VERSION "created by canmatrix"

NS_ :

BS_:

BU_: IPD

BO_ 992 CCU_PTCANFD_100ms_FrP07: 24 Vector__XXX
 SG_ ICCU_100ms_Group07_CRC : 7|8@0+ (1,0) [0|255] "null" IPD
 SG_ ICCU_100ms_Group07_RC : 11|4@0+ (1,0) [0|15] "null" IPD
 SG_ ICCUOnbdChrgrPlugOnV : 12|1@0+ (1,0) [0|1] "null" IPD
 SG_ ICCU_100ms_Group07_Reserved1 : 15|3@0+ (1,0) [0|7] "null" IPD
 SG_ IOnBdChrgrCtrlPilotPWMSts : 18|3@0+ (1,0) [0|7] "null" IPD
 SG_ IOnBdChrgrWkup : 19|1@0+ (1,0) [0|1] "null" IPD
 SG_ IOnBdChrgrSts : 23|4@0+ (1,0) [0|15] "null" IPD
 SG_ IOnbdChrgrAltrCrntInptHVCrntLmt : 31|8@0+ (0.5,0) [0|127.5] "A" IPD
 SG_ ICCU_100ms_Group07_Reserved3 : 32|1@0+ (1,0) [0|1] "null" IPD
 SG_ IOnbdChrgrOtptCrntV : 33|1@0+ (1,0) [0|1] "null" IPD
 SG_ IOnbdChrgrOpngMd : 36|3@0+ (1,0) [0|7] "null" IPD
 SG_ ICCU_100ms_Group07_Reserved2 : 39|3@0+ (1,0) [0|7] "null" IPD
 SG_ IOnBdChrgrAltrCrntInptCrnt : 47|8@0+ (0.2,0) [0|51] "A" IPD
 SG_ IOnBdChrgrAltrCrntInptVol : 55|8@0+ (2,0) [0|510] "V" IPD
 SG_ IOnbdChrgrOtptCrntVal : 63|12@0+ (0.1,-204.8) [-204.8|204.7] "A" IPD
 SG_ ICCU_100ms_Group07_Reserved4 : 66|3@0+ (1,0) [0|7] "null" IPD
 SG_ IOnBdChrgrOtptVolV : 67|1@0+ (1,0) [0|1] "null" IPD
 SG_ IOnbdChrgrOtptVolVal : 79|16@0+ (0.02,0) [0.00|1310.70] "V" IPD
 SG_ IOnBdChrgrL1AltrCrntInptCrnt : 95|8@0+ (0.2,0) [0|51] "A" IPD
 SG_ IOnBdChrgrL1AltrCrntInptVol : 103|8@0+ (2,0) [0|510] "V" IPD
 SG_ IOnBdChrgrL2AltrCrntInptCrnt : 111|8@0+ (0.2,0) [0|51] "A" IPD
 SG_ IOnBdChrgrL2AltrCrntInptVol : 119|8@0+ (2,0) [0|510] "V" IPD
 SG_ IOnBdChrgrL3AltrCrntInptCrnt : 127|8@0+ (0.2,0) [0|51] "A" IPD
 SG_ IOnBdChrgrL3AltrCrntInptVol : 135|8@0+ (2,0) [0|510] "V" IPD
 SG_ ICCUActiveWkup : 136|1@0+ (1,0) [0|1] "null" IPD
 SG_ ICCUonbdChrgrMaxChrgPwr : 143|7@0+ (0.1,0) [0|12.7] "kw" IPD
 SG_ ICCU_100ms_Group07_Reserved5 : 147|4@0+ (1,0) [0|15] "null" IPD
 SG_ ICCUOnbdChrgrPlugOn : 151|4@0+ (1,0) [0|15] "null" IPD
 SG_ ICCU_100ms_Group07_Reserved6 : 155|4@0+ (1,0) [0|15] "null" IPD
 SG_ ICCUOnbdChrgrSpRsn : 159|4@0+ (1,0) [0|15] "null" IPD
 SG_ ICCU_100ms_Group07_Reserved7 : 167|8@0+ (1,0) [0|255] "null" IPD
 SG_ ICCU_100ms_Group07_Reserved9 : 169|2@0+ (1,0) [0|3] "null" IPD
 SG_ IOnBdChrgrLastWkup : 170|1@0+ (1,0) [0|1] "null" IPD
 SG_ ICCU_100ms_Group07_Reserved8 : 175|5@0+ (1,0) [0|31] "null" IPD
 SG_ ICCU_100ms_Group07_Reserved10 : 176|1@0+ (1,0) [0|1] "null" IPD
 SG_ IOnBdChrgrCtrlPilotPWMDuty : 183|7@0+ (1,0) [0|127] "Percent" IPD
 SG_ ICCU_100ms_Group07_Reserved11 : 191|8@0+ (1,0) [0|255] "null" IPD

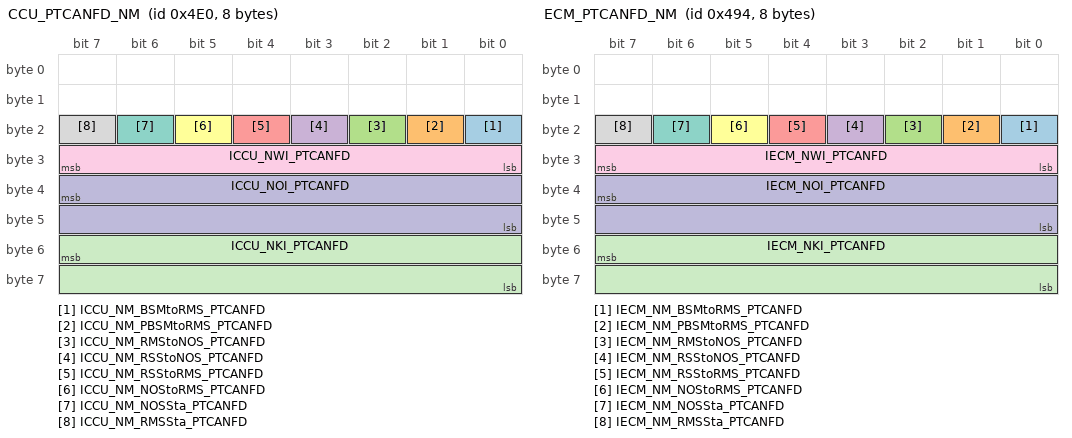
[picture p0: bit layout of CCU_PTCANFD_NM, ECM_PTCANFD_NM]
BO_ 1248 CCU_PTCANFD_NM: 8 Vector__XXX
 SG_ ICCU_NM_BSMtoRMS_PTCANFD : 16|1@0+ (1,0) [0|1] "null" Vector__XXX
 SG_ ICCU_NM_PBSMtoRMS_PTCANFD : 17|1@0+ (1,0) [0|1] "null" Vector__XXX
 SG_ ICCU_NM_RMStoNOS_PTCANFD : 18|1@0+ (1,0) [0|1] "null" Vector__XXX
 SG_ ICCU_NM_RSStoNOS_PTCANFD : 19|1@0+ (1,0) [0|1] "null" Vector__XXX
 SG_ ICCU_NM_RSStoRMS_PTCANFD : 20|1@0+ (1,0) [0|1] "null" Vector__XXX
 SG_ ICCU_NM_NOStoRMS_PTCANFD : 21|1@0+ (1,0) [0|1] "null" Vector__XXX
 SG_ ICCU_NM_NOSSta_PTCANFD : 22|1@0+ (1,0) [0|1] "null" Vector__XXX
 SG_ ICCU_NM_RMSSta_PTCANFD : 23|1@0+ (1,0) [0|1] "null" Vector__XXX
 SG_ ICCU_NWI_PTCANFD : 31|8@0+ (1,0) [0|255] "null" Vector__XXX
 SG_ ICCU_NOI_PTCANFD : 39|16@0+ (1,0) [0|65535] "null" Vector__XXX
 SG_ ICCU_NKI_PTCANFD : 55|16@0+ (1,0) [0|65535] "null" Vector__XXX

BO_ 1172 ECM_PTCANFD_NM: 8 Vector__XXX
 SG_ IECM_NM_BSMtoRMS_PTCANFD : 16|1@0+ (1,0) [0|1] "null" Vector__XXX
 SG_ IECM_NM_PBSMtoRMS_PTCANFD : 17|1@0+ (1,0) [0|1] "null" Vector__XXX
 SG_ IECM_NM_RMStoNOS_PTCANFD : 18|1@0+ (1,0) [0|1] "null" Vector__XXX
 SG_ IECM_NM_RSStoNOS_PTCANFD : 19|1@0+ (1,0) [0|1] "null" Vector__XXX
 SG_ IECM_NM_RSStoRMS_PTCANFD : 20|1@0+ (1,0) [0|1] "null" Vector__XXX
 SG_ IECM_NM_NOStoRMS_PTCANFD : 21|1@0+ (1,0) [0|1] "null" Vector__XXX
 SG_ IECM_NM_NOSSta_PTCANFD : 22|1@0+ (1,0) [0|1] "null" Vector__XXX
 SG_ IECM_NM_RMSSta_PTCANFD : 23|1@0+ (1,0) [0|1] "null" Vector__XXX
 SG_ IECM_NWI_PTCANFD : 31|8@0+ (1,0) [0|255] "null" Vector__XXX
 SG_ IECM_NOI_PTCANFD : 39|16@0+ (1,0) [0|65535] "null" Vector__XXX
 SG_ IECM_NKI_PTCANFD : 55|16@0+ (1,0) [0|65535] "null" Vector__XXX

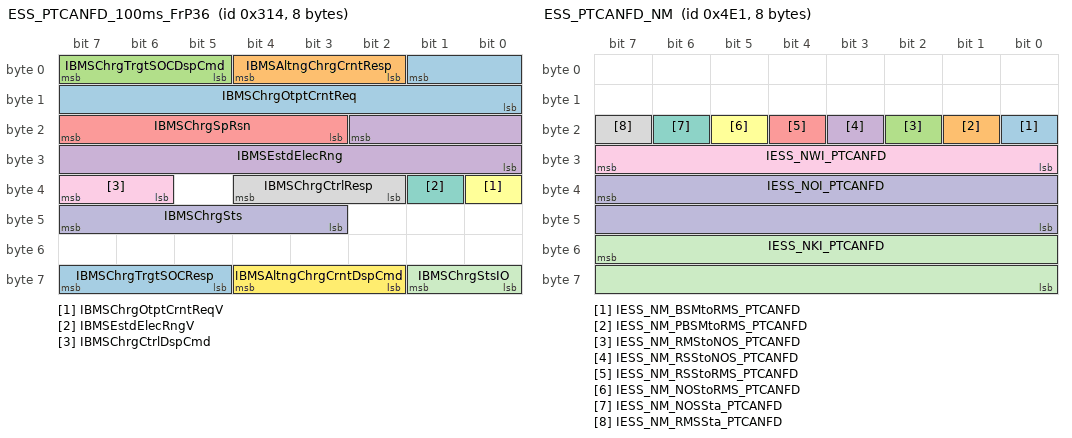
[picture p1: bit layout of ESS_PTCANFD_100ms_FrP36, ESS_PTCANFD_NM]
BO_ 788 ESS_PTCANFD_100ms_FrP36: 8 Vector__XXX
 SG_ IBMSChrgOtptCrntReq : 1|10@0+ (0.5,0) [0|511.5] "A" Vector__XXX
 SG_ IBMSAltngChrgCrntResp : 4|3@0+ (1,0) [0|7] "null" Vector__XXX
 SG_ IBMSChrgTrgtSOCDspCmd : 7|3@0+ (1,0) [0|7] "null" Vector__XXX
 SG_ IBMSEstdElecRng : 18|11@0+ (1,0) [0|2047] "km" Vector__XXX
 SG_ IBMSChrgSpRsn : 23|5@0+ (1,0) [0|31] "null" Vector__XXX
 SG_ IBMSChrgOtptCrntReqV : 32|1@0+ (1,0) [0|1] "null" Vector__XXX
 SG_ IBMSEstdElecRngV : 33|1@0+ (1,0) [0|1] "null" Vector__XXX
 SG_ IBMSChrgCtrlResp : 36|3@0+ (1,0) [0|7] "null" Vector__XXX
 SG_ IBMSChrgCtrlDspCmd : 39|2@0+ (1,0) [0|3] "null" Vector__XXX
 SG_ IBMSChrgSts : 47|5@0+ (1,0) [0|31] "null" IPD
 SG_ IBMSChrgStsIO : 57|2@0+ (1,0) [0|3] "null" Vector__XXX
 SG_ IBMSAltngChrgCrntDspCmd : 60|3@0+ (1,0) [0|7] "null" Vector__XXX
 SG_ IBMSChrgTrgtSOCResp : 63|3@0+ (1,0) [0|7] "null" Vector__XXX

BO_ 1249 ESS_PTCANFD_NM: 8 Vector__XXX
 SG_ IESS_NM_BSMtoRMS_PTCANFD : 16|1@0+ (1,0) [0|1] "null" Vector__XXX
 SG_ IESS_NM_PBSMtoRMS_PTCANFD : 17|1@0+ (1,0) [0|1] "null" Vector__XXX
 SG_ IESS_NM_RMStoNOS_PTCANFD : 18|1@0+ (1,0) [0|1] "null" Vector__XXX
 SG_ IESS_NM_RSStoNOS_PTCANFD : 19|1@0+ (1,0) [0|1] "null" Vector__XXX
 SG_ IESS_NM_RSStoRMS_PTCANFD : 20|1@0+ (1,0) [0|1] "null" Vector__XXX
 SG_ IESS_NM_NOStoRMS_PTCANFD : 21|1@0+ (1,0) [0|1] "null" Vector__XXX
 SG_ IESS_NM_NOSSta_PTCANFD : 22|1@0+ (1,0) [0|1] "null" Vector__XXX
 SG_ IESS_NM_RMSSta_PTCANFD : 23|1@0+ (1,0) [0|1] "null" Vector__XXX
 SG_ IESS_NWI_PTCANFD : 31|8@0+ (1,0) [0|255] "null" Vector__XXX
 SG_ IESS_NOI_PTCANFD : 39|16@0+ (1,0) [0|65535] "null" Vector__XXX
 SG_ IESS_NKI_PTCANFD : 55|16@0+ (1,0) [0|65535] "null" Vector__XXX

BO_ 895 ICBAD_BKPCANFD_100ms_FrP36: 16 IPD
 SG_ INarwSpcAstSwSts : 9|2@0+ (1,0) [0|3] "null" Vector__XXX
 SG_ INarwSpcAstBtnSts : 23|3@0+ (1,0) [0|7] "null" Vector__XXX
 SG_ IIPD_VehLckCtrlReq : 31|8@0+ (1,0) [0|255] "null" Vector__XXX
 SG_ IRembParkngInPrmt : 40|1@0+ (1,0) [0|1] "null" Vector__XXX
 SG_ IRembParkngInMapngResp : 41|1@0+ (1,0) [0|1] "null" Vector__XXX
 SG_ IRembParkngInPrmtSwSts : 49|2@0+ (1,0) [0|3] "null" Vector__XXX
 SG_ IRembParkngInMapngIndcr : 60|3@0+ (1,0) [0|7] "null" Vector__XXX
 SG_ IRembParkngInMapRutSeln : 63|3@0+ (1,0) [0|7] "null" Vector__XXX
 SG_ IIPDMCUTemp : 71|8@0+ (1,-40) [-40|215] "℃" Vector__XXX
 SG_ IIPDWtrClntInltReqFlg : 79|1@0+ (1,0) [0|1] "null" Vector__XXX
 SG_ ITrfGreenLghtActn : 103|1@0+ (1,0) [0|1] "null" Vector__XXX
 SG_ IRembParkngInMapngRutID : 108|5@0+ (1,0) [0|31] "null" Vector__XXX
 SG_ IRembParkngInMapngDistToEnd : 119|9@0+ (0.5,0) [0|255.5] "null" Vector__XXX
 SG_ IRembParkngInMapRutDltSeln : 126|4@0+ (1,0) [0|15] "null" Vector__XXX

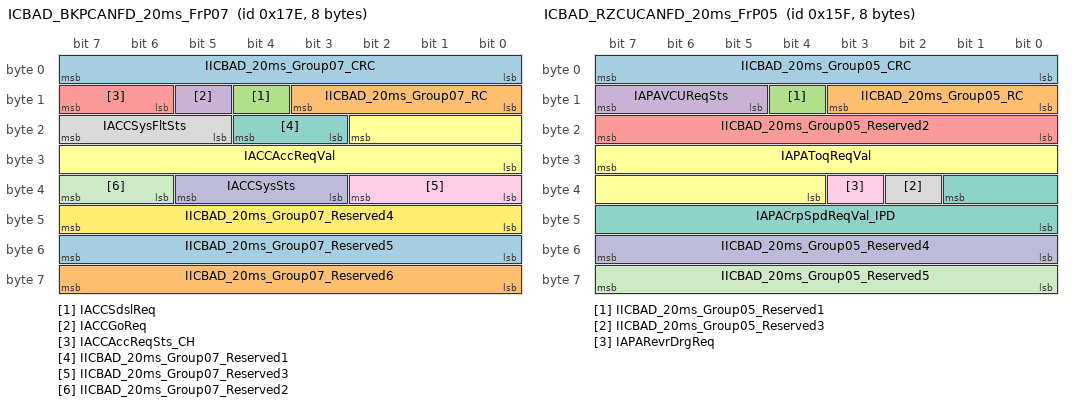
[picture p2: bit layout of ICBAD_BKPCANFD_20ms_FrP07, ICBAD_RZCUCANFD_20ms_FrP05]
BO_ 382 ICBAD_BKPCANFD_20ms_FrP07: 8 IPD
 SG_ IICBAD_20ms_Group07_CRC : 7|8@0+ (1,0) [0|255] "null" Vector__XXX
 SG_ IICBAD_20ms_Group07_RC : 11|4@0+ (1,0) [0|15] "null" Vector__XXX
 SG_ IACCSdslReq : 12|1@0+ (1,0) [0|1] "null" Vector__XXX
 SG_ IACCGoReq : 13|1@0+ (1,0) [0|1] "null" Vector__XXX
 SG_ IACCAccReqSts_CH : 15|2@0+ (1,0) [0|3] "null" Vector__XXX
 SG_ IACCAccReqVal : 18|11@0+ (0.006,-10.278) [-10.278|2.004] "null" Vector__XXX
 SG_ IICBAD_20ms_Group07_Reserved1 : 20|2@0+ (1,0) [0|3] "null" Vector__XXX
 SG_ IACCSysFltSts : 23|3@0+ (1,0) [0|7] "null" Vector__XXX
 SG_ IICBAD_20ms_Group07_Reserved3 : 34|3@0+ (1,0) [0|7] "null" Vector__XXX
 SG_ IACCSysSts : 37|3@0+ (1,0) [0|7] "null" Vector__XXX
 SG_ IICBAD_20ms_Group07_Reserved2 : 39|2@0+ (1,0) [0|3] "null" Vector__XXX
 SG_ IICBAD_20ms_Group07_Reserved4 : 47|8@0+ (1,0) [0|255] "null" Vector__XXX
 SG_ IICBAD_20ms_Group07_Reserved5 : 55|8@0+ (1,0) [0|255] "null" Vector__XXX
 SG_ IICBAD_20ms_Group07_Reserved6 : 63|8@0+ (1,0) [0|255] "null" Vector__XXX

BO_ 736 ICBAD_BKPCANFD_50ms_FrP17: 20 IPD
 SG_ IFrtObsDist : 7|8@0+ (1,0) [0|255] "cm" Vector__XXX
 SG_ IFrtMidRObsRng : 11|4@0+ (1,0) [0|15] "null" Vector__XXX
 SG_ IFrtPDCAudWrnng : 15|4@0+ (1,0) [0|15] "null" Vector__XXX
 SG_ IRrMidLObsRng : 19|4@0+ (1,0) [0|15] "null" Vector__XXX
 SG_ IRLObsRng : 23|4@0+ (1,0) [0|15] "null" Vector__XXX
 SG_ IRrMidRObsRng : 31|4@0+ (1,0) [0|15] "null" Vector__XXX
 SG_ IPDCSysSts : 39|4@0+ (1,0) [0|15] "null" Vector__XXX
 SG_ IRrObsDist : 63|8@0+ (1,0) [0|255] "cm" Vector__XXX
 SG_ IFLSideObsRng : 67|4@0+ (1,0) [0|15] "null" Vector__XXX
 SG_ IRrPDCAudWrnng : 71|4@0+ (1,0) [0|15] "null" Vector__XXX
 SG_ IRLSideObsRng : 75|4@0+ (1,0) [0|15] "null" Vector__XXX
 SG_ IFRSideObsRng : 79|4@0+ (1,0) [0|15] "null" Vector__XXX
 SG_ IUndergndParkngGrgSts : 83|2@0+ (1,0) [0|3] "null" Vector__XXX
 SG_ IRRSideObsRng : 87|4@0+ (1,0) [0|15] "null" Vector__XXX
 SG_ IFLObsRng : 123|4@0+ (1,0) [0|15] "null" Vector__XXX
 SG_ IRRObsRng : 131|4@0+ (1,0) [0|15] "null" Vector__XXX
 SG_ IFRObsRng : 135|4@0+ (1,0) [0|15] "null" Vector__XXX
 SG_ ILADSAFnInd : 139|4@0+ (1,0) [0|15] "null" Vector__XXX
 SG_ IFrtMidLObsRng : 143|4@0+ (1,0) [0|15] "null" Vector__XXX
 SG_ IFRSObsRng : 147|4@0+ (1,0) [0|15] "null" Vector__XXX
 SG_ IFLSObsRng : 151|4@0+ (1,0) [0|15] "null" Vector__XXX
 SG_ IRRSObsRng : 155|4@0+ (1,0) [0|15] "null" Vector__XXX
 SG_ IRLSObsRng : 159|4@0+ (1,0) [0|15] "null" Vector__XXX

BO_ 351 ICBAD_RZCUCANFD_20ms_FrP05: 8 IPD
 SG_ IICBAD_20ms_Group05_CRC : 7|8@0+ (1,0) [0|255] "null" Vector__XXX
 SG_ IICBAD_20ms_Group05_RC : 11|4@0+ (1,0) [0|15] "null" Vector__XXX
 SG_ IICBAD_20ms_Group05_Reserved1 : 12|1@0+ (1,0) [0|1] "null" Vector__XXX
 SG_ IAPAVCUReqSts : 15|3@0+ (1,0) [0|7] "null" Vector__XXX
 SG_ IICBAD_20ms_Group05_Reserved2 : 23|8@0+ (1,0) [0|255] "null" Vector__XXX
 SG_ IAPAToqReqVal : 31|12@0+ (0.5,-848) [-848|1199.5] "Nm" Vector__XXX
 SG_ IAPACrpSpdReqVal_IPD : 33|10@0+ (0.1,0) [0|102.3] "km/h" Vector__XXX
 SG_ IICBAD_20ms_Group05_Reserved3 : 34|1@0+ (1,0) [0|1] "null" Vector__XXX
 SG_ IAPARevrDrgReq : 35|1@0+ (1,0) [0|1] "null" Vector__XXX
 SG_ IICBAD_20ms_Group05_Reserved4 : 55|8@0+ (1,0) [0|255] "null" Vector__XXX
 SG_ IICBAD_20ms_Group05_Reserved5 : 63|8@0+ (1,0) [0|255] "null" Vector__XXX

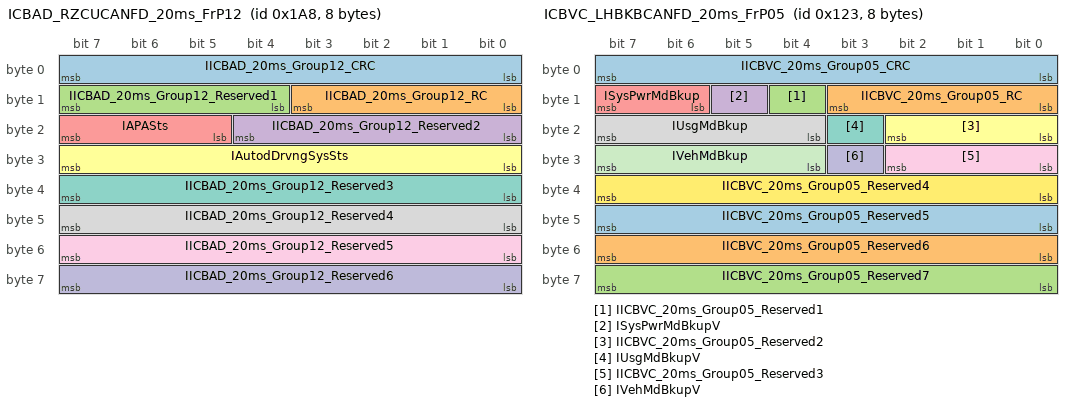
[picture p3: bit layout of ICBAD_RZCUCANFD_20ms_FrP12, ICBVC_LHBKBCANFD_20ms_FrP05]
BO_ 424 ICBAD_RZCUCANFD_20ms_FrP12: 8 IPD
 SG_ IICBAD_20ms_Group12_CRC : 7|8@0+ (1,0) [0|255] "null" Vector__XXX
 SG_ IICBAD_20ms_Group12_RC : 11|4@0+ (1,0) [0|15] "null" Vector__XXX
 SG_ IICBAD_20ms_Group12_Reserved1 : 15|4@0+ (1,0) [0|15] "null" Vector__XXX
 SG_ IICBAD_20ms_Group12_Reserved2 : 20|5@0+ (1,0) [0|31] "null" Vector__XXX
 SG_ IAPASts : 23|3@0+ (1,0) [0|7] "null" Vector__XXX
 SG_ IAutodDrvngSysSts : 31|8@0+ (1,0) [0|255] "null" Vector__XXX
 SG_ IICBAD_20ms_Group12_Reserved3 : 39|8@0+ (1,0) [0|255] "null" Vector__XXX
 SG_ IICBAD_20ms_Group12_Reserved4 : 47|8@0+ (1,0) [0|255] "null" Vector__XXX
 SG_ IICBAD_20ms_Group12_Reserved5 : 55|8@0+ (1,0) [0|255] "null" Vector__XXX
 SG_ IICBAD_20ms_Group12_Reserved6 : 63|8@0+ (1,0) [0|255] "null" Vector__XXX

BO_ 431 ICBAD_RZCUCANFD_20ms_FrP15: 16 IPD
 SG_ IICBAD_20ms_Group15_CRC : 7|8@0+ (1,0) [0|255] "null" Vector__XXX
 SG_ IICBAD_20ms_Group15_RC : 11|4@0+ (1,0) [0|15] "null" Vector__XXX
 SG_ IACCDclReqSts : 13|2@0+ (1,0) [0|3] "null" Vector__XXX
 SG_ IICBAD_20ms_Group15_Reserved1 : 15|2@0+ (1,0) [0|3] "null" Vector__XXX
 SG_ IICBAD_20ms_Group15_Reserved2 : 23|8@0+ (1,0) [0|255] "null" Vector__XXX
 SG_ IACCOtptShaftTotToqReqVal : 31|12@0+ (2,-3392) [-3392|4798] "Nm" Vector__XXX
 SG_ IICBAD_20ms_Group15_Reserved3 : 33|2@0+ (1,0) [0|3] "null" Vector__XXX
 SG_ IACCOtptShaftTotToqReqSts : 35|2@0+ (1,0) [0|3] "null" Vector__XXX
 SG_ IICBAD_20ms_Group15_Reserved4 : 47|8@0+ (1,0) [0|255] "null" Vector__XXX
 SG_ IICBAD_20ms_Group15_Reserved5 : 55|8@0+ (1,0) [0|255] "null" Vector__XXX
 SG_ IICBAD_20ms_Group15_Reserved6 : 63|8@0+ (1,0) [0|255] "null" Vector__XXX
 SG_ IICBAD_20ms_Group15_Reserved7 : 71|8@0+ (1,0) [0|255] "null" Vector__XXX
 SG_ IICBAD_20ms_Group15_Reserved8 : 79|8@0+ (1,0) [0|255] "null" Vector__XXX
 SG_ IICBAD_20ms_Group15_Reserved9 : 87|8@0+ (1,0) [0|255] "null" Vector__XXX
 SG_ IICBAD_20ms_Group15_Reserved10 : 95|8@0+ (1,0) [0|255] "null" Vector__XXX

BO_ 291 ICBVC_LHBKBCANFD_20ms_FrP05: 8 Vector__XXX
 SG_ IICBVC_20ms_Group05_CRC : 7|8@0+ (1,0) [0|255] "null" IPD
 SG_ IICBVC_20ms_Group05_RC : 11|4@0+ (1,0) [0|15] "null" IPD
 SG_ IICBVC_20ms_Group05_Reserved1 : 12|1@0+ (1,0) [0|1] "null" IPD
 SG_ ISysPwrMdBkupV : 13|1@0+ (1,0) [0|1] "null" IPD
 SG_ ISysPwrMdBkup : 15|2@0+ (1,0) [0|3] "null" IPD
 SG_ IICBVC_20ms_Group05_Reserved2 : 18|3@0+ (1,0) [0|7] "null" IPD
 SG_ IUsgMdBkupV : 19|1@0+ (1,0) [0|1] "null" IPD
 SG_ IUsgMdBkup : 23|4@0+ (1,0) [0|15] "null" IPD
 SG_ IICBVC_20ms_Group05_Reserved3 : 26|3@0+ (1,0) [0|7] "null" IPD
 SG_ IVehMdBkupV : 27|1@0+ (1,0) [0|1] "null" IPD
 SG_ IVehMdBkup : 31|4@0+ (1,0) [0|15] "null" IPD
 SG_ IICBVC_20ms_Group05_Reserved4 : 39|8@0+ (1,0) [0|255] "null" IPD
 SG_ IICBVC_20ms_Group05_Reserved5 : 47|8@0+ (1,0) [0|255] "null" IPD
 SG_ IICBVC_20ms_Group05_Reserved6 : 55|8@0+ (1,0) [0|255] "null" IPD
 SG_ IICBVC_20ms_Group05_Reserved7 : 63|8@0+ (1,0) [0|255] "null" IPD

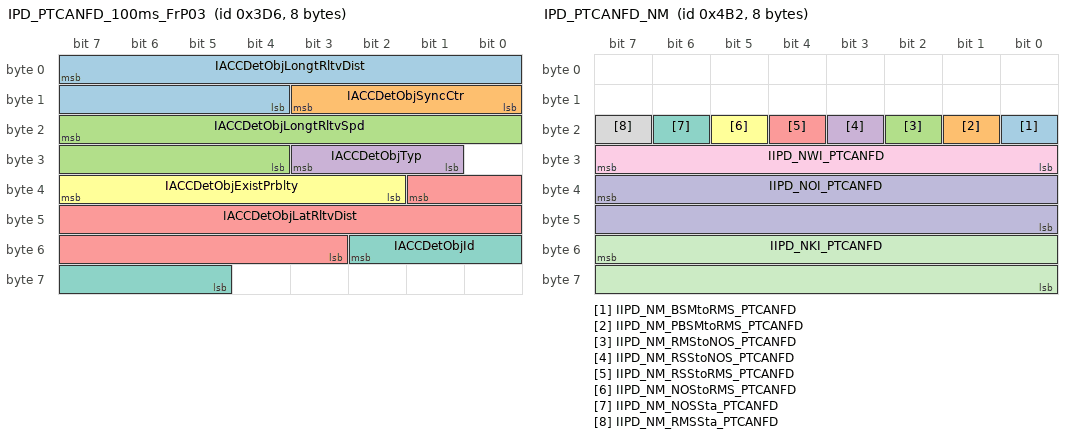
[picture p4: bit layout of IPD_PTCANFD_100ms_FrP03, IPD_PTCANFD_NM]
BO_ 982 IPD_PTCANFD_100ms_FrP03: 8 IPD
 SG_ IACCDetObjLongtRltvDist : 7|12@0+ (0.0625,0) [0.0000|255.9375] "null" Vector__XXX
 SG_ IACCDetObjSyncCtr : 11|4@0+ (1,0) [0|15] "null" Vector__XXX
 SG_ IACCDetObjLongtRltvSpd : 23|12@0+ (0.0625,-128) [-128.0000|127.9375] "null" Vector__XXX
 SG_ IACCDetObjTyp : 27|3@0+ (1,0) [0|7] "null" Vector__XXX
 SG_ IACCDetObjLatRltvDist : 33|15@0+ (0.0078,-128) [-128.0000|127.5826] "null" Vector__XXX
 SG_ IACCDetObjExistPrblty : 39|6@0+ (0.015625,0) [0.000000|0.984375] "null" Vector__XXX
 SG_ IACCDetObjId : 50|6@0+ (1,0) [0|63] "null" Vector__XXX

BO_ 1202 IPD_PTCANFD_NM: 8 IPD
 SG_ IIPD_NM_BSMtoRMS_PTCANFD : 16|1@0+ (1,0) [0|1] "null" Vector__XXX
 SG_ IIPD_NM_PBSMtoRMS_PTCANFD : 17|1@0+ (1,0) [0|1] "null" Vector__XXX
 SG_ IIPD_NM_RMStoNOS_PTCANFD : 18|1@0+ (1,0) [0|1] "null" Vector__XXX
 SG_ IIPD_NM_RSStoNOS_PTCANFD : 19|1@0+ (1,0) [0|1] "null" Vector__XXX
 SG_ IIPD_NM_RSStoRMS_PTCANFD : 20|1@0+ (1,0) [0|1] "null" Vector__XXX
 SG_ IIPD_NM_NOStoRMS_PTCANFD : 21|1@0+ (1,0) [0|1] "null" Vector__XXX
 SG_ IIPD_NM_NOSSta_PTCANFD : 22|1@0+ (1,0) [0|1] "null" Vector__XXX
 SG_ IIPD_NM_RMSSta_PTCANFD : 23|1@0+ (1,0) [0|1] "null" Vector__XXX
 SG_ IIPD_NWI_PTCANFD : 31|8@0+ (1,0) [0|255] "null" Vector__XXX
 SG_ IIPD_NOI_PTCANFD : 39|16@0+ (1,0) [0|65535] "null" Vector__XXX
 SG_ IIPD_NKI_PTCANFD : 55|16@0+ (1,0) [0|65535] "null" Vector__XXX

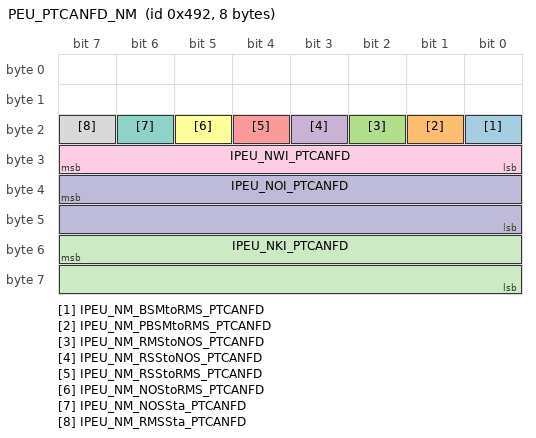
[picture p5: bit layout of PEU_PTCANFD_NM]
BO_ 1170 PEU_PTCANFD_NM: 8 Vector__XXX
 SG_ IPEU_NM_BSMtoRMS_PTCANFD : 16|1@0+ (1,0) [0|1] "null" Vector__XXX
 SG_ IPEU_NM_PBSMtoRMS_PTCANFD : 17|1@0+ (1,0) [0|1] "null" Vector__XXX
 SG_ IPEU_NM_RMStoNOS_PTCANFD : 18|1@0+ (1,0) [0|1] "null" Vector__XXX
 SG_ IPEU_NM_RSStoNOS_PTCANFD : 19|1@0+ (1,0) [0|1] "null" Vector__XXX
 SG_ IPEU_NM_RSStoRMS_PTCANFD : 20|1@0+ (1,0) [0|1] "null" Vector__XXX
 SG_ IPEU_NM_NOStoRMS_PTCANFD : 21|1@0+ (1,0) [0|1] "null" Vector__XXX
 SG_ IPEU_NM_NOSSta_PTCANFD : 22|1@0+ (1,0) [0|1] "null" Vector__XXX
 SG_ IPEU_NM_RMSSta_PTCANFD : 23|1@0+ (1,0) [0|1] "null" Vector__XXX
 SG_ IPEU_NWI_PTCANFD : 31|8@0+ (1,0) [0|255] "null" Vector__XXX
 SG_ IPEU_NOI_PTCANFD : 39|16@0+ (1,0) [0|65535] "null" Vector__XXX
 SG_ IPEU_NKI_PTCANFD : 55|16@0+ (1,0) [0|65535] "null" Vector__XXX

BO_ 983 RZCU_LHBKBCANFD_100ms_FrP38: 20 Vector__XXX
 SG_ ITCSOpngMdVMC : 18|3@0+ (1,0) [0|7] "null" Vector__XXX
 SG_ IPwrLftgtCtrlSrc : 22|4@0+ (1,0) [0|15] "null" Vector__XXX
 SG_ IACMdMotFaltSts_Rr : 27|4@0+ (1,0) [0|15] "null" Vector__XXX
 SG_ IVSEMdVMC : 30|3@0+ (1,0) [0|7] "null" Vector__XXX
 SG_ IACMdMotActPcnt_Rr : 39|8@0+ (1,0) [0|255] "Percent" Vector__XXX
 SG_ IOnBdChrgrSktNgtvSnsrTemV : 42|1@0+ (1,0) [0|1] "null" IPD
 SG_ IOfbdChrgrPstvSktTemV : 47|1@0+ (1,0) [0|1] "null" IPD
 SG_ IPwrLftgtCtrl : 51|4@0+ (1,0) [0|15] "null" Vector__XXX
 SG_ IPwrLftgtThrmlSts : 52|1@0+ (1,0) [0|1] "null" Vector__XXX
 SG_ IPwrLftgtCinchLtchCtrl : 59|1@0+ (1,0) [0|1] "null" Vector__XXX
 SG_ IPwrLftgtCinchLtchSts : 61|2@0+ (1,0) [0|3] "null" Vector__XXX
 SG_ IPwrLftgtCinchLtchThrmlSts : 62|1@0+ (1,0) [0|1] "null" Vector__XXX
 SG_ IPwrLftgtPnchSts : 63|1@0+ (1,0) [0|1] "null" Vector__XXX
 SG_ IOfbdChrgrPstvSktTem : 71|8@0+ (1,-40) [-40|215] "degreeCelsius" IPD
 SG_ IOnBdChrgrSktNgtvSnsrTem : 79|8@0+ (1,-40) [-40|215] "degreeCelsius" IPD
 SG_ IPLGStpReason : 84|3@0+ (1,0) [0|7] "null" Vector__XXX
 SG_ IPwrLftgtFailRmndr : 87|3@0+ (1,0) [0|7] "null" Vector__XXX

CM_ BU_ IPD "Tbox->IBox->iCD->IAM(20200706)
DRE ->20200915->20201126
-";

BA_DEF_ BO_ "FrameTriggeringName" STRING;
BA_DEF_ BO_ "GenMsgCycleTime" INT 0 65535;
BA_DEF_ BO_ "GenMsgSendType" ENUM  "cyclicX","spontanX","cyclicIfActiveX","spontanWithDelay","cyclicAndSpontanX","cyclicAndSpontanWithDelay","spontanWithRepitition","cyclicIfActiveAndSpontanWD","cyclicIfActiveFast","cyclicWithRepeatOnDemand","none";
BA_DEF_ BO_ "GenMsgStartValue" STRING;
BA_DEF_ BO_ "PduName" STRING;
BA_DEF_ BO_ "SystemMessageLongSymbol" STRING;
BA_DEF_ BO_ "VFrameFormat" ENUM  "StandardCAN","ExtendedCAN","reserved","reserved","reserved","reserved","reserved","reserved","reserved","reserved","reserved","reserved","reserved","reserved","StandardCAN_FD","ExtendedCAN_FD";
BA_DEF_ SG_ "CompuMethodName" STRING;
BA_DEF_ SG_ "GenSigStartValue" FLOAT 0 100000000000;
BA_DEF_ SG_ "ISignalName" STRING;
BA_DEF_ SG_ "LongName" STRING;
BA_DEF_ SG_ "SysSignalName" STRING;
BA_DEF_ BU_ "NWM-Knoten" ENUM  "nein","ja";
BA_DEF_ BU_ "NWM-Stationsadresse" HEX 0 63;
BA_DEF_  "BusType" STRING;
BA_ "NWM-Knoten" BU_ IPD 0;
BA_ "NWM-Stationsadresse" BU_ IPD 0;

BA_ "BusType"   "CAN FD";

BA_ "FrameTriggeringName" BO_ 992 "CCU_PTCANFD_100ms_FrP07";
BA_ "GenMsgCycleTime" BO_ 992 100;
BA_ "GenMsgSendType" BO_ 992 0;
BA_ "GenMsgStartValue" BO_ 992 "00e00000e30000000f0000000000000000000f0ffffb01ff";
BA_ "PduName" BO_ 992 "CCU_100ms_PDU07";
BA_ "VFrameFormat" BO_ 992 14;
BA_ "FrameTriggeringName" BO_ 1248 "CCU_PTCANFD_NM";
BA_ "GenMsgSendType" BO_ 1248 1;
BA_ "GenMsgStartValue" BO_ 1248 "0000000000000000";
BA_ "PduName" BO_ 1248 "NmPDU_PTCANFD_CCU";
BA_ "VFrameFormat" BO_ 1248 14;
BA_ "FrameTriggeringName" BO_ 1172 "ECM_PTCANFD_NM";
BA_ "GenMsgSendType" BO_ 1172 1;
BA_ "GenMsgStartValue" BO_ 1172 "0000000000000000";
BA_ "PduName" BO_ 1172 "NmPDU_PTCANFD_ECM";
BA_ "VFrameFormat" BO_ 1172 14;
BA_ "FrameTriggeringName" BO_ 788 "ESS_PTCANFD_100ms_FrP36";
BA_ "GenMsgCycleTime" BO_ 788 100;
BA_ "GenMsgSendType" BO_ 788 0;
BA_ "GenMsgStartValue" BO_ 788 "01ff07fe03000000";
BA_ "PduName" BO_ 788 "ESS_100ms_PDU36";
BA_ "VFrameFormat" BO_ 788 14;
BA_ "FrameTriggeringName" BO_ 1249 "ESS_PTCANFD_NM";
BA_ "GenMsgSendType" BO_ 1249 1;
BA_ "GenMsgStartValue" BO_ 1249 "0000000000000000";
BA_ "PduName" BO_ 1249 "NmPDU_PTCANFD_ESS";
BA_ "VFrameFormat" BO_ 1249 14;
BA_ "FrameTriggeringName" BO_ 895 "ICBAD_BKPCANFD_100ms_FrP36";
BA_ "GenMsgCycleTime" BO_ 895 100;
BA_ "GenMsgSendType" BO_ 895 0;
BA_ "GenMsgStartValue" BO_ 895 "0002000000000100ff00000000000000";
BA_ "PduName" BO_ 895 "ICBAD_100ms_PDU36";
BA_ "VFrameFormat" BO_ 895 14;
BA_ "FrameTriggeringName" BO_ 382 "ICBAD_BKPCANFD_20ms_FrP07";
BA_ "GenMsgCycleTime" BO_ 382 20;
BA_ "GenMsgSendType" BO_ 382 0;
BA_ "GenMsgStartValue" BO_ 382 "00001eb1c7ffffff";
BA_ "PduName" BO_ 382 "ICBAD_20ms_PDU07";
BA_ "VFrameFormat" BO_ 382 14;
BA_ "FrameTriggeringName" BO_ 736 "ICBAD_BKPCANFD_50ms_FrP17";
BA_ "GenMsgCycleTime" BO_ 736 50;
BA_ "GenMsgSendType" BO_ 736 0;
BA_ "GenMsgStartValue" BO_ 736 "0000000000000000000000000000000000000000";
BA_ "PduName" BO_ 736 "ICBAD_50ms_PDU17";
BA_ "VFrameFormat" BO_ 736 14;
BA_ "FrameTriggeringName" BO_ 351 "ICBAD_RZCUCANFD_20ms_FrP05";
BA_ "GenMsgCycleTime" BO_ 351 20;
BA_ "GenMsgSendType" BO_ 351 0;
BA_ "GenMsgStartValue" BO_ 351 "0010ff000400ffff";
BA_ "PduName" BO_ 351 "ICBAD_20ms_PDU05";
BA_ "VFrameFormat" BO_ 351 14;
BA_ "FrameTriggeringName" BO_ 424 "ICBAD_RZCUCANFD_20ms_FrP12";
BA_ "GenMsgCycleTime" BO_ 424 20;
BA_ "GenMsgSendType" BO_ 424 0;
BA_ "GenMsgStartValue" BO_ 424 "00f01f00ffffffff";
BA_ "PduName" BO_ 424 "ICBAD_20ms_PDU12";
BA_ "VFrameFormat" BO_ 424 14;
BA_ "FrameTriggeringName" BO_ 431 "ICBAD_RZCUCANFD_20ms_FrP15";
BA_ "GenMsgCycleTime" BO_ 431 20;
BA_ "GenMsgSendType" BO_ 431 0;
BA_ "GenMsgStartValue" BO_ 431 "00c0ff6a03ffffffffffffff00000000";
BA_ "PduName" BO_ 431 "ICBAD_20ms_PDU15";
BA_ "VFrameFormat" BO_ 431 14;
BA_ "FrameTriggeringName" BO_ 291 "ICBVC_LHBKBCANFD_20ms_FrP05";
BA_ "GenMsgCycleTime" BO_ 291 20;
BA_ "GenMsgSendType" BO_ 291 0;
BA_ "GenMsgStartValue" BO_ 291 "00301707ffffffff";
BA_ "PduName" BO_ 291 "ICBVC_20ms_PDU05";
BA_ "VFrameFormat" BO_ 291 14;
BA_ "FrameTriggeringName" BO_ 982 "IPD_PTCANFD_100ms_FrP03";
BA_ "GenMsgCycleTime" BO_ 982 100;
BA_ "GenMsgSendType" BO_ 982 0;
BA_ "GenMsgStartValue" BO_ 982 "0000000000000000";
BA_ "PduName" BO_ 982 "IPD_100ms_PDU03";
BA_ "VFrameFormat" BO_ 982 14;
BA_ "FrameTriggeringName" BO_ 1202 "IPD_PTCANFD_NM";
BA_ "GenMsgSendType" BO_ 1202 1;
BA_ "GenMsgStartValue" BO_ 1202 "0000000000000000";
BA_ "PduName" BO_ 1202 "NmPDU_PTCANFD_IPD";
BA_ "VFrameFormat" BO_ 1202 14;
BA_ "FrameTriggeringName" BO_ 1170 "PEU_PTCANFD_NM";
BA_ "GenMsgSendType" BO_ 1170 1;
BA_ "GenMsgStartValue" BO_ 1170 "0000000000000000";
BA_ "PduName" BO_ 1170 "NmPDU_PTCANFD_PEU";
BA_ "VFrameFormat" BO_ 1170 14;
BA_ "FrameTriggeringName" BO_ 983 "RZCU_LHBKBCANFD_100ms_FrP38";
BA_ "GenMsgCycleTime" BO_ 983 100;
BA_ "GenMsgSendType" BO_ 983 0;
BA_ "GenMsgStartValue" BO_ 983 "0000000000840000fe0000000000000000000000";
BA_ "PduName" BO_ 983 "RZCU_100ms_PDU38";
BA_ "VFrameFormat" BO_ 983 14;

BA_ "CompuMethodName" SG_ 992 ICCU_100ms_Group07_CRC "CCU_100ms_Group07_CRC";
BA_ "ISignalName" SG_ 992 ICCU_100ms_Group07_CRC "ICCU_100ms_Group07_CRC";
BA_ "SysSignalName" SG_ 992 ICCU_100ms_Group07_CRC "CCU_100ms_Group07_CRC";
BA_ "CompuMethodName" SG_ 992 ICCU_100ms_Group07_RC "CCU_100ms_Group07_RC";
BA_ "ISignalName" SG_ 992 ICCU_100ms_Group07_RC "ICCU_100ms_Group07_RC";
BA_ "SysSignalName" SG_ 992 ICCU_100ms_Group07_RC "CCU_100ms_Group07_RC";
BA_ "CompuMethodName" SG_ 992 ICCUOnbdChrgrPlugOnV "CCUOnbdChrgrPlugOnV";
BA_ "ISignalName" SG_ 992 ICCUOnbdChrgrPlugOnV "ICCUOnbdChrgrPlugOnV";
BA_ "LongName" SG_ 992 ICCUOnbdChrgrPlugOnV "Combined Charging Unit Onboard Charger Plug On Validity";
BA_ "SysSignalName" SG_ 992 ICCUOnbdChrgrPlugOnV "CCUOnbdChrgrPlugOnV";
BA_ "CompuMethodName" SG_ 992 ICCU_100ms_Group07_Reserved1 "CCU_100ms_Group07_Reserved1";
BA_ "GenSigStartValue" SG_ 992 ICCU_100ms_Group07_Reserved1 7;
BA_ "ISignalName" SG_ 992 ICCU_100ms_Group07_Reserved1 "ICCU_100ms_Group07_Reserved1";
BA_ "SysSignalName" SG_ 992 ICCU_100ms_Group07_Reserved1 "CCU_100ms_Group07_Reserved1";
BA_ "CompuMethodName" SG_ 992 IOnBdChrgrCtrlPilotPWMSts "OnBdChrgrCtrlPilotPWMSts";
BA_ "ISignalName" SG_ 992 IOnBdChrgrCtrlPilotPWMSts "IOnBdChrgrCtrlPilotPWMSts";
BA_ "LongName" SG_ 992 IOnBdChrgrCtrlPilotPWMSts "On Board Charger Control Pilot Pulse Width Modulation Status";
BA_ "SysSignalName" SG_ 992 IOnBdChrgrCtrlPilotPWMSts "OnBdChrgrCtrlPilotPWMSts";
BA_ "CompuMethodName" SG_ 992 IOnBdChrgrWkup "OnBdChrgrWkup";
BA_ "ISignalName" SG_ 992 IOnBdChrgrWkup "IOnBdChrgrWkup";
BA_ "LongName" SG_ 992 IOnBdChrgrWkup "On Board Charger Wakeup";
BA_ "SysSignalName" SG_ 992 IOnBdChrgrWkup "OnBdChrgrWkup";
BA_ "CompuMethodName" SG_ 992 IOnBdChrgrSts "OnBdChrgrSts";
BA_ "ISignalName" SG_ 992 IOnBdChrgrSts "IOnBdChrgrSts";
BA_ "LongName" SG_ 992 IOnBdChrgrSts "On Board Charger Status";
BA_ "SysSignalName" SG_ 992 IOnBdChrgrSts "OnBdChrgrSts";
BA_ "CompuMethodName" SG_ 992 IOnbdChrgrAltrCrntInptHVCrntLmt "OnbdChrgrAltrCrntInptHVCrntLmt";
BA_ "ISignalName" SG_ 992 IOnbdChrgrAltrCrntInptHVCrntLmt "IOnbdChrgrAltrCrntInptHVCrntLmt";
BA_ "LongName" SG_ 992 IOnbdChrgrAltrCrntInptHVCrntLmt "Onboard Charger Alternator Current Input High Voltage Current Limit";
BA_ "SysSignalName" SG_ 992 IOnbdChrgrAltrCrntInptHVCrntLmt "OnbdChrgrAltrCrntInptHVCrntLmt";
BA_ "CompuMethodName" SG_ 992 ICCU_100ms_Group07_Reserved3 "CCU_100ms_Group07_Reserved3";
BA_ "GenSigStartValue" SG_ 992 ICCU_100ms_Group07_Reserved3 1;
BA_ "ISignalName" SG_ 992 ICCU_100ms_Group07_Reserved3 "ICCU_100ms_Group07_Reserved3";
BA_ "SysSignalName" SG_ 992 ICCU_100ms_Group07_Reserved3 "CCU_100ms_Group07_Reserved3";
BA_ "CompuMethodName" SG_ 992 IOnbdChrgrOtptCrntV "OnbdChrgrOtptCrntV";
BA_ "GenSigStartValue" SG_ 992 IOnbdChrgrOtptCrntV 1;
BA_ "ISignalName" SG_ 992 IOnbdChrgrOtptCrntV "IOnbdChrgrOtptCrntV";
BA_ "LongName" SG_ 992 IOnbdChrgrOtptCrntV "On Board Charger Output Current Validity";
BA_ "SysSignalName" SG_ 992 IOnbdChrgrOtptCrntV "OnbdChrgrOtptCrntV";
BA_ "CompuMethodName" SG_ 992 IOnbdChrgrOpngMd "OnbdChrgrOpngMd";
BA_ "ISignalName" SG_ 992 IOnbdChrgrOpngMd "IOnbdChrgrOpngMd";
BA_ "LongName" SG_ 992 IOnbdChrgrOpngMd "On Board Charger Operating Mode";
BA_ "SysSignalName" SG_ 992 IOnbdChrgrOpngMd "OnbdChrgrOpngMd";
BA_ "CompuMethodName" SG_ 992 ICCU_100ms_Group07_Reserved2 "CCU_100ms_Group07_Reserved2";
BA_ "GenSigStartValue" SG_ 992 ICCU_100ms_Group07_Reserved2 7;
BA_ "ISignalName" SG_ 992 ICCU_100ms_Group07_Reserved2 "ICCU_100ms_Group07_Reserved2";
BA_ "SysSignalName" SG_ 992 ICCU_100ms_Group07_Reserved2 "CCU_100ms_Group07_Reserved2";
BA_ "CompuMethodName" SG_ 992 IOnBdChrgrAltrCrntInptCrnt "OnBdChrgrAltrCrntInptCrnt";
BA_ "ISignalName" SG_ 992 IOnBdChrgrAltrCrntInptCrnt "IOnBdChrgrAltrCrntInptCrnt";
BA_ "LongName" SG_ 992 IOnBdChrgrAltrCrntInptCrnt "On Board Charger Alternator Current Input Current";
BA_ "SysSignalName" SG_ 992 IOnBdChrgrAltrCrntInptCrnt "OnBdChrgrAltrCrntInptCrnt";
BA_ "CompuMethodName" SG_ 992 IOnBdChrgrAltrCrntInptVol "OnBdChrgrAltrCrntInptVol";
BA_ "ISignalName" SG_ 992 IOnBdChrgrAltrCrntInptVol "IOnBdChrgrAltrCrntInptVol";
BA_ "LongName" SG_ 992 IOnBdChrgrAltrCrntInptVol "On Board Charger Alternator Current Input Voltage";
BA_ "SysSignalName" SG_ 992 IOnBdChrgrAltrCrntInptVol "OnBdChrgrAltrCrntInptVol";
BA_ "CompuMethodName" SG_ 992 IOnbdChrgrOtptCrntVal "OnbdChrgrOtptCrntVal";
BA_ "ISignalName" SG_ 992 IOnbdChrgrOtptCrntVal "IOnbdChrgrOtptCrntVal";
BA_ "LongName" SG_ 992 IOnbdChrgrOtptCrntVal "On Board Charger Output Current Value";
BA_ "SysSignalName" SG_ 992 IOnbdChrgrOtptCrntVal "OnbdChrgrOtptCrntVal";
BA_ "CompuMethodName" SG_ 992 ICCU_100ms_Group07_Reserved4 "CCU_100ms_Group07_Reserved4";
BA_ "GenSigStartValue" SG_ 992 ICCU_100ms_Group07_Reserved4 7;
BA_ "ISignalName" SG_ 992 ICCU_100ms_Group07_Reserved4 "ICCU_100ms_Group07_Reserved4";
BA_ "SysSignalName" SG_ 992 ICCU_100ms_Group07_Reserved4 "CCU_100ms_Group07_Reserved4";
BA_ "CompuMethodName" SG_ 992 IOnBdChrgrOtptVolV "OnBdChrgrOtptVolV";
BA_ "GenSigStartValue" SG_ 992 IOnBdChrgrOtptVolV 1;
BA_ "ISignalName" SG_ 992 IOnBdChrgrOtptVolV "IOnBdChrgrOtptVolV";
BA_ "LongName" SG_ 992 IOnBdChrgrOtptVolV "Onboard Charger Output Voltage Validity";
BA_ "SysSignalName" SG_ 992 IOnBdChrgrOtptVolV "OnBdChrgrOtptVolV";
BA_ "CompuMethodName" SG_ 992 IOnbdChrgrOtptVolVal "OnbdChrgrOtptVolVal";
BA_ "ISignalName" SG_ 992 IOnbdChrgrOtptVolVal "IOnbdChrgrOtptVolVal";
BA_ "LongName" SG_ 992 IOnbdChrgrOtptVolVal "On Board Charger Output Voltage Value";
BA_ "SysSignalName" SG_ 992 IOnbdChrgrOtptVolVal "OnbdChrgrOtptVolVal";
BA_ "CompuMethodName" SG_ 992 IOnBdChrgrL1AltrCrntInptCrnt "OnBdChrgrL1AltrCrntInptCrnt";
BA_ "ISignalName" SG_ 992 IOnBdChrgrL1AltrCrntInptCrnt "IOnBdChrgrL1AltrCrntInptCrnt";
BA_ "LongName" SG_ 992 IOnBdChrgrL1AltrCrntInptCrnt "On Board Charger Live Wire_1 Alternator Current Input Current";
BA_ "SysSignalName" SG_ 992 IOnBdChrgrL1AltrCrntInptCrnt "OnBdChrgrL1AltrCrntInptCrnt";
BA_ "CompuMethodName" SG_ 992 IOnBdChrgrL1AltrCrntInptVol "OnBdChrgrL1AltrCrntInptVol";
BA_ "ISignalName" SG_ 992 IOnBdChrgrL1AltrCrntInptVol "IOnBdChrgrL1AltrCrntInptVol";
BA_ "LongName" SG_ 992 IOnBdChrgrL1AltrCrntInptVol "On Board Charger Live Wire_1 Alternator Current Input Voltage";
BA_ "SysSignalName" SG_ 992 IOnBdChrgrL1AltrCrntInptVol "OnBdChrgrL1AltrCrntInptVol";
BA_ "CompuMethodName" SG_ 992 IOnBdChrgrL2AltrCrntInptCrnt "OnBdChrgrL2AltrCrntInptCrnt";
BA_ "ISignalName" SG_ 992 IOnBdChrgrL2AltrCrntInptCrnt "IOnBdChrgrL2AltrCrntInptCrnt";
BA_ "LongName" SG_ 992 IOnBdChrgrL2AltrCrntInptCrnt "On Board Charger Live Wire_2 Alternator Current Input Current";
BA_ "SysSignalName" SG_ 992 IOnBdChrgrL2AltrCrntInptCrnt "OnBdChrgrL2AltrCrntInptCrnt";
BA_ "CompuMethodName" SG_ 992 IOnBdChrgrL2AltrCrntInptVol "OnBdChrgrL2AltrCrntInptVol";
BA_ "ISignalName" SG_ 992 IOnBdChrgrL2AltrCrntInptVol "IOnBdChrgrL2AltrCrntInptVol";
BA_ "LongName" SG_ 992 IOnBdChrgrL2AltrCrntInptVol "On Board Charger Live Wire_2 Alternator Current Input Voltage";
BA_ "SysSignalName" SG_ 992 IOnBdChrgrL2AltrCrntInptVol "OnBdChrgrL2AltrCrntInptVol";
BA_ "CompuMethodName" SG_ 992 IOnBdChrgrL3AltrCrntInptCrnt "OnBdChrgrL3AltrCrntInptCrnt";
BA_ "ISignalName" SG_ 992 IOnBdChrgrL3AltrCrntInptCrnt "IOnBdChrgrL3AltrCrntInptCrnt";
BA_ "LongName" SG_ 992 IOnBdChrgrL3AltrCrntInptCrnt "On Board Charger Live Wire_3 Alternator Current Input Current";
BA_ "SysSignalName" SG_ 992 IOnBdChrgrL3AltrCrntInptCrnt "OnBdChrgrL3AltrCrntInptCrnt";
BA_ "CompuMethodName" SG_ 992 IOnBdChrgrL3AltrCrntInptVol "OnBdChrgrL3AltrCrntInptVol";
BA_ "ISignalName" SG_ 992 IOnBdChrgrL3AltrCrntInptVol "IOnBdChrgrL3AltrCrntInptVol";
BA_ "LongName" SG_ 992 IOnBdChrgrL3AltrCrntInptVol "On Board Charger Live Wire_3 Alternator Current Input Voltage";
BA_ "SysSignalName" SG_ 992 IOnBdChrgrL3AltrCrntInptVol "OnBdChrgrL3AltrCrntInptVol";
BA_ "CompuMethodName" SG_ 992 ICCUActiveWkup "CCUActiveWkup";
BA_ "ISignalName" SG_ 992 ICCUActiveWkup "ICCUActiveWkup";
BA_ "LongName" SG_ 992 ICCUActiveWkup "CCU Active Wakeup";
BA_ "SysSignalName" SG_ 992 ICCUActiveWkup "CCUActiveWkup";
BA_ "CompuMethodName" SG_ 992 ICCUonbdChrgrMaxChrgPwr "CCUonbdChrgrMaxChrgPwr";
BA_ "ISignalName" SG_ 992 ICCUonbdChrgrMaxChrgPwr "ICCUonbdChrgrMaxChrgPwr";
BA_ "LongName" SG_ 992 ICCUonbdChrgrMaxChrgPwr "Combined Charging Unit Onboard Charger Max Charge Power";
BA_ "SysSignalName" SG_ 992 ICCUonbdChrgrMaxChrgPwr "CCUonbdChrgrMaxChrgPwr";
BA_ "CompuMethodName" SG_ 992 ICCU_100ms_Group07_Reserved5 "CCU_100ms_Group07_Reserved5";
BA_ "GenSigStartValue" SG_ 992 ICCU_100ms_Group07_Reserved5 15;
BA_ "ISignalName" SG_ 992 ICCU_100ms_Group07_Reserved5 "ICCU_100ms_Group07_Reserved5";
BA_ "SysSignalName" SG_ 992 ICCU_100ms_Group07_Reserved5 "CCU_100ms_Group07_Reserved5";
BA_ "CompuMethodName" SG_ 992 ICCUOnbdChrgrPlugOn "CCUOnbdChrgrPlugOn";
BA_ "ISignalName" SG_ 992 ICCUOnbdChrgrPlugOn "ICCUOnbdChrgrPlugOn";
BA_ "LongName" SG_ 992 ICCUOnbdChrgrPlugOn "Ccu On Board Charger Plug On";
BA_ "SysSignalName" SG_ 992 ICCUOnbdChrgrPlugOn "CCUOnbdChrgrPlugOn";
BA_ "CompuMethodName" SG_ 992 ICCU_100ms_Group07_Reserved6 "CCU_100ms_Group07_Reserved6";
BA_ "GenSigStartValue" SG_ 992 ICCU_100ms_Group07_Reserved6 15;
BA_ "ISignalName" SG_ 992 ICCU_100ms_Group07_Reserved6 "ICCU_100ms_Group07_Reserved6";
BA_ "SysSignalName" SG_ 992 ICCU_100ms_Group07_Reserved6 "CCU_100ms_Group07_Reserved6";
BA_ "CompuMethodName" SG_ 992 ICCUOnbdChrgrSpRsn "CCUOnbdChrgrSpRsn";
BA_ "ISignalName" SG_ 992 ICCUOnbdChrgrSpRsn "ICCUOnbdChrgrSpRsn";
BA_ "LongName" SG_ 992 ICCUOnbdChrgrSpRsn "Ccu On Board Charger Stop Reason";
BA_ "SysSignalName" SG_ 992 ICCUOnbdChrgrSpRsn "CCUOnbdChrgrSpRsn";
BA_ "CompuMethodName" SG_ 992 ICCU_100ms_Group07_Reserved7 "CCU_100ms_Group07_Reserved7";
BA_ "GenSigStartValue" SG_ 992 ICCU_100ms_Group07_Reserved7 255;
BA_ "ISignalName" SG_ 992 ICCU_100ms_Group07_Reserved7 "ICCU_100ms_Group07_Reserved7";
BA_ "SysSignalName" SG_ 992 ICCU_100ms_Group07_Reserved7 "CCU_100ms_Group07_Reserved7";
BA_ "CompuMethodName" SG_ 992 ICCU_100ms_Group07_Reserved9 "CCU_100ms_Group07_Reserved9";
BA_ "GenSigStartValue" SG_ 992 ICCU_100ms_Group07_Reserved9 3;
BA_ "ISignalName" SG_ 992 ICCU_100ms_Group07_Reserved9 "ICCU_100ms_Group07_Reserved9";
BA_ "SysSignalName" SG_ 992 ICCU_100ms_Group07_Reserved9 "CCU_100ms_Group07_Reserved9";
BA_ "CompuMethodName" SG_ 992 IOnBdChrgrLastWkup "OnBdChrgrLastWkup";
BA_ "ISignalName" SG_ 992 IOnBdChrgrLastWkup "IOnBdChrgrLastWkup";
BA_ "LongName" SG_ 992 IOnBdChrgrLastWkup "On Board Charger Last Wakeup";
BA_ "SysSignalName" SG_ 992 IOnBdChrgrLastWkup "OnBdChrgrLastWkup";
BA_ "CompuMethodName" SG_ 992 ICCU_100ms_Group07_Reserved8 "CCU_100ms_Group07_Reserved8";
BA_ "GenSigStartValue" SG_ 992 ICCU_100ms_Group07_Reserved8 31;
BA_ "ISignalName" SG_ 992 ICCU_100ms_Group07_Reserved8 "ICCU_100ms_Group07_Reserved8";
BA_ "SysSignalName" SG_ 992 ICCU_100ms_Group07_Reserved8 "CCU_100ms_Group07_Reserved8";
BA_ "CompuMethodName" SG_ 992 ICCU_100ms_Group07_Reserved10 "CCU_100ms_Group07_Reserved10";
BA_ "GenSigStartValue" SG_ 992 ICCU_100ms_Group07_Reserved10 1;
BA_ "ISignalName" SG_ 992 ICCU_100ms_Group07_Reserved10 "ICCU_100ms_Group07_Reserved10";
BA_ "SysSignalName" SG_ 992 ICCU_100ms_Group07_Reserved10 "CCU_100ms_Group07_Reserved10";
BA_ "CompuMethodName" SG_ 992 IOnBdChrgrCtrlPilotPWMDuty "OnBdChrgrCtrlPilotPWMDuty";
BA_ "ISignalName" SG_ 992 IOnBdChrgrCtrlPilotPWMDuty "IOnBdChrgrCtrlPilotPWMDuty";
BA_ "LongName" SG_ 992 IOnBdChrgrCtrlPilotPWMDuty "On Board Charger Control Pilot Pulse Width Modulation Duty";
BA_ "SysSignalName" SG_ 992 IOnBdChrgrCtrlPilotPWMDuty "OnBdChrgrCtrlPilotPWMDuty";
BA_ "CompuMethodName" SG_ 992 ICCU_100ms_Group07_Reserved11 "CCU_100ms_Group07_Reserved11";
BA_ "GenSigStartValue" SG_ 992 ICCU_100ms_Group07_Reserved11 255;
BA_ "ISignalName" SG_ 992 ICCU_100ms_Group07_Reserved11 "ICCU_100ms_Group07_Reserved11";
BA_ "SysSignalName" SG_ 992 ICCU_100ms_Group07_Reserved11 "CCU_100ms_Group07_Reserved11";
BA_ "CompuMethodName" SG_ 1248 ICCU_NM_BSMtoRMS_PTCANFD "CCU_NM_BSMtoRMS_PTCANFD";
BA_ "ISignalName" SG_ 1248 ICCU_NM_BSMtoRMS_PTCANFD "ICCU_NM_BSMtoRMS_PTCANFD";
BA_ "LongName" SG_ 1248 ICCU_NM_BSMtoRMS_PTCANFD "CCU NM BSMtoRMS PTCANFD";
BA_ "SysSignalName" SG_ 1248 ICCU_NM_BSMtoRMS_PTCANFD "CCU_NM_BSMtoRMS_PTCANFD";
BA_ "CompuMethodName" SG_ 1248 ICCU_NM_PBSMtoRMS_PTCANFD "CCU_NM_PBSMtoRMS_PTCANFD";
BA_ "ISignalName" SG_ 1248 ICCU_NM_PBSMtoRMS_PTCANFD "ICCU_NM_PBSMtoRMS_PTCANFD";
BA_ "LongName" SG_ 1248 ICCU_NM_PBSMtoRMS_PTCANFD "CCU NM PBSMtoRMS PTCANFD";
BA_ "SysSignalName" SG_ 1248 ICCU_NM_PBSMtoRMS_PTCANFD "CCU_NM_PBSMtoRMS_PTCANFD";
BA_ "CompuMethodName" SG_ 1248 ICCU_NM_RMStoNOS_PTCANFD "CCU_NM_RMStoNOS_PTCANFD";
BA_ "ISignalName" SG_ 1248 ICCU_NM_RMStoNOS_PTCANFD "ICCU_NM_RMStoNOS_PTCANFD";
BA_ "LongName" SG_ 1248 ICCU_NM_RMStoNOS_PTCANFD "CCU NM RMStoNOS PTCANFD";
BA_ "SysSignalName" SG_ 1248 ICCU_NM_RMStoNOS_PTCANFD "CCU_NM_RMStoNOS_PTCANFD";
BA_ "CompuMethodName" SG_ 1248 ICCU_NM_RSStoNOS_PTCANFD "CCU_NM_RSStoNOS_PTCANFD";
BA_ "ISignalName" SG_ 1248 ICCU_NM_RSStoNOS_PTCANFD "ICCU_NM_RSStoNOS_PTCANFD";
BA_ "LongName" SG_ 1248 ICCU_NM_RSStoNOS_PTCANFD "CCU NM RSStoNOS PTCANFD";
BA_ "SysSignalName" SG_ 1248 ICCU_NM_RSStoNOS_PTCANFD "CCU_NM_RSStoNOS_PTCANFD";
BA_ "CompuMethodName" SG_ 1248 ICCU_NM_RSStoRMS_PTCANFD "CCU_NM_RSStoRMS_PTCANFD";
BA_ "ISignalName" SG_ 1248 ICCU_NM_RSStoRMS_PTCANFD "ICCU_NM_RSStoRMS_PTCANFD";
BA_ "LongName" SG_ 1248 ICCU_NM_RSStoRMS_PTCANFD "CCU NM RSStoRMS PTCANFD";
BA_ "SysSignalName" SG_ 1248 ICCU_NM_RSStoRMS_PTCANFD "CCU_NM_RSStoRMS_PTCANFD";
BA_ "CompuMethodName" SG_ 1248 ICCU_NM_NOStoRMS_PTCANFD "CCU_NM_NOStoRMS_PTCANFD";
BA_ "ISignalName" SG_ 1248 ICCU_NM_NOStoRMS_PTCANFD "ICCU_NM_NOStoRMS_PTCANFD";
BA_ "LongName" SG_ 1248 ICCU_NM_NOStoRMS_PTCANFD "CCU NM NOStoRMS PTCANFD";
BA_ "SysSignalName" SG_ 1248 ICCU_NM_NOStoRMS_PTCANFD "CCU_NM_NOStoRMS_PTCANFD";
BA_ "CompuMethodName" SG_ 1248 ICCU_NM_NOSSta_PTCANFD "CCU_NM_NOSSta_PTCANFD";
BA_ "ISignalName" SG_ 1248 ICCU_NM_NOSSta_PTCANFD "ICCU_NM_NOSSta_PTCANFD";
BA_ "LongName" SG_ 1248 ICCU_NM_NOSSta_PTCANFD "CCU NM NOSSta PTCANFD";
BA_ "SysSignalName" SG_ 1248 ICCU_NM_NOSSta_PTCANFD "CCU_NM_NOSSta_PTCANFD";
BA_ "CompuMethodName" SG_ 1248 ICCU_NM_RMSSta_PTCANFD "CCU_NM_RMSSta_PTCANFD";
BA_ "ISignalName" SG_ 1248 ICCU_NM_RMSSta_PTCANFD "ICCU_NM_RMSSta_PTCANFD";
BA_ "LongName" SG_ 1248 ICCU_NM_RMSSta_PTCANFD "CCU NM RMSSta PTCANFD";
BA_ "SysSignalName" SG_ 1248 ICCU_NM_RMSSta_PTCANFD "CCU_NM_RMSSta_PTCANFD";
BA_ "CompuMethodName" SG_ 1248 ICCU_NWI_PTCANFD "CCU_NWI_PTCANFD";
BA_ "ISignalName" SG_ 1248 ICCU_NWI_PTCANFD "ICCU_NWI_PTCANFD";
BA_ "LongName" SG_ 1248 ICCU_NWI_PTCANFD "CCU PTCANFD Network Wakeup Indication";
BA_ "SysSignalName" SG_ 1248 ICCU_NWI_PTCANFD "CCU_NWI_PTCANFD";
BA_ "CompuMethodName" SG_ 1248 ICCU_NOI_PTCANFD "CCU_NOI_PTCANFD";
BA_ "ISignalName" SG_ 1248 ICCU_NOI_PTCANFD "ICCU_NOI_PTCANFD";
BA_ "LongName" SG_ 1248 ICCU_NOI_PTCANFD "CCU PTCANFD Network Operation Indication";
BA_ "SysSignalName" SG_ 1248 ICCU_NOI_PTCANFD "CCU_NOI_PTCANFD";
BA_ "CompuMethodName" SG_ 1248 ICCU_NKI_PTCANFD "CCU_NKI_PTCANFD";
BA_ "ISignalName" SG_ 1248 ICCU_NKI_PTCANFD "ICCU_NKI_PTCANFD";
BA_ "LongName" SG_ 1248 ICCU_NKI_PTCANFD "CCU PTCANFD Network Keep Indication";
BA_ "SysSignalName" SG_ 1248 ICCU_NKI_PTCANFD "CCU_NKI_PTCANFD";
BA_ "CompuMethodName" SG_ 1172 IECM_NM_BSMtoRMS_PTCANFD "ECM_NM_BSMtoRMS_PTCANFD";
BA_ "ISignalName" SG_ 1172 IECM_NM_BSMtoRMS_PTCANFD "IECM_NM_BSMtoRMS_PTCANFD";
BA_ "LongName" SG_ 1172 IECM_NM_BSMtoRMS_PTCANFD "ECM_NM_BSMtoRMS_PTCANFD";
BA_ "SysSignalName" SG_ 1172 IECM_NM_BSMtoRMS_PTCANFD "ECM_NM_BSMtoRMS_PTCANFD";
BA_ "CompuMethodName" SG_ 1172 IECM_NM_PBSMtoRMS_PTCANFD "ECM_NM_PBSMtoRMS_PTCANFD";
BA_ "ISignalName" SG_ 1172 IECM_NM_PBSMtoRMS_PTCANFD "IECM_NM_PBSMtoRMS_PTCANFD";
BA_ "LongName" SG_ 1172 IECM_NM_PBSMtoRMS_PTCANFD "ECM_NM_PBSMtoRMS_PTCANFD";
BA_ "SysSignalName" SG_ 1172 IECM_NM_PBSMtoRMS_PTCANFD "ECM_NM_PBSMtoRMS_PTCANFD";
BA_ "CompuMethodName" SG_ 1172 IECM_NM_RMStoNOS_PTCANFD "ECM_NM_RMStoNOS_PTCANFD";
BA_ "ISignalName" SG_ 1172 IECM_NM_RMStoNOS_PTCANFD "IECM_NM_RMStoNOS_PTCANFD";
BA_ "LongName" SG_ 1172 IECM_NM_RMStoNOS_PTCANFD "ECM_NM_RMStoNOS_PTCANFD";
BA_ "SysSignalName" SG_ 1172 IECM_NM_RMStoNOS_PTCANFD "ECM_NM_RMStoNOS_PTCANFD";
BA_ "CompuMethodName" SG_ 1172 IECM_NM_RSStoNOS_PTCANFD "ECM_NM_RSStoNOS_PTCANFD";
BA_ "ISignalName" SG_ 1172 IECM_NM_RSStoNOS_PTCANFD "IECM_NM_RSStoNOS_PTCANFD";
BA_ "LongName" SG_ 1172 IECM_NM_RSStoNOS_PTCANFD "ECM_NM_RSStoNOS_PTCANFD";
BA_ "SysSignalName" SG_ 1172 IECM_NM_RSStoNOS_PTCANFD "ECM_NM_RSStoNOS_PTCANFD";
BA_ "CompuMethodName" SG_ 1172 IECM_NM_RSStoRMS_PTCANFD "ECM_NM_RSStoRMS_PTCANFD";
BA_ "ISignalName" SG_ 1172 IECM_NM_RSStoRMS_PTCANFD "IECM_NM_RSStoRMS_PTCANFD";
BA_ "LongName" SG_ 1172 IECM_NM_RSStoRMS_PTCANFD "ECM_NM_RSStoRMS_PTCANFD";
BA_ "SysSignalName" SG_ 1172 IECM_NM_RSStoRMS_PTCANFD "ECM_NM_RSStoRMS_PTCANFD";
BA_ "CompuMethodName" SG_ 1172 IECM_NM_NOStoRMS_PTCANFD "ECM_NM_NOStoRMS_PTCANFD";
BA_ "ISignalName" SG_ 1172 IECM_NM_NOStoRMS_PTCANFD "IECM_NM_NOStoRMS_PTCANFD";
BA_ "LongName" SG_ 1172 IECM_NM_NOStoRMS_PTCANFD "ECM_NM_NOStoRMS_PTCANFD";
BA_ "SysSignalName" SG_ 1172 IECM_NM_NOStoRMS_PTCANFD "ECM_NM_NOStoRMS_PTCANFD";
BA_ "CompuMethodName" SG_ 1172 IECM_NM_NOSSta_PTCANFD "ECM_NM_NOSSta_PTCANFD";
BA_ "ISignalName" SG_ 1172 IECM_NM_NOSSta_PTCANFD "IECM_NM_NOSSta_PTCANFD";
BA_ "LongName" SG_ 1172 IECM_NM_NOSSta_PTCANFD "ECM_NM_NOSSta_PTCANFD";
BA_ "SysSignalName" SG_ 1172 IECM_NM_NOSSta_PTCANFD "ECM_NM_NOSSta_PTCANFD";
BA_ "CompuMethodName" SG_ 1172 IECM_NM_RMSSta_PTCANFD "ECM_NM_RMSSta_PTCANFD";
BA_ "ISignalName" SG_ 1172 IECM_NM_RMSSta_PTCANFD "IECM_NM_RMSSta_PTCANFD";
BA_ "LongName" SG_ 1172 IECM_NM_RMSSta_PTCANFD "ECM_NM_RMSSta_PTCANFD";
BA_ "SysSignalName" SG_ 1172 IECM_NM_RMSSta_PTCANFD "ECM_NM_RMSSta_PTCANFD";
BA_ "CompuMethodName" SG_ 1172 IECM_NWI_PTCANFD "ECM_NWI_PTCANFD";
BA_ "ISignalName" SG_ 1172 IECM_NWI_PTCANFD "IECM_NWI_PTCANFD";
BA_ "LongName" SG_ 1172 IECM_NWI_PTCANFD "ECM PTCANFD Network_Wakeup_Indication";
BA_ "SysSignalName" SG_ 1172 IECM_NWI_PTCANFD "ECM_NWI_PTCANFD";
BA_ "CompuMethodName" SG_ 1172 IECM_NOI_PTCANFD "ECM_NOI_PTCANFD";
BA_ "ISignalName" SG_ 1172 IECM_NOI_PTCANFD "IECM_NOI_PTCANFD";
BA_ "LongName" SG_ 1172 IECM_NOI_PTCANFD "ECM PTCANFD Network Operation Indication";
BA_ "SysSignalName" SG_ 1172 IECM_NOI_PTCANFD "ECM_NOI_PTCANFD";
BA_ "CompuMethodName" SG_ 1172 IECM_NKI_PTCANFD "ECM_NKI_PTCANFD";
BA_ "ISignalName" SG_ 1172 IECM_NKI_PTCANFD "IECM_NKI_PTCANFD";
BA_ "LongName" SG_ 1172 IECM_NKI_PTCANFD "ECM PTCANFD Network Keep Indication";
BA_ "SysSignalName" SG_ 1172 IECM_NKI_PTCANFD "ECM_NKI_PTCANFD";
BA_ "CompuMethodName" SG_ 788 IBMSChrgOtptCrntReq "BMSChrgOtptCrntReq";
BA_ "GenSigStartValue" SG_ 788 IBMSChrgOtptCrntReq 511;
BA_ "ISignalName" SG_ 788 IBMSChrgOtptCrntReq "IBMSChrgOtptCrntReq";
BA_ "LongName" SG_ 788 IBMSChrgOtptCrntReq "Battery Management System Charge Output Current Request";
BA_ "SysSignalName" SG_ 788 IBMSChrgOtptCrntReq "BMSChrgOtptCrntReq";
BA_ "CompuMethodName" SG_ 788 IBMSAltngChrgCrntResp "BMSAltngChrgCrntResp";
BA_ "ISignalName" SG_ 788 IBMSAltngChrgCrntResp "IBMSAltngChrgCrntResp";
BA_ "LongName" SG_ 788 IBMSAltngChrgCrntResp "Battery Management System Alternating Charge Current Response";
BA_ "SysSignalName" SG_ 788 IBMSAltngChrgCrntResp "BMSAltngChrgCrntResp";
BA_ "CompuMethodName" SG_ 788 IBMSChrgTrgtSOCDspCmd "BMSChrgTrgtSOCDspCmd";
BA_ "ISignalName" SG_ 788 IBMSChrgTrgtSOCDspCmd "IBMSChrgTrgtSOCDspCmd";
BA_ "LongName" SG_ 788 IBMSChrgTrgtSOCDspCmd "Battery Management System Onboard Charge Target State Of Charge Display Command";
BA_ "SysSignalName" SG_ 788 IBMSChrgTrgtSOCDspCmd "BMSChrgTrgtSOCDspCmd";
BA_ "CompuMethodName" SG_ 788 IBMSEstdElecRng "BMSEstdElecRng";
BA_ "GenSigStartValue" SG_ 788 IBMSEstdElecRng 2046;
BA_ "ISignalName" SG_ 788 IBMSEstdElecRng "IBMSEstdElecRng";
BA_ "LongName" SG_ 788 IBMSEstdElecRng "Battery Management System Estimated Electric Range";
BA_ "SysSignalName" SG_ 788 IBMSEstdElecRng "BMSEstdElecRng";
BA_ "CompuMethodName" SG_ 788 IBMSChrgSpRsn "BMSChrgSpRsn";
BA_ "ISignalName" SG_ 788 IBMSChrgSpRsn "IBMSChrgSpRsn";
BA_ "LongName" SG_ 788 IBMSChrgSpRsn "Battery Management System Charge Stop Reason";
BA_ "SysSignalName" SG_ 788 IBMSChrgSpRsn "BMSChrgSpRsn";
BA_ "CompuMethodName" SG_ 788 IBMSChrgOtptCrntReqV "BMSChrgOtptCrntReqV";
BA_ "GenSigStartValue" SG_ 788 IBMSChrgOtptCrntReqV 1;
BA_ "ISignalName" SG_ 788 IBMSChrgOtptCrntReqV "IBMSChrgOtptCrntReqV";
BA_ "LongName" SG_ 788 IBMSChrgOtptCrntReqV "Battery Management System Charge Output Current Request Validity";
BA_ "SysSignalName" SG_ 788 IBMSChrgOtptCrntReqV "BMSChrgOtptCrntReqV";
BA_ "CompuMethodName" SG_ 788 IBMSEstdElecRngV "BMSEstdElecRngV";
BA_ "GenSigStartValue" SG_ 788 IBMSEstdElecRngV 1;
BA_ "ISignalName" SG_ 788 IBMSEstdElecRngV "IBMSEstdElecRngV";
BA_ "LongName" SG_ 788 IBMSEstdElecRngV "Battery Management System Estimated Electric Range Validity";
BA_ "SysSignalName" SG_ 788 IBMSEstdElecRngV "BMSEstdElecRngV";
BA_ "CompuMethodName" SG_ 788 IBMSChrgCtrlResp "BMSChrgCtrlResp";
BA_ "ISignalName" SG_ 788 IBMSChrgCtrlResp "IBMSChrgCtrlResp";
BA_ "LongName" SG_ 788 IBMSChrgCtrlResp "Battery Management System Charge Control Response";
BA_ "SysSignalName" SG_ 788 IBMSChrgCtrlResp "BMSChrgCtrlResp";
BA_ "CompuMethodName" SG_ 788 IBMSChrgCtrlDspCmd "BMSChrgCtrlDspCmd";
BA_ "ISignalName" SG_ 788 IBMSChrgCtrlDspCmd "IBMSChrgCtrlDspCmd";
BA_ "LongName" SG_ 788 IBMSChrgCtrlDspCmd "Battery Management System Charge Control Display Command";
BA_ "SysSignalName" SG_ 788 IBMSChrgCtrlDspCmd "BMSChrgCtrlDspCmd";
BA_ "CompuMethodName" SG_ 788 IBMSChrgSts "BMSChrgSts";
BA_ "ISignalName" SG_ 788 IBMSChrgSts "IBMSChrgSts";
BA_ "LongName" SG_ 788 IBMSChrgSts "Battery Management System Charge Status";
BA_ "SysSignalName" SG_ 788 IBMSChrgSts "BMSChrgSts";
BA_ "CompuMethodName" SG_ 788 IBMSChrgStsIO "BMSChrgStsIO";
BA_ "ISignalName" SG_ 788 IBMSChrgStsIO "IBMSChrgStsIO";
BA_ "LongName" SG_ 788 IBMSChrgStsIO "Battery Management System Charge Status Indication On";
BA_ "SysSignalName" SG_ 788 IBMSChrgStsIO "BMSChrgStsIO";
BA_ "CompuMethodName" SG_ 788 IBMSAltngChrgCrntDspCmd "BMSAltngChrgCrntDspCmd";
BA_ "ISignalName" SG_ 788 IBMSAltngChrgCrntDspCmd "IBMSAltngChrgCrntDspCmd";
BA_ "LongName" SG_ 788 IBMSAltngChrgCrntDspCmd "Battery Management System Alternating Charge Current Display Command";
BA_ "SysSignalName" SG_ 788 IBMSAltngChrgCrntDspCmd "BMSAltngChrgCrntDspCmd";
BA_ "CompuMethodName" SG_ 788 IBMSChrgTrgtSOCResp "BMSChrgTrgtSOCResp";
BA_ "ISignalName" SG_ 788 IBMSChrgTrgtSOCResp "IBMSChrgTrgtSOCResp";
BA_ "LongName" SG_ 788 IBMSChrgTrgtSOCResp "Battery Management System Charge Target Soc Response";
BA_ "SysSignalName" SG_ 788 IBMSChrgTrgtSOCResp "BMSChrgTrgtSOCResp";
BA_ "CompuMethodName" SG_ 1249 IESS_NM_BSMtoRMS_PTCANFD "ESS_NM_BSMtoRMS_PTCANFD";
BA_ "ISignalName" SG_ 1249 IESS_NM_BSMtoRMS_PTCANFD "IESS_NM_BSMtoRMS_PTCANFD";
BA_ "LongName" SG_ 1249 IESS_NM_BSMtoRMS_PTCANFD "ESS NM BSMtoRMS PTCANFD";
BA_ "SysSignalName" SG_ 1249 IESS_NM_BSMtoRMS_PTCANFD "ESS_NM_BSMtoRMS_PTCANFD";
BA_ "CompuMethodName" SG_ 1249 IESS_NM_PBSMtoRMS_PTCANFD "ESS_NM_PBSMtoRMS_PTCANFD";
BA_ "ISignalName" SG_ 1249 IESS_NM_PBSMtoRMS_PTCANFD "IESS_NM_PBSMtoRMS_PTCANFD";
BA_ "LongName" SG_ 1249 IESS_NM_PBSMtoRMS_PTCANFD "ESS NM PBSMtoRMS PTCANFD";
BA_ "SysSignalName" SG_ 1249 IESS_NM_PBSMtoRMS_PTCANFD "ESS_NM_PBSMtoRMS_PTCANFD";
BA_ "CompuMethodName" SG_ 1249 IESS_NM_RMStoNOS_PTCANFD "ESS_NM_RMStoNOS_PTCANFD";
BA_ "ISignalName" SG_ 1249 IESS_NM_RMStoNOS_PTCANFD "IESS_NM_RMStoNOS_PTCANFD";
BA_ "LongName" SG_ 1249 IESS_NM_RMStoNOS_PTCANFD "ESS NM RMStoNOS PTCANFD";
BA_ "SysSignalName" SG_ 1249 IESS_NM_RMStoNOS_PTCANFD "ESS_NM_RMStoNOS_PTCANFD";
BA_ "CompuMethodName" SG_ 1249 IESS_NM_RSStoNOS_PTCANFD "ESS_NM_RSStoNOS_PTCANFD";
BA_ "ISignalName" SG_ 1249 IESS_NM_RSStoNOS_PTCANFD "IESS_NM_RSStoNOS_PTCANFD";
BA_ "LongName" SG_ 1249 IESS_NM_RSStoNOS_PTCANFD "ESS NM RSStoNOS PTCANFD";
BA_ "SysSignalName" SG_ 1249 IESS_NM_RSStoNOS_PTCANFD "ESS_NM_RSStoNOS_PTCANFD";
BA_ "CompuMethodName" SG_ 1249 IESS_NM_RSStoRMS_PTCANFD "ESS_NM_RSStoRMS_PTCANFD";
BA_ "ISignalName" SG_ 1249 IESS_NM_RSStoRMS_PTCANFD "IESS_NM_RSStoRMS_PTCANFD";
BA_ "LongName" SG_ 1249 IESS_NM_RSStoRMS_PTCANFD "ESS NM RSStoRMS PTCANFD";
BA_ "SysSignalName" SG_ 1249 IESS_NM_RSStoRMS_PTCANFD "ESS_NM_RSStoRMS_PTCANFD";
BA_ "CompuMethodName" SG_ 1249 IESS_NM_NOStoRMS_PTCANFD "ESS_NM_NOStoRMS_PTCANFD";
BA_ "ISignalName" SG_ 1249 IESS_NM_NOStoRMS_PTCANFD "IESS_NM_NOStoRMS_PTCANFD";
BA_ "LongName" SG_ 1249 IESS_NM_NOStoRMS_PTCANFD "ESS NM NOStoRMS PTCANFD";
BA_ "SysSignalName" SG_ 1249 IESS_NM_NOStoRMS_PTCANFD "ESS_NM_NOStoRMS_PTCANFD";
BA_ "CompuMethodName" SG_ 1249 IESS_NM_NOSSta_PTCANFD "ESS_NM_NOSSta_PTCANFD";
BA_ "ISignalName" SG_ 1249 IESS_NM_NOSSta_PTCANFD "IESS_NM_NOSSta_PTCANFD";
BA_ "LongName" SG_ 1249 IESS_NM_NOSSta_PTCANFD "ESS NM NOSSta PTCANFD";
BA_ "SysSignalName" SG_ 1249 IESS_NM_NOSSta_PTCANFD "ESS_NM_NOSSta_PTCANFD";
BA_ "CompuMethodName" SG_ 1249 IESS_NM_RMSSta_PTCANFD "ESS_NM_RMSSta_PTCANFD";
BA_ "ISignalName" SG_ 1249 IESS_NM_RMSSta_PTCANFD "IESS_NM_RMSSta_PTCANFD";
BA_ "LongName" SG_ 1249 IESS_NM_RMSSta_PTCANFD "ESS NM RMSSta PTCANFD";
BA_ "SysSignalName" SG_ 1249 IESS_NM_RMSSta_PTCANFD "ESS_NM_RMSSta_PTCANFD";
BA_ "CompuMethodName" SG_ 1249 IESS_NWI_PTCANFD "ESS_NWI_PTCANFD";
BA_ "ISignalName" SG_ 1249 IESS_NWI_PTCANFD "IESS_NWI_PTCANFD";
BA_ "LongName" SG_ 1249 IESS_NWI_PTCANFD "ESS PTCANFD Network Wakeup Indication";
BA_ "SysSignalName" SG_ 1249 IESS_NWI_PTCANFD "ESS_NWI_PTCANFD";
BA_ "CompuMethodName" SG_ 1249 IESS_NOI_PTCANFD "ESS_NOI_PTCANFD";
BA_ "ISignalName" SG_ 1249 IESS_NOI_PTCANFD "IESS_NOI_PTCANFD";
BA_ "LongName" SG_ 1249 IESS_NOI_PTCANFD "ESS PTCANFD Network Operation Indication";
BA_ "SysSignalName" SG_ 1249 IESS_NOI_PTCANFD "ESS_NOI_PTCANFD";
BA_ "CompuMethodName" SG_ 1249 IESS_NKI_PTCANFD "ESS_NKI_PTCANFD";
BA_ "ISignalName" SG_ 1249 IESS_NKI_PTCANFD "IESS_NKI_PTCANFD";
BA_ "LongName" SG_ 1249 IESS_NKI_PTCANFD "ESS PTCANFD Network Keep Indication";
BA_ "SysSignalName" SG_ 1249 IESS_NKI_PTCANFD "ESS_NKI_PTCANFD";
BA_ "CompuMethodName" SG_ 895 INarwSpcAstSwSts "NarwSpcAstSwSts";
BA_ "GenSigStartValue" SG_ 895 INarwSpcAstSwSts 2;
BA_ "ISignalName" SG_ 895 INarwSpcAstSwSts "INarwSpcAstSwSts";
BA_ "LongName" SG_ 895 INarwSpcAstSwSts "Narrow Space Assist Switch Status";
BA_ "SysSignalName" SG_ 895 INarwSpcAstSwSts "NarwSpcAstSwSts";
BA_ "CompuMethodName" SG_ 895 INarwSpcAstBtnSts "NarwSpcAstBtnSts";
BA_ "ISignalName" SG_ 895 INarwSpcAstBtnSts "INarwSpcAstBtnSts";
BA_ "LongName" SG_ 895 INarwSpcAstBtnSts "Narrow Space Assist Button Status";
BA_ "SysSignalName" SG_ 895 INarwSpcAstBtnSts "NarwSpcAstBtnSts";
BA_ "CompuMethodName" SG_ 895 IIPD_VehLckCtrlReq "IPD_VehLckCtrlReq";
BA_ "ISignalName" SG_ 895 IIPD_VehLckCtrlReq "IIPD_VehLckCtrlReq";
BA_ "LongName" SG_ 895 IIPD_VehLckCtrlReq "Vehicle lock request";
BA_ "SysSignalName" SG_ 895 IIPD_VehLckCtrlReq "IPD_VehLckCtrlReq";
BA_ "CompuMethodName" SG_ 895 IRembParkngInPrmt "RembParkngInPrmt";
BA_ "ISignalName" SG_ 895 IRembParkngInPrmt "IRembParkngInPrmt";
BA_ "LongName" SG_ 895 IRembParkngInPrmt "Remember Parking In Prompt";
BA_ "SysSignalName" SG_ 895 IRembParkngInPrmt "RembParkngInPrmt";
BA_ "CompuMethodName" SG_ 895 IRembParkngInMapngResp "RembParkngInMapngResp";
BA_ "ISignalName" SG_ 895 IRembParkngInMapngResp "IRembParkngInMapngResp";
BA_ "LongName" SG_ 895 IRembParkngInMapngResp "Remember Parking In Mapping Response";
BA_ "SysSignalName" SG_ 895 IRembParkngInMapngResp "RembParkngInMapngResp";
BA_ "CompuMethodName" SG_ 895 IRembParkngInPrmtSwSts "RembParkngInPrmtSwSts";
BA_ "GenSigStartValue" SG_ 895 IRembParkngInPrmtSwSts 1;
BA_ "ISignalName" SG_ 895 IRembParkngInPrmtSwSts "IRembParkngInPrmtSwSts";
BA_ "LongName" SG_ 895 IRembParkngInPrmtSwSts "Remember Parking In Prompt Switch Status";
BA_ "SysSignalName" SG_ 895 IRembParkngInPrmtSwSts "RembParkngInPrmtSwSts";
BA_ "CompuMethodName" SG_ 895 IRembParkngInMapngIndcr "RembParkngInMapngIndcr";
BA_ "ISignalName" SG_ 895 IRembParkngInMapngIndcr "IRembParkngInMapngIndcr";
BA_ "LongName" SG_ 895 IRembParkngInMapngIndcr "Remember Parking In Mapping Indicator";
BA_ "SysSignalName" SG_ 895 IRembParkngInMapngIndcr "RembParkngInMapngIndcr";
BA_ "CompuMethodName" SG_ 895 IRembParkngInMapRutSeln "RembParkngInMapRutSeln";
BA_ "ISignalName" SG_ 895 IRembParkngInMapRutSeln "IRembParkngInMapRutSeln";
BA_ "LongName" SG_ 895 IRembParkngInMapRutSeln "Remember Parking In Map Route Selection";
BA_ "SysSignalName" SG_ 895 IRembParkngInMapRutSeln "RembParkngInMapRutSeln";
BA_ "CompuMethodName" SG_ 895 IIPDMCUTemp "IPDMCUTemp";
BA_ "GenSigStartValue" SG_ 895 IIPDMCUTemp 255;
BA_ "ISignalName" SG_ 895 IIPDMCUTemp "IIPDMCUTemp";
BA_ "LongName" SG_ 895 IIPDMCUTemp "IPD MCU Temperature";
BA_ "SysSignalName" SG_ 895 IIPDMCUTemp "IPDMCUTemp";
BA_ "CompuMethodName" SG_ 895 IIPDWtrClntInltReqFlg "IPDWtrClntInltReqFlg";
BA_ "ISignalName" SG_ 895 IIPDWtrClntInltReqFlg "IIPDWtrClntInltReqFlg";
BA_ "LongName" SG_ 895 IIPDWtrClntInltReqFlg "IPD_water_coolant_inlet_request_flag";
BA_ "SysSignalName" SG_ 895 IIPDWtrClntInltReqFlg "IPDWtrClntInltReqFlg";
BA_ "CompuMethodName" SG_ 895 ITrfGreenLghtActn "TrfGreenLghtActn";
BA_ "ISignalName" SG_ 895 ITrfGreenLghtActn "ITrfGreenLghtActn";
BA_ "LongName" SG_ 895 ITrfGreenLghtActn "Traffic Green Light Attention";
BA_ "SysSignalName" SG_ 895 ITrfGreenLghtActn "TrfGreenLghtActn";
BA_ "CompuMethodName" SG_ 895 IRembParkngInMapngRutID "RembParkngInMapngRutID";
BA_ "ISignalName" SG_ 895 IRembParkngInMapngRutID "IRembParkngInMapngRutID";
BA_ "LongName" SG_ 895 IRembParkngInMapngRutID "Remember Parking In Maping Route Id";
BA_ "SysSignalName" SG_ 895 IRembParkngInMapngRutID "RembParkngInMapngRutID";
BA_ "CompuMethodName" SG_ 895 IRembParkngInMapngDistToEnd "RembParkngInMapngDistToEnd";
BA_ "ISignalName" SG_ 895 IRembParkngInMapngDistToEnd "IRembParkngInMapngDistToEnd";
BA_ "LongName" SG_ 895 IRembParkngInMapngDistToEnd "Remember Parking In Mapping Distance To End";
BA_ "SysSignalName" SG_ 895 IRembParkngInMapngDistToEnd "RembParkngInMapngDistToEnd";
BA_ "CompuMethodName" SG_ 895 IRembParkngInMapRutDltSeln "RembParkngInMapRutDltSeln";
BA_ "ISignalName" SG_ 895 IRembParkngInMapRutDltSeln "IRembParkngInMapRutDltSeln";
BA_ "LongName" SG_ 895 IRembParkngInMapRutDltSeln "Remember Parking In Map Route Delete Selectio";
BA_ "SysSignalName" SG_ 895 IRembParkngInMapRutDltSeln "RembParkngInMapRutDltSeln";
BA_ "CompuMethodName" SG_ 382 IICBAD_20ms_Group07_CRC "ICBAD_20ms_Group07_CRC";
BA_ "ISignalName" SG_ 382 IICBAD_20ms_Group07_CRC "IICBAD_20ms_Group07_CRC";
BA_ "SysSignalName" SG_ 382 IICBAD_20ms_Group07_CRC "ICBAD_20ms_Group07_CRC";
BA_ "CompuMethodName" SG_ 382 IICBAD_20ms_Group07_RC "ICBAD_20ms_Group07_RC";
BA_ "ISignalName" SG_ 382 IICBAD_20ms_Group07_RC "IICBAD_20ms_Group07_RC";
BA_ "SysSignalName" SG_ 382 IICBAD_20ms_Group07_RC "ICBAD_20ms_Group07_RC";
BA_ "CompuMethodName" SG_ 382 IACCSdslReq "ACCSdslReq";
BA_ "ISignalName" SG_ 382 IACCSdslReq "IACCSdslReq";
BA_ "LongName" SG_ 382 IACCSdslReq "Adaptive Cruise Control Standstill Request";
BA_ "SysSignalName" SG_ 382 IACCSdslReq "ACCSdslReq";
BA_ "CompuMethodName" SG_ 382 IACCGoReq "ACCGoReq";
BA_ "ISignalName" SG_ 382 IACCGoReq "IACCGoReq";
BA_ "LongName" SG_ 382 IACCGoReq "Adaptive Cruise Control Go Request";
BA_ "SysSignalName" SG_ 382 IACCGoReq "ACCGoReq";
BA_ "CompuMethodName" SG_ 382 IACCAccReqSts_CH "ACCAccReqSts_CH";
BA_ "ISignalName" SG_ 382 IACCAccReqSts_CH "IACCAccReqSts_CH";
BA_ "LongName" SG_ 382 IACCAccReqSts_CH "Adaptive Cruise Control Acceleration Request Status";
BA_ "SysSignalName" SG_ 382 IACCAccReqSts_CH "ACCAccReqSts_CH";
BA_ "CompuMethodName" SG_ 382 IACCAccReqVal "ACCAccReqVal";
BA_ "GenSigStartValue" SG_ 382 IACCAccReqVal 1713;
BA_ "ISignalName" SG_ 382 IACCAccReqVal "IACCAccReqVal";
BA_ "LongName" SG_ 382 IACCAccReqVal "Adaptive Cruise Control Acceleration Request Value";
BA_ "SysSignalName" SG_ 382 IACCAccReqVal "ACCAccReqVal";
BA_ "CompuMethodName" SG_ 382 IICBAD_20ms_Group07_Reserved1 "ICBAD_20ms_Group07_Reserved1";
BA_ "GenSigStartValue" SG_ 382 IICBAD_20ms_Group07_Reserved1 3;
BA_ "ISignalName" SG_ 382 IICBAD_20ms_Group07_Reserved1 "IICBAD_20ms_Group07_Reserved1";
BA_ "SysSignalName" SG_ 382 IICBAD_20ms_Group07_Reserved1 "ICBAD_20ms_Group07_Reserved1";
BA_ "CompuMethodName" SG_ 382 IACCSysFltSts "ACCSysFltSts";
BA_ "ISignalName" SG_ 382 IACCSysFltSts "IACCSysFltSts";
BA_ "LongName" SG_ 382 IACCSysFltSts "Adaptive Cruise Control System Fault Status";
BA_ "SysSignalName" SG_ 382 IACCSysFltSts "ACCSysFltSts";
BA_ "CompuMethodName" SG_ 382 IICBAD_20ms_Group07_Reserved3 "ICBAD_20ms_Group07_Reserved3";
BA_ "GenSigStartValue" SG_ 382 IICBAD_20ms_Group07_Reserved3 7;
BA_ "ISignalName" SG_ 382 IICBAD_20ms_Group07_Reserved3 "IICBAD_20ms_Group07_Reserved3";
BA_ "SysSignalName" SG_ 382 IICBAD_20ms_Group07_Reserved3 "ICBAD_20ms_Group07_Reserved3";
BA_ "CompuMethodName" SG_ 382 IACCSysSts "ACCSysSts";
BA_ "ISignalName" SG_ 382 IACCSysSts "IACCSysSts";
BA_ "LongName" SG_ 382 IACCSysSts "Adaptive Cruise Control System Status";
BA_ "SysSignalName" SG_ 382 IACCSysSts "ACCSysSts";
BA_ "CompuMethodName" SG_ 382 IICBAD_20ms_Group07_Reserved2 "ICBAD_20ms_Group07_Reserved2";
BA_ "GenSigStartValue" SG_ 382 IICBAD_20ms_Group07_Reserved2 3;
BA_ "ISignalName" SG_ 382 IICBAD_20ms_Group07_Reserved2 "IICBAD_20ms_Group07_Reserved2";
BA_ "SysSignalName" SG_ 382 IICBAD_20ms_Group07_Reserved2 "ICBAD_20ms_Group07_Reserved2";
BA_ "CompuMethodName" SG_ 382 IICBAD_20ms_Group07_Reserved4 "ICBAD_20ms_Group07_Reserved4";
BA_ "GenSigStartValue" SG_ 382 IICBAD_20ms_Group07_Reserved4 255;
BA_ "ISignalName" SG_ 382 IICBAD_20ms_Group07_Reserved4 "IICBAD_20ms_Group07_Reserved4";
BA_ "SysSignalName" SG_ 382 IICBAD_20ms_Group07_Reserved4 "ICBAD_20ms_Group07_Reserved4";
BA_ "CompuMethodName" SG_ 382 IICBAD_20ms_Group07_Reserved5 "ICBAD_20ms_Group07_Reserved5";
BA_ "GenSigStartValue" SG_ 382 IICBAD_20ms_Group07_Reserved5 255;
BA_ "ISignalName" SG_ 382 IICBAD_20ms_Group07_Reserved5 "IICBAD_20ms_Group07_Reserved5";
BA_ "SysSignalName" SG_ 382 IICBAD_20ms_Group07_Reserved5 "ICBAD_20ms_Group07_Reserved5";
BA_ "CompuMethodName" SG_ 382 IICBAD_20ms_Group07_Reserved6 "ICBAD_20ms_Group07_Reserved6";
BA_ "GenSigStartValue" SG_ 382 IICBAD_20ms_Group07_Reserved6 255;
BA_ "ISignalName" SG_ 382 IICBAD_20ms_Group07_Reserved6 "IICBAD_20ms_Group07_Reserved6";
BA_ "SysSignalName" SG_ 382 IICBAD_20ms_Group07_Reserved6 "ICBAD_20ms_Group07_Reserved6";
BA_ "CompuMethodName" SG_ 736 IFrtObsDist "FrtObsDist";
BA_ "ISignalName" SG_ 736 IFrtObsDist "IFrtObsDist";
BA_ "LongName" SG_ 736 IFrtObsDist "Front Obstacle Distance";
BA_ "SysSignalName" SG_ 736 IFrtObsDist "FrtObsDist";
BA_ "CompuMethodName" SG_ 736 IFrtMidRObsRng "FrtMidRObsRng";
BA_ "ISignalName" SG_ 736 IFrtMidRObsRng "IFrtMidRObsRng";
BA_ "LongName" SG_ 736 IFrtMidRObsRng "Front Middle Right Obstacle Range";
BA_ "SysSignalName" SG_ 736 IFrtMidRObsRng "FrtMidRObsRng";
BA_ "CompuMethodName" SG_ 736 IFrtPDCAudWrnng "FrtPDCAudWrnng";
BA_ "ISignalName" SG_ 736 IFrtPDCAudWrnng "IFrtPDCAudWrnng";
BA_ "LongName" SG_ 736 IFrtPDCAudWrnng "Front Park Distance Control Audible Warning";
BA_ "SysSignalName" SG_ 736 IFrtPDCAudWrnng "FrtPDCAudWrnng";
BA_ "CompuMethodName" SG_ 736 IRrMidLObsRng "RrMidLObsRng";
BA_ "ISignalName" SG_ 736 IRrMidLObsRng "IRrMidLObsRng";
BA_ "LongName" SG_ 736 IRrMidLObsRng "Rear Middle Left Obstacle Range";
BA_ "SysSignalName" SG_ 736 IRrMidLObsRng "RrMidLObsRng";
BA_ "CompuMethodName" SG_ 736 IRLObsRng "RLObsRng";
BA_ "ISignalName" SG_ 736 IRLObsRng "IRLObsRng";
BA_ "LongName" SG_ 736 IRLObsRng "Rear Left Obstacle Range";
BA_ "SysSignalName" SG_ 736 IRLObsRng "RLObsRng";
BA_ "CompuMethodName" SG_ 736 IRrMidRObsRng "RrMidRObsRng";
BA_ "ISignalName" SG_ 736 IRrMidRObsRng "IRrMidRObsRng";
BA_ "LongName" SG_ 736 IRrMidRObsRng "Rear Middle Right Obstacle Range";
BA_ "SysSignalName" SG_ 736 IRrMidRObsRng "RrMidRObsRng";
BA_ "CompuMethodName" SG_ 736 IPDCSysSts "PDCSysSts";
BA_ "ISignalName" SG_ 736 IPDCSysSts "IPDCSysSts";
BA_ "LongName" SG_ 736 IPDCSysSts "Park Distance Control System Status";
BA_ "SysSignalName" SG_ 736 IPDCSysSts "PDCSysSts";
BA_ "CompuMethodName" SG_ 736 IRrObsDist "RrObsDist";
BA_ "ISignalName" SG_ 736 IRrObsDist "IRrObsDist";
BA_ "LongName" SG_ 736 IRrObsDist "Rear Obstacle Distance";
BA_ "SysSignalName" SG_ 736 IRrObsDist "RrObsDist";
BA_ "CompuMethodName" SG_ 736 IFLSideObsRng "FLSideObsRng";
BA_ "ISignalName" SG_ 736 IFLSideObsRng "IFLSideObsRng";
BA_ "LongName" SG_ 736 IFLSideObsRng "Front Left Side Obstacle Range";
BA_ "SysSignalName" SG_ 736 IFLSideObsRng "FLSideObsRng";
BA_ "CompuMethodName" SG_ 736 IRrPDCAudWrnng "RrPDCAudWrnng";
BA_ "ISignalName" SG_ 736 IRrPDCAudWrnng "IRrPDCAudWrnng";
BA_ "LongName" SG_ 736 IRrPDCAudWrnng "Rear Park Distance Control Audible Warning";
BA_ "SysSignalName" SG_ 736 IRrPDCAudWrnng "RrPDCAudWrnng";
BA_ "CompuMethodName" SG_ 736 IRLSideObsRng "RLSideObsRng";
BA_ "ISignalName" SG_ 736 IRLSideObsRng "IRLSideObsRng";
BA_ "LongName" SG_ 736 IRLSideObsRng "Rear Left Side Obstacle Range";
BA_ "SysSignalName" SG_ 736 IRLSideObsRng "RLSideObsRng";
BA_ "CompuMethodName" SG_ 736 IFRSideObsRng "FRSideObsRng";
BA_ "ISignalName" SG_ 736 IFRSideObsRng "IFRSideObsRng";
BA_ "LongName" SG_ 736 IFRSideObsRng "Front Right Side Obstacle Range";
BA_ "SysSignalName" SG_ 736 IFRSideObsRng "FRSideObsRng";
BA_ "CompuMethodName" SG_ 736 IUndergndParkngGrgSts "UndergndParkngGrgSts";
BA_ "ISignalName" SG_ 736 IUndergndParkngGrgSts "IUndergndParkngGrgSts";
BA_ "LongName" SG_ 736 IUndergndParkngGrgSts "Underground Parking Garage Status";
BA_ "SysSignalName" SG_ 736 IUndergndParkngGrgSts "UndergndParkngGrgSts";
BA_ "CompuMethodName" SG_ 736 IRRSideObsRng "RRSideObsRng";
BA_ "ISignalName" SG_ 736 IRRSideObsRng "IRRSideObsRng";
BA_ "LongName" SG_ 736 IRRSideObsRng "Rear Right Side Obstacle Range";
BA_ "SysSignalName" SG_ 736 IRRSideObsRng "RRSideObsRng";
BA_ "CompuMethodName" SG_ 736 IFLObsRng "FLObsRng";
BA_ "ISignalName" SG_ 736 IFLObsRng "IFLObsRng";
BA_ "LongName" SG_ 736 IFLObsRng "Front Left Obstacle Range";
BA_ "SysSignalName" SG_ 736 IFLObsRng "FLObsRng";
BA_ "CompuMethodName" SG_ 736 IRRObsRng "RRObsRng";
BA_ "ISignalName" SG_ 736 IRRObsRng "IRRObsRng";
BA_ "LongName" SG_ 736 IRRObsRng "Rear Right Obstacle Range";
BA_ "SysSignalName" SG_ 736 IRRObsRng "RRObsRng";
BA_ "CompuMethodName" SG_ 736 IFRObsRng "FRObsRng";
BA_ "ISignalName" SG_ 736 IFRObsRng "IFRObsRng";
BA_ "LongName" SG_ 736 IFRObsRng "Front Right Obstacle Range";
BA_ "SysSignalName" SG_ 736 IFRObsRng "FRObsRng";
BA_ "CompuMethodName" SG_ 736 ILADSAFnInd "LADSAFnInd";
BA_ "ISignalName" SG_ 736 ILADSAFnInd "ILADSAFnInd";
BA_ "LongName" SG_ 736 ILADSAFnInd "Advanced Park Assist Active Function Indication";
BA_ "SysSignalName" SG_ 736 ILADSAFnInd "LADSAFnInd";
BA_ "CompuMethodName" SG_ 736 IFrtMidLObsRng "FrtMidLObsRng";
BA_ "ISignalName" SG_ 736 IFrtMidLObsRng "IFrtMidLObsRng";
BA_ "LongName" SG_ 736 IFrtMidLObsRng "Front Middle Left Obstacle Range";
BA_ "SysSignalName" SG_ 736 IFrtMidLObsRng "FrtMidLObsRng";
BA_ "CompuMethodName" SG_ 736 IFRSObsRng "FRSObsRng";
BA_ "ISignalName" SG_ 736 IFRSObsRng "IFRSObsRng";
BA_ "LongName" SG_ 736 IFRSObsRng "Front Right Side Obstacle Range";
BA_ "SysSignalName" SG_ 736 IFRSObsRng "FRSObsRng";
BA_ "CompuMethodName" SG_ 736 IFLSObsRng "FLSObsRng";
BA_ "ISignalName" SG_ 736 IFLSObsRng "IFLSObsRng";
BA_ "LongName" SG_ 736 IFLSObsRng "Front Left Side Obstacle Range";
BA_ "SysSignalName" SG_ 736 IFLSObsRng "FLSObsRng";
BA_ "CompuMethodName" SG_ 736 IRRSObsRng "RRSObsRng";
BA_ "ISignalName" SG_ 736 IRRSObsRng "IRRSObsRng";
BA_ "LongName" SG_ 736 IRRSObsRng "Rear Right Side Obstacle Range";
BA_ "SysSignalName" SG_ 736 IRRSObsRng "RRSObsRng";
BA_ "CompuMethodName" SG_ 736 IRLSObsRng "RLSObsRng";
BA_ "ISignalName" SG_ 736 IRLSObsRng "IRLSObsRng";
BA_ "LongName" SG_ 736 IRLSObsRng "Rear Left Side Obstacle Range";
BA_ "SysSignalName" SG_ 736 IRLSObsRng "RLSObsRng";
BA_ "CompuMethodName" SG_ 351 IICBAD_20ms_Group05_CRC "ICBAD_20ms_Group05_CRC";
BA_ "ISignalName" SG_ 351 IICBAD_20ms_Group05_CRC "IICBAD_20ms_Group05_CRC";
BA_ "SysSignalName" SG_ 351 IICBAD_20ms_Group05_CRC "ICBAD_20ms_Group05_CRC";
BA_ "CompuMethodName" SG_ 351 IICBAD_20ms_Group05_RC "ICBAD_20ms_Group05_RC";
BA_ "ISignalName" SG_ 351 IICBAD_20ms_Group05_RC "IICBAD_20ms_Group05_RC";
BA_ "SysSignalName" SG_ 351 IICBAD_20ms_Group05_RC "ICBAD_20ms_Group05_RC";
BA_ "CompuMethodName" SG_ 351 IICBAD_20ms_Group05_Reserved1 "ICBAD_20ms_Group05_Reserved1";
BA_ "GenSigStartValue" SG_ 351 IICBAD_20ms_Group05_Reserved1 1;
BA_ "ISignalName" SG_ 351 IICBAD_20ms_Group05_Reserved1 "IICBAD_20ms_Group05_Reserved1";
BA_ "SysSignalName" SG_ 351 IICBAD_20ms_Group05_Reserved1 "ICBAD_20ms_Group05_Reserved1";
BA_ "CompuMethodName" SG_ 351 IAPAVCUReqSts "APAVCUReqSts";
BA_ "ISignalName" SG_ 351 IAPAVCUReqSts "IAPAVCUReqSts";
BA_ "LongName" SG_ 351 IAPAVCUReqSts "Apa Vcu Request Status";
BA_ "SysSignalName" SG_ 351 IAPAVCUReqSts "APAVCUReqSts";
BA_ "CompuMethodName" SG_ 351 IICBAD_20ms_Group05_Reserved2 "ICBAD_20ms_Group05_Reserved2";
BA_ "GenSigStartValue" SG_ 351 IICBAD_20ms_Group05_Reserved2 255;
BA_ "ISignalName" SG_ 351 IICBAD_20ms_Group05_Reserved2 "IICBAD_20ms_Group05_Reserved2";
BA_ "SysSignalName" SG_ 351 IICBAD_20ms_Group05_Reserved2 "ICBAD_20ms_Group05_Reserved2";
BA_ "CompuMethodName" SG_ 351 IAPAToqReqVal "APAToqReqVal";
BA_ "ISignalName" SG_ 351 IAPAToqReqVal "IAPAToqReqVal";
BA_ "LongName" SG_ 351 IAPAToqReqVal "Advanced Park Assist Torque Request Value";
BA_ "SysSignalName" SG_ 351 IAPAToqReqVal "APAToqReqVal";
BA_ "CompuMethodName" SG_ 351 IAPACrpSpdReqVal_IPD "APACrpSpdReqVal_IPD";
BA_ "ISignalName" SG_ 351 IAPACrpSpdReqVal_IPD "IAPACrpSpdReqVal_IPD";
BA_ "LongName" SG_ 351 IAPACrpSpdReqVal_IPD "Advanced Park Assist Creep Speed Request Value";
BA_ "SysSignalName" SG_ 351 IAPACrpSpdReqVal_IPD "APACrpSpdReqVal_IPD";
BA_ "CompuMethodName" SG_ 351 IICBAD_20ms_Group05_Reserved3 "ICBAD_20ms_Group05_Reserved3";
BA_ "GenSigStartValue" SG_ 351 IICBAD_20ms_Group05_Reserved3 1;
BA_ "ISignalName" SG_ 351 IICBAD_20ms_Group05_Reserved3 "IICBAD_20ms_Group05_Reserved3";
BA_ "SysSignalName" SG_ 351 IICBAD_20ms_Group05_Reserved3 "ICBAD_20ms_Group05_Reserved3";
BA_ "CompuMethodName" SG_ 351 IAPARevrDrgReq "APARevrDrgReq";
BA_ "ISignalName" SG_ 351 IAPARevrDrgReq "IAPARevrDrgReq";
BA_ "LongName" SG_ 351 IAPARevrDrgReq "Advanced Park Assist Reverse Drag Request";
BA_ "SysSignalName" SG_ 351 IAPARevrDrgReq "APARevrDrgReq";
BA_ "CompuMethodName" SG_ 351 IICBAD_20ms_Group05_Reserved4 "ICBAD_20ms_Group05_Reserved4";
BA_ "GenSigStartValue" SG_ 351 IICBAD_20ms_Group05_Reserved4 255;
BA_ "ISignalName" SG_ 351 IICBAD_20ms_Group05_Reserved4 "IICBAD_20ms_Group05_Reserved4";
BA_ "SysSignalName" SG_ 351 IICBAD_20ms_Group05_Reserved4 "ICBAD_20ms_Group05_Reserved4";
BA_ "CompuMethodName" SG_ 351 IICBAD_20ms_Group05_Reserved5 "ICBAD_20ms_Group05_Reserved5";
BA_ "GenSigStartValue" SG_ 351 IICBAD_20ms_Group05_Reserved5 255;
BA_ "ISignalName" SG_ 351 IICBAD_20ms_Group05_Reserved5 "IICBAD_20ms_Group05_Reserved5";
BA_ "SysSignalName" SG_ 351 IICBAD_20ms_Group05_Reserved5 "ICBAD_20ms_Group05_Reserved5";
BA_ "CompuMethodName" SG_ 424 IICBAD_20ms_Group12_CRC "ICBAD_20ms_Group12_CRC";
BA_ "ISignalName" SG_ 424 IICBAD_20ms_Group12_CRC "IICBAD_20ms_Group12_CRC";
BA_ "SysSignalName" SG_ 424 IICBAD_20ms_Group12_CRC "ICBAD_20ms_Group12_CRC";
BA_ "CompuMethodName" SG_ 424 IICBAD_20ms_Group12_RC "ICBAD_20ms_Group12_RC";
BA_ "ISignalName" SG_ 424 IICBAD_20ms_Group12_RC "IICBAD_20ms_Group12_RC";
BA_ "SysSignalName" SG_ 424 IICBAD_20ms_Group12_RC "ICBAD_20ms_Group12_RC";
BA_ "CompuMethodName" SG_ 424 IICBAD_20ms_Group12_Reserved1 "ICBAD_20ms_Group12_Reserved1";
BA_ "GenSigStartValue" SG_ 424 IICBAD_20ms_Group12_Reserved1 15;
BA_ "ISignalName" SG_ 424 IICBAD_20ms_Group12_Reserved1 "IICBAD_20ms_Group12_Reserved1";
BA_ "SysSignalName" SG_ 424 IICBAD_20ms_Group12_Reserved1 "ICBAD_20ms_Group12_Reserved1";
BA_ "CompuMethodName" SG_ 424 IICBAD_20ms_Group12_Reserved2 "ICBAD_20ms_Group12_Reserved2";
BA_ "GenSigStartValue" SG_ 424 IICBAD_20ms_Group12_Reserved2 31;
BA_ "ISignalName" SG_ 424 IICBAD_20ms_Group12_Reserved2 "IICBAD_20ms_Group12_Reserved2";
BA_ "SysSignalName" SG_ 424 IICBAD_20ms_Group12_Reserved2 "ICBAD_20ms_Group12_Reserved2";
BA_ "CompuMethodName" SG_ 424 IAPASts "APASts";
BA_ "ISignalName" SG_ 424 IAPASts "IAPASts";
BA_ "LongName" SG_ 424 IAPASts "Advanced Park Assist Status";
BA_ "SysSignalName" SG_ 424 IAPASts "APASts";
BA_ "CompuMethodName" SG_ 424 IAutodDrvngSysSts "AutodDrvngSysSts";
BA_ "ISignalName" SG_ 424 IAutodDrvngSysSts "IAutodDrvngSysSts";
BA_ "LongName" SG_ 424 IAutodDrvngSysSts "Automated Driving System Status";
BA_ "SysSignalName" SG_ 424 IAutodDrvngSysSts "AutodDrvngSysSts";
BA_ "CompuMethodName" SG_ 424 IICBAD_20ms_Group12_Reserved3 "ICBAD_20ms_Group12_Reserved3";
BA_ "GenSigStartValue" SG_ 424 IICBAD_20ms_Group12_Reserved3 255;
BA_ "ISignalName" SG_ 424 IICBAD_20ms_Group12_Reserved3 "IICBAD_20ms_Group12_Reserved3";
BA_ "SysSignalName" SG_ 424 IICBAD_20ms_Group12_Reserved3 "ICBAD_20ms_Group12_Reserved3";
BA_ "CompuMethodName" SG_ 424 IICBAD_20ms_Group12_Reserved4 "ICBAD_20ms_Group12_Reserved4";
BA_ "GenSigStartValue" SG_ 424 IICBAD_20ms_Group12_Reserved4 255;
BA_ "ISignalName" SG_ 424 IICBAD_20ms_Group12_Reserved4 "IICBAD_20ms_Group12_Reserved4";
BA_ "SysSignalName" SG_ 424 IICBAD_20ms_Group12_Reserved4 "ICBAD_20ms_Group12_Reserved4";
BA_ "CompuMethodName" SG_ 424 IICBAD_20ms_Group12_Reserved5 "ICBAD_20ms_Group12_Reserved5";
BA_ "GenSigStartValue" SG_ 424 IICBAD_20ms_Group12_Reserved5 255;
BA_ "ISignalName" SG_ 424 IICBAD_20ms_Group12_Reserved5 "IICBAD_20ms_Group12_Reserved5";
BA_ "SysSignalName" SG_ 424 IICBAD_20ms_Group12_Reserved5 "ICBAD_20ms_Group12_Reserved5";
BA_ "CompuMethodName" SG_ 424 IICBAD_20ms_Group12_Reserved6 "ICBAD_20ms_Group12_Reserved6";
BA_ "GenSigStartValue" SG_ 424 IICBAD_20ms_Group12_Reserved6 255;
BA_ "ISignalName" SG_ 424 IICBAD_20ms_Group12_Reserved6 "IICBAD_20ms_Group12_Reserved6";
BA_ "SysSignalName" SG_ 424 IICBAD_20ms_Group12_Reserved6 "ICBAD_20ms_Group12_Reserved6";
BA_ "CompuMethodName" SG_ 431 IICBAD_20ms_Group15_CRC "ICBAD_20ms_Group15_CRC";
BA_ "ISignalName" SG_ 431 IICBAD_20ms_Group15_CRC "IICBAD_20ms_Group15_CRC";
BA_ "SysSignalName" SG_ 431 IICBAD_20ms_Group15_CRC "ICBAD_20ms_Group15_CRC";
BA_ "CompuMethodName" SG_ 431 IICBAD_20ms_Group15_RC "ICBAD_20ms_Group15_RC";
BA_ "ISignalName" SG_ 431 IICBAD_20ms_Group15_RC "IICBAD_20ms_Group15_RC";
BA_ "SysSignalName" SG_ 431 IICBAD_20ms_Group15_RC "ICBAD_20ms_Group15_RC";
BA_ "CompuMethodName" SG_ 431 IACCDclReqSts "ACCDclReqSts";
BA_ "ISignalName" SG_ 431 IACCDclReqSts "IACCDclReqSts";
BA_ "LongName" SG_ 431 IACCDclReqSts "Adaptive Cruise Control Deceleration Request Status";
BA_ "SysSignalName" SG_ 431 IACCDclReqSts "ACCDclReqSts";
BA_ "CompuMethodName" SG_ 431 IICBAD_20ms_Group15_Reserved1 "ICBAD_20ms_Group15_Reserved1";
BA_ "GenSigStartValue" SG_ 431 IICBAD_20ms_Group15_Reserved1 3;
BA_ "ISignalName" SG_ 431 IICBAD_20ms_Group15_Reserved1 "IICBAD_20ms_Group15_Reserved1";
BA_ "SysSignalName" SG_ 431 IICBAD_20ms_Group15_Reserved1 "ICBAD_20ms_Group15_Reserved1";
BA_ "CompuMethodName" SG_ 431 IICBAD_20ms_Group15_Reserved2 "ICBAD_20ms_Group15_Reserved2";
BA_ "GenSigStartValue" SG_ 431 IICBAD_20ms_Group15_Reserved2 255;
BA_ "ISignalName" SG_ 431 IICBAD_20ms_Group15_Reserved2 "IICBAD_20ms_Group15_Reserved2";
BA_ "SysSignalName" SG_ 431 IICBAD_20ms_Group15_Reserved2 "ICBAD_20ms_Group15_Reserved2";
BA_ "CompuMethodName" SG_ 431 IACCOtptShaftTotToqReqVal "ACCOtptShaftTotToqReqVal";
BA_ "GenSigStartValue" SG_ 431 IACCOtptShaftTotToqReqVal 1696;
BA_ "ISignalName" SG_ 431 IACCOtptShaftTotToqReqVal "IACCOtptShaftTotToqReqVal";
BA_ "LongName" SG_ 431 IACCOtptShaftTotToqReqVal "Adaptive Cruise Control Output Shaft Total Torque Request Value";
BA_ "SysSignalName" SG_ 431 IACCOtptShaftTotToqReqVal "ACCOtptShaftTotToqReqVal";
BA_ "CompuMethodName" SG_ 431 IICBAD_20ms_Group15_Reserved3 "ICBAD_20ms_Group15_Reserved3";
BA_ "GenSigStartValue" SG_ 431 IICBAD_20ms_Group15_Reserved3 3;
BA_ "ISignalName" SG_ 431 IICBAD_20ms_Group15_Reserved3 "IICBAD_20ms_Group15_Reserved3";
BA_ "SysSignalName" SG_ 431 IICBAD_20ms_Group15_Reserved3 "ICBAD_20ms_Group15_Reserved3";
BA_ "CompuMethodName" SG_ 431 IACCOtptShaftTotToqReqSts "ACCOtptShaftTotToqReqSts";
BA_ "ISignalName" SG_ 431 IACCOtptShaftTotToqReqSts "IACCOtptShaftTotToqReqSts";
BA_ "LongName" SG_ 431 IACCOtptShaftTotToqReqSts "Adaptive Cruise Control Output Shaft Total Torque Request Status";
BA_ "SysSignalName" SG_ 431 IACCOtptShaftTotToqReqSts "ACCOtptShaftTotToqReqSts";
BA_ "CompuMethodName" SG_ 431 IICBAD_20ms_Group15_Reserved4 "ICBAD_20ms_Group15_Reserved4";
BA_ "GenSigStartValue" SG_ 431 IICBAD_20ms_Group15_Reserved4 255;
BA_ "ISignalName" SG_ 431 IICBAD_20ms_Group15_Reserved4 "IICBAD_20ms_Group15_Reserved4";
BA_ "SysSignalName" SG_ 431 IICBAD_20ms_Group15_Reserved4 "ICBAD_20ms_Group15_Reserved4";
BA_ "CompuMethodName" SG_ 431 IICBAD_20ms_Group15_Reserved5 "ICBAD_20ms_Group15_Reserved5";
BA_ "GenSigStartValue" SG_ 431 IICBAD_20ms_Group15_Reserved5 255;
BA_ "ISignalName" SG_ 431 IICBAD_20ms_Group15_Reserved5 "IICBAD_20ms_Group15_Reserved5";
BA_ "SysSignalName" SG_ 431 IICBAD_20ms_Group15_Reserved5 "ICBAD_20ms_Group15_Reserved5";
BA_ "CompuMethodName" SG_ 431 IICBAD_20ms_Group15_Reserved6 "ICBAD_20ms_Group15_Reserved6";
BA_ "GenSigStartValue" SG_ 431 IICBAD_20ms_Group15_Reserved6 255;
BA_ "ISignalName" SG_ 431 IICBAD_20ms_Group15_Reserved6 "IICBAD_20ms_Group15_Reserved6";
BA_ "SysSignalName" SG_ 431 IICBAD_20ms_Group15_Reserved6 "ICBAD_20ms_Group15_Reserved6";
BA_ "CompuMethodName" SG_ 431 IICBAD_20ms_Group15_Reserved7 "ICBAD_20ms_Group15_Reserved7";
BA_ "GenSigStartValue" SG_ 431 IICBAD_20ms_Group15_Reserved7 255;
BA_ "ISignalName" SG_ 431 IICBAD_20ms_Group15_Reserved7 "IICBAD_20ms_Group15_Reserved7";
BA_ "SysSignalName" SG_ 431 IICBAD_20ms_Group15_Reserved7 "ICBAD_20ms_Group15_Reserved7";
BA_ "CompuMethodName" SG_ 431 IICBAD_20ms_Group15_Reserved8 "ICBAD_20ms_Group15_Reserved8";
BA_ "GenSigStartValue" SG_ 431 IICBAD_20ms_Group15_Reserved8 255;
BA_ "ISignalName" SG_ 431 IICBAD_20ms_Group15_Reserved8 "IICBAD_20ms_Group15_Reserved8";
BA_ "SysSignalName" SG_ 431 IICBAD_20ms_Group15_Reserved8 "ICBAD_20ms_Group15_Reserved8";
BA_ "CompuMethodName" SG_ 431 IICBAD_20ms_Group15_Reserved9 "ICBAD_20ms_Group15_Reserved9";
BA_ "GenSigStartValue" SG_ 431 IICBAD_20ms_Group15_Reserved9 255;
BA_ "ISignalName" SG_ 431 IICBAD_20ms_Group15_Reserved9 "IICBAD_20ms_Group15_Reserved9";
BA_ "SysSignalName" SG_ 431 IICBAD_20ms_Group15_Reserved9 "ICBAD_20ms_Group15_Reserved9";
BA_ "CompuMethodName" SG_ 431 IICBAD_20ms_Group15_Reserved10 "ICBAD_20ms_Group15_Reserved10";
BA_ "GenSigStartValue" SG_ 431 IICBAD_20ms_Group15_Reserved10 255;
BA_ "ISignalName" SG_ 431 IICBAD_20ms_Group15_Reserved10 "IICBAD_20ms_Group15_Reserved10";
BA_ "SysSignalName" SG_ 431 IICBAD_20ms_Group15_Reserved10 "ICBAD_20ms_Group15_Reserved10";
BA_ "CompuMethodName" SG_ 291 IICBVC_20ms_Group05_CRC "ICBVC_20ms_Group05_CRC";
BA_ "ISignalName" SG_ 291 IICBVC_20ms_Group05_CRC "IICBVC_20ms_Group05_CRC";
BA_ "LongName" SG_ 291 IICBVC_20ms_Group05_CRC "CRC";
BA_ "SysSignalName" SG_ 291 IICBVC_20ms_Group05_CRC "ICBVC_20ms_Group05_CRC";
BA_ "CompuMethodName" SG_ 291 IICBVC_20ms_Group05_RC "ICBVC_20ms_Group05_RC";
BA_ "ISignalName" SG_ 291 IICBVC_20ms_Group05_RC "IICBVC_20ms_Group05_RC";
BA_ "LongName" SG_ 291 IICBVC_20ms_Group05_RC "RC";
BA_ "SysSignalName" SG_ 291 IICBVC_20ms_Group05_RC "ICBVC_20ms_Group05_RC";
BA_ "CompuMethodName" SG_ 291 IICBVC_20ms_Group05_Reserved1 "ICBVC_20ms_Group05_Reserved1";
BA_ "GenSigStartValue" SG_ 291 IICBVC_20ms_Group05_Reserved1 1;
BA_ "ISignalName" SG_ 291 IICBVC_20ms_Group05_Reserved1 "IICBVC_20ms_Group05_Reserved1";
BA_ "SysSignalName" SG_ 291 IICBVC_20ms_Group05_Reserved1 "ICBVC_20ms_Group05_Reserved1";
BA_ "CompuMethodName" SG_ 291 ISysPwrMdBkupV "SysPwrMdBkupV";
BA_ "GenSigStartValue" SG_ 291 ISysPwrMdBkupV 1;
BA_ "ISignalName" SG_ 291 ISysPwrMdBkupV "ISysPwrMdBkupV";
BA_ "LongName" SG_ 291 ISysPwrMdBkupV "System Power Mode Left Backup Validity";
BA_ "SysSignalName" SG_ 291 ISysPwrMdBkupV "SysPwrMdBkupV";
BA_ "CompuMethodName" SG_ 291 ISysPwrMdBkup "SysPwrMdBkup";
BA_ "ISignalName" SG_ 291 ISysPwrMdBkup "ISysPwrMdBkup";
BA_ "LongName" SG_ 291 ISysPwrMdBkup "System Power Mode Left Backup";
BA_ "SysSignalName" SG_ 291 ISysPwrMdBkup "SysPwrMdBkup";
BA_ "CompuMethodName" SG_ 291 IICBVC_20ms_Group05_Reserved2 "ICBVC_20ms_Group05_Reserved2";
BA_ "GenSigStartValue" SG_ 291 IICBVC_20ms_Group05_Reserved2 7;
BA_ "ISignalName" SG_ 291 IICBVC_20ms_Group05_Reserved2 "IICBVC_20ms_Group05_Reserved2";
BA_ "SysSignalName" SG_ 291 IICBVC_20ms_Group05_Reserved2 "ICBVC_20ms_Group05_Reserved2";
BA_ "CompuMethodName" SG_ 291 IUsgMdBkupV "UsgMdBkupV";
BA_ "ISignalName" SG_ 291 IUsgMdBkupV "IUsgMdBkupV";
BA_ "LongName" SG_ 291 IUsgMdBkupV "Usage Mode Left Backup Validity";
BA_ "SysSignalName" SG_ 291 IUsgMdBkupV "UsgMdBkupV";
BA_ "CompuMethodName" SG_ 291 IUsgMdBkup "UsgMdBkup";
BA_ "GenSigStartValue" SG_ 291 IUsgMdBkup 1;
BA_ "ISignalName" SG_ 291 IUsgMdBkup "IUsgMdBkup";
BA_ "LongName" SG_ 291 IUsgMdBkup "Usage Mode Left Backup";
BA_ "SysSignalName" SG_ 291 IUsgMdBkup "UsgMdBkup";
BA_ "CompuMethodName" SG_ 291 IICBVC_20ms_Group05_Reserved3 "ICBVC_20ms_Group05_Reserved3";
BA_ "GenSigStartValue" SG_ 291 IICBVC_20ms_Group05_Reserved3 7;
BA_ "ISignalName" SG_ 291 IICBVC_20ms_Group05_Reserved3 "IICBVC_20ms_Group05_Reserved3";
BA_ "SysSignalName" SG_ 291 IICBVC_20ms_Group05_Reserved3 "ICBVC_20ms_Group05_Reserved3";
BA_ "CompuMethodName" SG_ 291 IVehMdBkupV "VehMdBkupV";
BA_ "ISignalName" SG_ 291 IVehMdBkupV "IVehMdBkupV";
BA_ "LongName" SG_ 291 IVehMdBkupV "Vehicle Mode Left Backup Validity";
BA_ "SysSignalName" SG_ 291 IVehMdBkupV "VehMdBkupV";
BA_ "CompuMethodName" SG_ 291 IVehMdBkup "VehMdBkup";
BA_ "ISignalName" SG_ 291 IVehMdBkup "IVehMdBkup";
BA_ "LongName" SG_ 291 IVehMdBkup "Vehicle Mode Left Backup";
BA_ "SysSignalName" SG_ 291 IVehMdBkup "VehMdBkup";
BA_ "CompuMethodName" SG_ 291 IICBVC_20ms_Group05_Reserved4 "ICBVC_20ms_Group05_Reserved4";
BA_ "GenSigStartValue" SG_ 291 IICBVC_20ms_Group05_Reserved4 255;
BA_ "ISignalName" SG_ 291 IICBVC_20ms_Group05_Reserved4 "IICBVC_20ms_Group05_Reserved4";
BA_ "SysSignalName" SG_ 291 IICBVC_20ms_Group05_Reserved4 "ICBVC_20ms_Group05_Reserved4";
BA_ "CompuMethodName" SG_ 291 IICBVC_20ms_Group05_Reserved5 "ICBVC_20ms_Group05_Reserved5";
BA_ "GenSigStartValue" SG_ 291 IICBVC_20ms_Group05_Reserved5 255;
BA_ "ISignalName" SG_ 291 IICBVC_20ms_Group05_Reserved5 "IICBVC_20ms_Group05_Reserved5";
BA_ "SysSignalName" SG_ 291 IICBVC_20ms_Group05_Reserved5 "ICBVC_20ms_Group05_Reserved5";
BA_ "CompuMethodName" SG_ 291 IICBVC_20ms_Group05_Reserved6 "ICBVC_20ms_Group05_Reserved6";
BA_ "GenSigStartValue" SG_ 291 IICBVC_20ms_Group05_Reserved6 255;
BA_ "ISignalName" SG_ 291 IICBVC_20ms_Group05_Reserved6 "IICBVC_20ms_Group05_Reserved6";
BA_ "SysSignalName" SG_ 291 IICBVC_20ms_Group05_Reserved6 "ICBVC_20ms_Group05_Reserved6";
BA_ "CompuMethodName" SG_ 291 IICBVC_20ms_Group05_Reserved7 "ICBVC_20ms_Group05_Reserved7";
BA_ "GenSigStartValue" SG_ 291 IICBVC_20ms_Group05_Reserved7 255;
BA_ "ISignalName" SG_ 291 IICBVC_20ms_Group05_Reserved7 "IICBVC_20ms_Group05_Reserved7";
BA_ "SysSignalName" SG_ 291 IICBVC_20ms_Group05_Reserved7 "ICBVC_20ms_Group05_Reserved7";
BA_ "CompuMethodName" SG_ 982 IACCDetObjLongtRltvDist "ACCDetObjLongtRltvDist";
BA_ "ISignalName" SG_ 982 IACCDetObjLongtRltvDist "IACCDetObjLongtRltvDist";
BA_ "LongName" SG_ 982 IACCDetObjLongtRltvDist "Adaptive_Cruise_Control_Detected_Object_Longitudinal_Relative_Distance";
BA_ "SysSignalName" SG_ 982 IACCDetObjLongtRltvDist "ACCDetObjLongtRltvDist";
BA_ "CompuMethodName" SG_ 982 IACCDetObjSyncCtr "ACCDetObjSyncCtr";
BA_ "ISignalName" SG_ 982 IACCDetObjSyncCtr "IACCDetObjSyncCtr";
BA_ "LongName" SG_ 982 IACCDetObjSyncCtr "Adaptive_Cruise_Control_Detected_Object_Synchronize_Counter";
BA_ "SysSignalName" SG_ 982 IACCDetObjSyncCtr "ACCDetObjSyncCtr";
BA_ "CompuMethodName" SG_ 982 IACCDetObjLongtRltvSpd "ACCDetObjLongtRltvSpd";
BA_ "ISignalName" SG_ 982 IACCDetObjLongtRltvSpd "IACCDetObjLongtRltvSpd";
BA_ "LongName" SG_ 982 IACCDetObjLongtRltvSpd "Adaptive_Cruise_Control_Detected_Object_Longitudinal_Relative_Speed";
BA_ "SysSignalName" SG_ 982 IACCDetObjLongtRltvSpd "ACCDetObjLongtRltvSpd";
BA_ "CompuMethodName" SG_ 982 IACCDetObjTyp "ACCDetObjTyp";
BA_ "ISignalName" SG_ 982 IACCDetObjTyp "IACCDetObjTyp";
BA_ "LongName" SG_ 982 IACCDetObjTyp "Adaptive_Cruise_Control_Detected_Object_0_Type";
BA_ "SysSignalName" SG_ 982 IACCDetObjTyp "ACCDetObjTyp";
BA_ "CompuMethodName" SG_ 982 IACCDetObjLatRltvDist "ACCDetObjLatRltvDist";
BA_ "ISignalName" SG_ 982 IACCDetObjLatRltvDist "IACCDetObjLatRltvDist";
BA_ "LongName" SG_ 982 IACCDetObjLatRltvDist "Adaptive_Cruise_Control_Detected_Object_Lateral_Relative_Distance";
BA_ "SysSignalName" SG_ 982 IACCDetObjLatRltvDist "ACCDetObjLatRltvDist";
BA_ "CompuMethodName" SG_ 982 IACCDetObjExistPrblty "ACCDetObjExistPrblty";
BA_ "ISignalName" SG_ 982 IACCDetObjExistPrblty "IACCDetObjExistPrblty";
BA_ "LongName" SG_ 982 IACCDetObjExistPrblty "Adaptive_Cruise_Control_Detected_Object_Exist_Probability";
BA_ "SysSignalName" SG_ 982 IACCDetObjExistPrblty "ACCDetObjExistPrblty";
BA_ "CompuMethodName" SG_ 982 IACCDetObjId "ACCDetObjId";
BA_ "ISignalName" SG_ 982 IACCDetObjId "IACCDetObjId";
BA_ "LongName" SG_ 982 IACCDetObjId "Adaptive_Cruise_Control_Detected_Object_Identifier";
BA_ "SysSignalName" SG_ 982 IACCDetObjId "ACCDetObjId";
BA_ "CompuMethodName" SG_ 1202 IIPD_NM_BSMtoRMS_PTCANFD "IPD_NM_BSMtoRMS_PTCANFD";
BA_ "ISignalName" SG_ 1202 IIPD_NM_BSMtoRMS_PTCANFD "IIPD_NM_BSMtoRMS_PTCANFD";
BA_ "LongName" SG_ 1202 IIPD_NM_BSMtoRMS_PTCANFD "IPD_NM_BSMtoRMS_PTCANFD";
BA_ "SysSignalName" SG_ 1202 IIPD_NM_BSMtoRMS_PTCANFD "IPD_NM_BSMtoRMS_PTCANFD";
BA_ "CompuMethodName" SG_ 1202 IIPD_NM_PBSMtoRMS_PTCANFD "IPD_NM_PBSMtoRMS_PTCANFD";
BA_ "ISignalName" SG_ 1202 IIPD_NM_PBSMtoRMS_PTCANFD "IIPD_NM_PBSMtoRMS_PTCANFD";
BA_ "LongName" SG_ 1202 IIPD_NM_PBSMtoRMS_PTCANFD "IPD_NM_PBSMtoRMS_PTCANFD";
BA_ "SysSignalName" SG_ 1202 IIPD_NM_PBSMtoRMS_PTCANFD "IPD_NM_PBSMtoRMS_PTCANFD";
BA_ "CompuMethodName" SG_ 1202 IIPD_NM_RMStoNOS_PTCANFD "IPD_NM_RMStoNOS_PTCANFD";
BA_ "ISignalName" SG_ 1202 IIPD_NM_RMStoNOS_PTCANFD "IIPD_NM_RMStoNOS_PTCANFD";
BA_ "LongName" SG_ 1202 IIPD_NM_RMStoNOS_PTCANFD "IPD_NM_RMStoNOS_PTCANFD";
BA_ "SysSignalName" SG_ 1202 IIPD_NM_RMStoNOS_PTCANFD "IPD_NM_RMStoNOS_PTCANFD";
BA_ "CompuMethodName" SG_ 1202 IIPD_NM_RSStoNOS_PTCANFD "IPD_NM_RSStoNOS_PTCANFD";
BA_ "ISignalName" SG_ 1202 IIPD_NM_RSStoNOS_PTCANFD "IIPD_NM_RSStoNOS_PTCANFD";
BA_ "LongName" SG_ 1202 IIPD_NM_RSStoNOS_PTCANFD "IPD_NM_RSStoNOS_PTCANFD";
BA_ "SysSignalName" SG_ 1202 IIPD_NM_RSStoNOS_PTCANFD "IPD_NM_RSStoNOS_PTCANFD";
BA_ "CompuMethodName" SG_ 1202 IIPD_NM_RSStoRMS_PTCANFD "IPD_NM_RSStoRMS_PTCANFD";
BA_ "ISignalName" SG_ 1202 IIPD_NM_RSStoRMS_PTCANFD "IIPD_NM_RSStoRMS_PTCANFD";
BA_ "LongName" SG_ 1202 IIPD_NM_RSStoRMS_PTCANFD "IPD_NM_RSStoRMS_PTCANFD";
BA_ "SysSignalName" SG_ 1202 IIPD_NM_RSStoRMS_PTCANFD "IPD_NM_RSStoRMS_PTCANFD";
BA_ "CompuMethodName" SG_ 1202 IIPD_NM_NOStoRMS_PTCANFD "IPD_NM_NOStoRMS_PTCANFD";
BA_ "ISignalName" SG_ 1202 IIPD_NM_NOStoRMS_PTCANFD "IIPD_NM_NOStoRMS_PTCANFD";
BA_ "LongName" SG_ 1202 IIPD_NM_NOStoRMS_PTCANFD "IPD_NM_NOStoRMS_PTCANFD";
BA_ "SysSignalName" SG_ 1202 IIPD_NM_NOStoRMS_PTCANFD "IPD_NM_NOStoRMS_PTCANFD";
BA_ "CompuMethodName" SG_ 1202 IIPD_NM_NOSSta_PTCANFD "IPD_NM_NOSSta_PTCANFD";
BA_ "ISignalName" SG_ 1202 IIPD_NM_NOSSta_PTCANFD "IIPD_NM_NOSSta_PTCANFD";
BA_ "LongName" SG_ 1202 IIPD_NM_NOSSta_PTCANFD "IPD_NM_NOSSta_PTCANFD";
BA_ "SysSignalName" SG_ 1202 IIPD_NM_NOSSta_PTCANFD "IPD_NM_NOSSta_PTCANFD";
BA_ "CompuMethodName" SG_ 1202 IIPD_NM_RMSSta_PTCANFD "IPD_NM_RMSSta_PTCANFD";
BA_ "ISignalName" SG_ 1202 IIPD_NM_RMSSta_PTCANFD "IIPD_NM_RMSSta_PTCANFD";
BA_ "LongName" SG_ 1202 IIPD_NM_RMSSta_PTCANFD "IPD_NM_RMSSta_PTCANFD";
BA_ "SysSignalName" SG_ 1202 IIPD_NM_RMSSta_PTCANFD "IPD_NM_RMSSta_PTCANFD";
BA_ "CompuMethodName" SG_ 1202 IIPD_NWI_PTCANFD "IPD_NWI_PTCANFD";
BA_ "ISignalName" SG_ 1202 IIPD_NWI_PTCANFD "IIPD_NWI_PTCANFD";
BA_ "LongName" SG_ 1202 IIPD_NWI_PTCANFD "IPD_PTCANFD Network Wakeup Indication";
BA_ "SysSignalName" SG_ 1202 IIPD_NWI_PTCANFD "IPD_NWI_PTCANFD";
BA_ "CompuMethodName" SG_ 1202 IIPD_NOI_PTCANFD "IPD_NOI_PTCANFD";
BA_ "ISignalName" SG_ 1202 IIPD_NOI_PTCANFD "IIPD_NOI_PTCANFD";
BA_ "LongName" SG_ 1202 IIPD_NOI_PTCANFD "IPD PTCANFD Network Operation Indication";
BA_ "SysSignalName" SG_ 1202 IIPD_NOI_PTCANFD "IPD_NOI_PTCANFD";
BA_ "CompuMethodName" SG_ 1202 IIPD_NKI_PTCANFD "IPD_NKI_PTCANFD";
BA_ "ISignalName" SG_ 1202 IIPD_NKI_PTCANFD "IIPD_NKI_PTCANFD";
BA_ "LongName" SG_ 1202 IIPD_NKI_PTCANFD "IPD PTCANFD Network Keep Indication";
BA_ "SysSignalName" SG_ 1202 IIPD_NKI_PTCANFD "IPD_NKI_PTCANFD";
BA_ "CompuMethodName" SG_ 1170 IPEU_NM_BSMtoRMS_PTCANFD "PEU_NM_BSMtoRMS_PTCANFD";
BA_ "ISignalName" SG_ 1170 IPEU_NM_BSMtoRMS_PTCANFD "IPEU_NM_BSMtoRMS_PTCANFD";
BA_ "LongName" SG_ 1170 IPEU_NM_BSMtoRMS_PTCANFD "PEU_NM_BSMtoRMS_PTCANFD";
BA_ "SysSignalName" SG_ 1170 IPEU_NM_BSMtoRMS_PTCANFD "PEU_NM_BSMtoRMS_PTCANFD";
BA_ "CompuMethodName" SG_ 1170 IPEU_NM_PBSMtoRMS_PTCANFD "PEU_NM_PBSMtoRMS_PTCANFD";
BA_ "ISignalName" SG_ 1170 IPEU_NM_PBSMtoRMS_PTCANFD "IPEU_NM_PBSMtoRMS_PTCANFD";
BA_ "LongName" SG_ 1170 IPEU_NM_PBSMtoRMS_PTCANFD "PEU_NM_PBSMtoRMS_PTCANFD";
BA_ "SysSignalName" SG_ 1170 IPEU_NM_PBSMtoRMS_PTCANFD "PEU_NM_PBSMtoRMS_PTCANFD";
BA_ "CompuMethodName" SG_ 1170 IPEU_NM_RMStoNOS_PTCANFD "PEU_NM_RMStoNOS_PTCANFD";
BA_ "ISignalName" SG_ 1170 IPEU_NM_RMStoNOS_PTCANFD "IPEU_NM_RMStoNOS_PTCANFD";
BA_ "LongName" SG_ 1170 IPEU_NM_RMStoNOS_PTCANFD "PEU_NM_RMStoNOS_PTCANFD";
BA_ "SysSignalName" SG_ 1170 IPEU_NM_RMStoNOS_PTCANFD "PEU_NM_RMStoNOS_PTCANFD";
BA_ "CompuMethodName" SG_ 1170 IPEU_NM_RSStoNOS_PTCANFD "PEU_NM_RSStoNOS_PTCANFD";
BA_ "ISignalName" SG_ 1170 IPEU_NM_RSStoNOS_PTCANFD "IPEU_NM_RSStoNOS_PTCANFD";
BA_ "LongName" SG_ 1170 IPEU_NM_RSStoNOS_PTCANFD "PEU_NM_RSStoNOS_PTCANFD";
BA_ "SysSignalName" SG_ 1170 IPEU_NM_RSStoNOS_PTCANFD "PEU_NM_RSStoNOS_PTCANFD";
BA_ "CompuMethodName" SG_ 1170 IPEU_NM_RSStoRMS_PTCANFD "PEU_NM_RSStoRMS_PTCANFD";
BA_ "ISignalName" SG_ 1170 IPEU_NM_RSStoRMS_PTCANFD "IPEU_NM_RSStoRMS_PTCANFD";
BA_ "LongName" SG_ 1170 IPEU_NM_RSStoRMS_PTCANFD "PEU_NM_RSStoRMS_PTCANFD";
BA_ "SysSignalName" SG_ 1170 IPEU_NM_RSStoRMS_PTCANFD "PEU_NM_RSStoRMS_PTCANFD";
BA_ "CompuMethodName" SG_ 1170 IPEU_NM_NOStoRMS_PTCANFD "PEU_NM_NOStoRMS_PTCANFD";
BA_ "ISignalName" SG_ 1170 IPEU_NM_NOStoRMS_PTCANFD "IPEU_NM_NOStoRMS_PTCANFD";
BA_ "LongName" SG_ 1170 IPEU_NM_NOStoRMS_PTCANFD "PEU_NM_NOStoRMS_PTCANFD";
BA_ "SysSignalName" SG_ 1170 IPEU_NM_NOStoRMS_PTCANFD "PEU_NM_NOStoRMS_PTCANFD";
BA_ "CompuMethodName" SG_ 1170 IPEU_NM_NOSSta_PTCANFD "PEU_NM_NOSSta_PTCANFD";
BA_ "ISignalName" SG_ 1170 IPEU_NM_NOSSta_PTCANFD "IPEU_NM_NOSSta_PTCANFD";
BA_ "LongName" SG_ 1170 IPEU_NM_NOSSta_PTCANFD "PEU_NM_NOSSta_PTCANFD";
BA_ "SysSignalName" SG_ 1170 IPEU_NM_NOSSta_PTCANFD "PEU_NM_NOSSta_PTCANFD";
BA_ "CompuMethodName" SG_ 1170 IPEU_NM_RMSSta_PTCANFD "PEU_NM_RMSSta_PTCANFD";
BA_ "ISignalName" SG_ 1170 IPEU_NM_RMSSta_PTCANFD "IPEU_NM_RMSSta_PTCANFD";
BA_ "LongName" SG_ 1170 IPEU_NM_RMSSta_PTCANFD "PEU_NM_RMSSta_PTCANFD";
BA_ "SysSignalName" SG_ 1170 IPEU_NM_RMSSta_PTCANFD "PEU_NM_RMSSta_PTCANFD";
BA_ "CompuMethodName" SG_ 1170 IPEU_NWI_PTCANFD "PEU_NWI_PTCANFD";
BA_ "ISignalName" SG_ 1170 IPEU_NWI_PTCANFD "IPEU_NWI_PTCANFD";
BA_ "LongName" SG_ 1170 IPEU_NWI_PTCANFD "PEU PTCANFD Network_Wakeup_Indication";
BA_ "SysSignalName" SG_ 1170 IPEU_NWI_PTCANFD "PEU_NWI_PTCANFD";
BA_ "CompuMethodName" SG_ 1170 IPEU_NOI_PTCANFD "PEU_NOI_PTCANFD";
BA_ "ISignalName" SG_ 1170 IPEU_NOI_PTCANFD "IPEU_NOI_PTCANFD";
BA_ "LongName" SG_ 1170 IPEU_NOI_PTCANFD "PEU PTCANFD Network Operation Indication";
BA_ "SysSignalName" SG_ 1170 IPEU_NOI_PTCANFD "PEU_NOI_PTCANFD";
BA_ "CompuMethodName" SG_ 1170 IPEU_NKI_PTCANFD "PEU_NKI_PTCANFD";
BA_ "ISignalName" SG_ 1170 IPEU_NKI_PTCANFD "IPEU_NKI_PTCANFD";
BA_ "LongName" SG_ 1170 IPEU_NKI_PTCANFD "PEU PTCANFD Network Keep Indication";
BA_ "SysSignalName" SG_ 1170 IPEU_NKI_PTCANFD "PEU_NKI_PTCANFD";
BA_ "CompuMethodName" SG_ 983 ITCSOpngMdVMC "TCSOpngMdVMC";
BA_ "ISignalName" SG_ 983 ITCSOpngMdVMC "ITCSOpngMdVMC";
BA_ "LongName" SG_ 983 ITCSOpngMdVMC "Traction Control System Operating Mode VMC";
BA_ "SysSignalName" SG_ 983 ITCSOpngMdVMC "TCSOpngMdVMC";
BA_ "CompuMethodName" SG_ 983 IPwrLftgtCtrlSrc "PwrLftgtCtrlSrc";
BA_ "ISignalName" SG_ 983 IPwrLftgtCtrlSrc "IPwrLftgtCtrlSrc";
BA_ "LongName" SG_ 983 IPwrLftgtCtrlSrc "Power Liftgate Control Source";
BA_ "SysSignalName" SG_ 983 IPwrLftgtCtrlSrc "PwrLftgtCtrlSrc";
BA_ "CompuMethodName" SG_ 983 IACMdMotFaltSts_Rr "ACMdMotFaltSts_Rr";
BA_ "ISignalName" SG_ 983 IACMdMotFaltSts_Rr "IACMdMotFaltSts_Rr";
BA_ "LongName" SG_ 983 IACMdMotFaltSts_Rr "Air Conditioning Rear Mode Actuator Status";
BA_ "SysSignalName" SG_ 983 IACMdMotFaltSts_Rr "ACMdMotFaltSts_Rr";
BA_ "CompuMethodName" SG_ 983 IVSEMdVMC "VSEMdVMC";
BA_ "ISignalName" SG_ 983 IVSEMdVMC "IVSEMdVMC";
BA_ "LongName" SG_ 983 IVSEMdVMC "Vehicle Stability Enhancement Mode VMC";
BA_ "SysSignalName" SG_ 983 IVSEMdVMC "VSEMdVMC";
BA_ "CompuMethodName" SG_ 983 IACMdMotActPcnt_Rr "ACMdMotActPcnt_Rr";
BA_ "ISignalName" SG_ 983 IACMdMotActPcnt_Rr "IACMdMotActPcnt_Rr";
BA_ "LongName" SG_ 983 IACMdMotActPcnt_Rr "Air Conditioning Rear Mode Actuator Percent";
BA_ "SysSignalName" SG_ 983 IACMdMotActPcnt_Rr "ACMdMotActPcnt_Rr";
BA_ "CompuMethodName" SG_ 983 IOnBdChrgrSktNgtvSnsrTemV "OnBdChrgrSktNgtvSnsrTemV";
BA_ "GenSigStartValue" SG_ 983 IOnBdChrgrSktNgtvSnsrTemV 1;
BA_ "ISignalName" SG_ 983 IOnBdChrgrSktNgtvSnsrTemV "IOnBdChrgrSktNgtvSnsrTemV";
BA_ "LongName" SG_ 983 IOnBdChrgrSktNgtvSnsrTemV "On Board Charger Socket Negative Sensor Temperature Validity";
BA_ "SysSignalName" SG_ 983 IOnBdChrgrSktNgtvSnsrTemV "OnBdChrgrSktNgtvSnsrTemV";
BA_ "CompuMethodName" SG_ 983 IOfbdChrgrPstvSktTemV "OfbdChrgrPstvSktTemV";
BA_ "GenSigStartValue" SG_ 983 IOfbdChrgrPstvSktTemV 1;
BA_ "ISignalName" SG_ 983 IOfbdChrgrPstvSktTemV "IOfbdChrgrPstvSktTemV";
BA_ "LongName" SG_ 983 IOfbdChrgrPstvSktTemV "Offboard Charger Positive Socket Temperature Validity";
BA_ "SysSignalName" SG_ 983 IOfbdChrgrPstvSktTemV "OfbdChrgrPstvSktTemV";
BA_ "CompuMethodName" SG_ 983 IPwrLftgtCtrl "PwrLftgtCtrl";
BA_ "ISignalName" SG_ 983 IPwrLftgtCtrl "IPwrLftgtCtrl";
BA_ "LongName" SG_ 983 IPwrLftgtCtrl "Power Liftgate Control";
BA_ "SysSignalName" SG_ 983 IPwrLftgtCtrl "PwrLftgtCtrl";
BA_ "CompuMethodName" SG_ 983 IPwrLftgtThrmlSts "PwrLftgtThrmlSts";
BA_ "ISignalName" SG_ 983 IPwrLftgtThrmlSts "IPwrLftgtThrmlSts";
BA_ "LongName" SG_ 983 IPwrLftgtThrmlSts "Power Liftgate Thermal Status";
BA_ "SysSignalName" SG_ 983 IPwrLftgtThrmlSts "PwrLftgtThrmlSts";
BA_ "CompuMethodName" SG_ 983 IPwrLftgtCinchLtchCtrl "PwrLftgtCinchLtchCtrl";
BA_ "ISignalName" SG_ 983 IPwrLftgtCinchLtchCtrl "IPwrLftgtCinchLtchCtrl";
BA_ "LongName" SG_ 983 IPwrLftgtCinchLtchCtrl "Power Lift Gate Cinch Latch Control";
BA_ "SysSignalName" SG_ 983 IPwrLftgtCinchLtchCtrl "PwrLftgtCinchLtchCtrl";
BA_ "CompuMethodName" SG_ 983 IPwrLftgtCinchLtchSts "PwrLftgtCinchLtchSts";
BA_ "ISignalName" SG_ 983 IPwrLftgtCinchLtchSts "IPwrLftgtCinchLtchSts";
BA_ "LongName" SG_ 983 IPwrLftgtCinchLtchSts "Power Lift Gate Cinch Latch Status";
BA_ "SysSignalName" SG_ 983 IPwrLftgtCinchLtchSts "PwrLftgtCinchLtchSts";
BA_ "CompuMethodName" SG_ 983 IPwrLftgtCinchLtchThrmlSts "PwrLftgtCinchLtchThrmlSts";
BA_ "ISignalName" SG_ 983 IPwrLftgtCinchLtchThrmlSts "IPwrLftgtCinchLtchThrmlSts";
BA_ "LongName" SG_ 983 IPwrLftgtCinchLtchThrmlSts "Power Lift Gate Cinch Latch Thermal Status";
BA_ "SysSignalName" SG_ 983 IPwrLftgtCinchLtchThrmlSts "PwrLftgtCinchLtchThrmlSts";
BA_ "CompuMethodName" SG_ 983 IPwrLftgtPnchSts "PwrLftgtPnchSts";
BA_ "ISignalName" SG_ 983 IPwrLftgtPnchSts "IPwrLftgtPnchSts";
BA_ "LongName" SG_ 983 IPwrLftgtPnchSts "Power Liftgate Pinch Status";
BA_ "SysSignalName" SG_ 983 IPwrLftgtPnchSts "PwrLftgtPnchSts";
BA_ "CompuMethodName" SG_ 983 IOfbdChrgrPstvSktTem "OfbdChrgrPstvSktTem";
BA_ "GenSigStartValue" SG_ 983 IOfbdChrgrPstvSktTem 254;
BA_ "ISignalName" SG_ 983 IOfbdChrgrPstvSktTem "IOfbdChrgrPstvSktTem";
BA_ "LongName" SG_ 983 IOfbdChrgrPstvSktTem "Offboard Charger Positive Socket Temperature";
BA_ "SysSignalName" SG_ 983 IOfbdChrgrPstvSktTem "OfbdChrgrPstvSktTem";
BA_ "CompuMethodName" SG_ 983 IOnBdChrgrSktNgtvSnsrTem "OnBdChrgrSktNgtvSnsrTem";
BA_ "ISignalName" SG_ 983 IOnBdChrgrSktNgtvSnsrTem "IOnBdChrgrSktNgtvSnsrTem";
BA_ "LongName" SG_ 983 IOnBdChrgrSktNgtvSnsrTem "On Board Charger Socket Negative Sensor Temperature";
BA_ "SysSignalName" SG_ 983 IOnBdChrgrSktNgtvSnsrTem "OnBdChrgrSktNgtvSnsrTem";
BA_ "CompuMethodName" SG_ 983 IPLGStpReason "PLGStpReason";
BA_ "ISignalName" SG_ 983 IPLGStpReason "IPLGStpReason";
BA_ "LongName" SG_ 983 IPLGStpReason "Power Liftgate Stop Reason";
BA_ "SysSignalName" SG_ 983 IPLGStpReason "PLGStpReason";
BA_ "CompuMethodName" SG_ 983 IPwrLftgtFailRmndr "PwrLftgtFailRmndr";
BA_ "ISignalName" SG_ 983 IPwrLftgtFailRmndr "IPwrLftgtFailRmndr";
BA_ "LongName" SG_ 983 IPwrLftgtFailRmndr "Power Liftgate Failed Reminder";
BA_ "SysSignalName" SG_ 983 IPwrLftgtFailRmndr "PwrLftgtFailRmndr";

VAL_ 992 ICCUOnbdChrgrPlugOnV 0 "CCUOnbdChrgrPlugOnV_0_Valid" 1 "CCUOnbdChrgrPlugOnV_1_Invalid";
VAL_ 992 IOnBdChrgrCtrlPilotPWMSts 0 "OnBdChrgrCtrlPilotPWMSts_0_Cp9v" 1 "OnBdChrgrCtrlPilotPWMSts_1_Cp0v" 2 "OnBdChrgrCtrlPilotPWMSts_2_Cp9vPwm" 3 "OnBdChrgrCtrlPilotPWMSts_3_Cp6v" 4 "OnBdChrgrCtrlPilotPWMSts_4_Cp6vPwm" 5 "OnBdChrgrCtrlPilotPWMSts_5_Cp12v" 6 "OnBdChrgrCtrlPilotPWMSts_6_Cp12vPwm" 7 "OnBdChrgrCtrlPilotPWMSts_7_CpOutOfRange";
VAL_ 992 IOnBdChrgrWkup 0 "OnBdChrgrWkup_0_False" 1 "OnBdChrgrWkup_1_True";
VAL_ 992 IOnBdChrgrSts 0 "OnBdChrgrSts_0_idle" 1 "OnBdChrgrSts_1_Power_up" 3 "OnBdChrgrSts_3_Ready" 4 "OnBdChrgrSts_4_Pending" 5 "OnBdChrgrSts_5_Charging" 6 "OnBdChrgrSts_6_Discharging" 7 "OnBdChrgrSts_7_Warning" 9 "OnBdChrgrSts_9_Fault" 10 "OnBdChrgrSts_10_Stop" 12 "OnBdChrgrSts_12_Power_off";
VAL_ 992 IOnbdChrgrOtptCrntV 0 "OnbdChrgrOtptCrntV_0_Valid" 1 "OnbdChrgrOtptCrntV_1_InValid";
VAL_ 992 IOnbdChrgrOpngMd 0 "OnbdChrgrOpngMd_0_Default" 1 "OnbdChrgrOpngMd_1_ChargingMode" 2 "OnbdChrgrOpngMd_2_V2lMode" 3 "OnbdChrgrOpngMd_3_V2vMode" 4 "OnbdChrgrOpngMd_4_V2gMode" 5 "OnbdChrgrOpngMd_5_HeatingMode";
VAL_ 992 IOnBdChrgrOtptVolV 0 "OnBdChrgrOtptVolV_0_Valid" 1 "OnBdChrgrOtptVolV_1_Invalid";
VAL_ 992 ICCUActiveWkup 0 "CCUActiveWkup_0_False" 1 "CCUActiveWkup_1_True";
VAL_ 992 ICCUOnbdChrgrPlugOn 0 "CCUOnbdChrgrPlugOn_0_Disconnected" 1 "CCUOnbdChrgrPlugOn_1_Connected_GunIs63a" 2 "CCUOnbdChrgrPlugOn_2_Connected_GunIs32a" 3 "CCUOnbdChrgrPlugOn_3_Connected_GunIs16a" 4 "CCUOnbdChrgrPlugOn_4_Connected_GunIs10a" 5 "CCUOnbdChrgrPlugOn_5_Semi_connected" 6 "CCUOnbdChrgrPlugOn_6_AbnormalConnected" 7 "CCUOnbdChrgrPlugOn_7_V2lConnected" 8 "CCUOnbdChrgrPlugOn_8_V2gConnected" 9 "CCUOnbdChrgrPlugOn_9_UnknowConnected";
VAL_ 992 ICCUOnbdChrgrSpRsn 0 "CCUOnbdChrgrSpRsn_0_Default" 1 "CCUOnbdChrgrSpRsn_1_Grid_Fault" 3 "CCUOnbdChrgrSpRsn_3_Charging_Device_Fault" 5 "CCUOnbdChrgrSpRsn_5_OBC_Fault" 7 "CCUOnbdChrgrSpRsn_7_Charging_System_Abnormal" 9 "CCUOnbdChrgrSpRsn_9_Charging_Socket_Over_Temperature" 10 "CCUOnbdChrgrSpRsn_10_Ambient_Temperature_Abnormal" 11 "CCUOnbdChrgrSpRsn_11_Coolant_Pump_Abnormal" 12 "CCUOnbdChrgrSpRsn_12_V2L_Over_Load";
VAL_ 992 IOnBdChrgrLastWkup 0 "OnBdChrgrLastWkup_0_FLASE" 1 "OnBdChrgrLastWkup_1_TURE";
VAL_ 1248 ICCU_NM_BSMtoRMS_PTCANFD 0 "CCU_NM_BSMtoRMS_PTCANFD_0_CCU_NM_BSMtoRMS_0_False" 1 "CCU_NM_BSMtoRMS_PTCANFD_1_CCU_NM_BSMtoRMS_1_True";
VAL_ 1248 ICCU_NM_PBSMtoRMS_PTCANFD 0 "CCU_NM_PBSMtoRMS_PTCANFD_0_CCU_NM_PBSMtoRMS_0_False" 1 "CCU_NM_PBSMtoRMS_PTCANFD_1_CCU_NM_PBSMtoRMS_1_True";
VAL_ 1248 ICCU_NM_RMStoNOS_PTCANFD 0 "CCU_NM_RMStoNOS_PTCANFD_0_CCU_NM_RMStoNOS_0_False" 1 "CCU_NM_RMStoNOS_PTCANFD_1_CCU_NM_RMStoNOS_1_True";
VAL_ 1248 ICCU_NM_RSStoNOS_PTCANFD 0 "CCU_NM_RSStoNOS_PTCANFD_0_CCU_NM_RSStoNOS_0_False" 1 "CCU_NM_RSStoNOS_PTCANFD_1_CCU_NM_RSStoNOS_1_True";
VAL_ 1248 ICCU_NM_RSStoRMS_PTCANFD 0 "CCU_NM_RSStoRMS_PTCANFD_0_CCU_NM_RSStoRMS_0_False" 1 "CCU_NM_RSStoRMS_PTCANFD_1_CCU_NM_RSStoRMS_1_True";
VAL_ 1248 ICCU_NM_NOStoRMS_PTCANFD 0 "CCU_NM_NOStoRMS_PTCANFD_0_CCU_NM_NOStoRMS_0_False" 1 "CCU_NM_NOStoRMS_PTCANFD_1_CCU_NM_NOStoRMS_1_True";
VAL_ 1248 ICCU_NM_NOSSta_PTCANFD 0 "CCU_NM_NOSSta_PTCANFD_0_CCU_NM_NOSSta_0_False" 1 "CCU_NM_NOSSta_PTCANFD_1_CCU_NM_NOSSta_1_True";
VAL_ 1248 ICCU_NM_RMSSta_PTCANFD 0 "CCU_NM_RMSSta_PTCANFD_0_CCU_NM_RMSSta_0_False" 1 "CCU_NM_RMSSta_PTCANFD_1_CCU_NM_RMSSta_1_True";
VAL_ 1248 ICCU_NWI_PTCANFD 0 "CCU_NWI_PTCANFD_0_NoWakeNetworkSource" 1 "CCU_NWI_PTCANFD_1_Reserved" 2 "CCU_NWI_PTCANFD_2_OnboardChargerConnected";
VAL_ 1248 ICCU_NOI_PTCANFD 0 "CCU_NOI_PTCANFD_0_NoRequest" 65535 "CCU_NOI_PTCANFD_65535_AllNetworkOperationActive";
VAL_ 1248 ICCU_NKI_PTCANFD 0 "CCU_NKI_PTCANFD_0_NoRequest" 1 "CCU_NKI_PTCANFD_1_PowerModeIsNonOFF";
VAL_ 1172 IECM_NM_BSMtoRMS_PTCANFD 0 "ECM_NM_BSMtoRMS_PTCANFD_0_False" 1 "ECM_NM_BSMtoRMS_PTCANFD_1_True";
VAL_ 1172 IECM_NM_PBSMtoRMS_PTCANFD 0 "ECM_NM_PBSMtoRMS_PTCANFD_0_False" 1 "ECM_NM_PBSMtoRMS_PTCANFD_1_True";
VAL_ 1172 IECM_NM_RMStoNOS_PTCANFD 0 "ECM_NM_RMStoNOS_PTCANFD_0_False" 1 "ECM_NM_RMStoNOS_PTCANFD_1_True";
VAL_ 1172 IECM_NM_RSStoNOS_PTCANFD 0 "ECM_NM_RSStoNOS_PTCANFD_0_False" 1 "ECM_NM_RSStoNOS_PTCANFD_1_True";
VAL_ 1172 IECM_NM_RSStoRMS_PTCANFD 0 "ECM_NM_RSStoRMS_PTCANFD_0_False" 1 "ECM_NM_RSStoRMS_PTCANFD_1_True";
VAL_ 1172 IECM_NM_NOStoRMS_PTCANFD 0 "ECM_NM_NOStoRMS_PTCANFD_0_False" 1 "ECM_NM_NOStoRMS_PTCANFD_1_True";
VAL_ 1172 IECM_NM_NOSSta_PTCANFD 0 "ECM_NM_NOSSta_PTCANFD_0_False" 1 "ECM_NM_NOSSta_PTCANFD_1_True";
VAL_ 1172 IECM_NM_RMSSta_PTCANFD 0 "ECM_NM_RMSSta_PTCANFD_0_False" 1 "ECM_NM_RMSSta_PTCANFD_1_True";
VAL_ 1172 IECM_NWI_PTCANFD 0 "ECM_NWI_PTCANFD_0_NoRequest";
VAL_ 1172 IECM_NOI_PTCANFD 0 "ECM_NOI_PTCANFD_0_NoRequest" 65535 "ECM_NOI_PTCANFD_65535_AllNetworkOperationActive";
VAL_ 1172 IECM_NKI_PTCANFD 0 "ECM_NKI_PTCANFD_0_NoRequest";
VAL_ 788 IBMSAltngChrgCrntResp 0 "BMSAltngChrgCrntResp_0_Default" 1 "BMSAltngChrgCrntResp_1_CommandExecutedSuccessful" 2 "BMSAltngChrgCrntResp_2_Failed_EepromStorageFailed" 3 "BMSAltngChrgCrntResp_3_Failed_CurrentExceedChargerCapacity" 7 "BMSAltngChrgCrntResp_7_Failed_Others";
VAL_ 788 IBMSChrgTrgtSOCDspCmd 0 "BMSChrgTrgtSOCDspCmd_0_Default" 1 "BMSChrgTrgtSOCDspCmd_1_40percent" 2 "BMSChrgTrgtSOCDspCmd_2_50percent" 3 "BMSChrgTrgtSOCDspCmd_3_60percent" 4 "BMSChrgTrgtSOCDspCmd_4_70percent" 5 "BMSChrgTrgtSOCDspCmd_5_80percent" 6 "BMSChrgTrgtSOCDspCmd_6_90percent" 7 "BMSChrgTrgtSOCDspCmd_7_100percent";
VAL_ 788 IBMSChrgSpRsn 0 "BMSChrgSpRsn_0_No_Fault" 1 "BMSChrgSpRsn_1_Grid_Supply_Abnormal" 2 "BMSChrgSpRsn_2_Charging_Connector_Temperature_Abnormal" 3 "BMSChrgSpRsn_3_Charging_Connection_Abnormal" 4 "BMSChrgSpRsn_4_Charging_Station_Not_Up_To_Standard" 5 "BMSChrgSpRsn_5_ForeignMentalObjectIsDetected" 6 "BMSChrgSpRsn_6_LivingObjectIsDetected" 7 "BMSChrgSpRsn_7_Wireless_Charging_Station_Fault" 8 "BMSChrgSpRsn_8_Wireless_Charger_Wifi_Communication_Abnormal" 9 "BMSChrgSpRsn_9_Charging_Electric_Lock_Failure" 10 "BMSChrgSpRsn_10_WirelessChargerGroundAssemblyTemperatureTooHigh" 16 "BMSChrgSpRsn_16_OnboardChargingSystemAbnormal" 17 "BMSChrgSpRsn_17_OnboardCharger_Abnormal" 18 "BMSChrgSpRsn_18_Offboard_Charging_System_Abnormal" 19 "BMSChrgSpRsn_19_Wireless_Charging_System_Abnormal" 20 "BMSChrgSpRsn_20_Wireless_Charger_Abnormal" 21 "BMSChrgSpRsn_21_Cell_Temperature_Abnormal" 22 "BMSChrgSpRsn_22_Charging_Over_Current" 23 "BMSChrgSpRsn_23_Charging_Over_Voltage";
VAL_ 788 IBMSChrgOtptCrntReqV 0 "BMSChrgOtptCrntReqV_0_Valid" 1 "BMSChrgOtptCrntReqV_1_Invalid";
VAL_ 788 IBMSEstdElecRngV 0 "BMSEstdElecRngV_0_Valid" 1 "BMSEstdElecRngV_1_Invalid";
VAL_ 788 IBMSChrgCtrlResp 0 "BMSChrgCtrlResp_0_Default" 1 "BMSChrgCtrlResp_1_CommandExecutedSuccessful" 2 "BMSChrgCtrlResp_2_Failed_Notpluginchargegun" 3 "BMSChrgCtrlResp_3_Failed_Chargerunauthorized" 7 "BMSChrgCtrlResp_7_Failed_Others";
VAL_ 788 IBMSChrgCtrlDspCmd 0 "BMSChrgCtrlDspCmd_0_NoRequest" 1 "BMSChrgCtrlDspCmd_1_StartCharge" 2 "BMSChrgCtrlDspCmd_2_StopCharge" 3 "BMSChrgCtrlDspCmd_3_Reserved";
VAL_ 788 IBMSChrgSts 0 "BMSChrgSts_0_None" 1 "BMSChrgSts_1_OnboardCharging" 2 "BMSChrgSts_2_Charge_Done" 3 "BMSChrgSts_3_Balancing" 4 "BMSChrgSts_4_Charge_Fault" 5 "BMSChrgSts_5_Connecting" 6 "BMSChrgSts_6_Connected__not_Recognized" 7 "BMSChrgSts_7_Connected__not_Charged" 8 "BMSChrgSts_8_Charge_Cease" 9 "BMSChrgSts_9_Charge_Reserved" 10 "BMSChrgSts_10_Offboard_Charging" 11 "BMSChrgSts_11_Discharging_Gun_Connecting" 12 "BMSChrgSts_12_Multiple_Charging" 13 "BMSChrgSts_13_DisCharging" 14 "BMSChrgSts_14_DisCharging_cease" 15 "BMSChrgSts_15_Discharging_Done" 16 "BMSChrgSts_16_WirlessCharging";
VAL_ 788 IBMSChrgStsIO 0 "BMSChrgStsIO_0_Lamp_Off" 1 "BMSChrgStsIO_1_Charging_Lamp_On" 2 "BMSChrgStsIO_2_Discharging_Lamp_On" 3 "BMSChrgStsIO_3_Lamp_Flash";
VAL_ 788 IBMSAltngChrgCrntDspCmd 0 "BMSAltngChrgCrntDspCmd_0_Default" 1 "BMSAltngChrgCrntDspCmd_1_6A" 2 "BMSAltngChrgCrntDspCmd_2_8A" 3 "BMSAltngChrgCrntDspCmd_3_16A" 4 "BMSAltngChrgCrntDspCmd_4_MaxCurrent";
VAL_ 788 IBMSChrgTrgtSOCResp 0 "BMSChrgTrgtSOCResp_0_Default" 1 "BMSChrgTrgtSOCResp_1_CommandExecutedSuccessful" 2 "BMSChrgTrgtSOCResp_2_Failed_EepromStorageFailed" 7 "BMSChrgTrgtSOCResp_7_Failed_Others";
VAL_ 1249 IESS_NM_BSMtoRMS_PTCANFD 0 "ESS_NM_BSMtoRMS_PTCANFD_0_False" 1 "ESS_NM_BSMtoRMS_PTCANFD_1_True";
VAL_ 1249 IESS_NM_PBSMtoRMS_PTCANFD 0 "ESS_NM_PBSMtoRMS_PTCANFD_0_False" 1 "ESS_NM_PBSMtoRMS_PTCANFD_1_True";
VAL_ 1249 IESS_NM_RMStoNOS_PTCANFD 0 "ESS_NM_RMStoNOS_PTCANFD_0_False" 1 "ESS_NM_RMStoNOS_PTCANFD_1_True";
VAL_ 1249 IESS_NM_RSStoNOS_PTCANFD 0 "ESS_NM_RSStoNOS_PTCANFD_0_False" 1 "ESS_NM_RSStoNOS_PTCANFD_1_True";
VAL_ 1249 IESS_NM_RSStoRMS_PTCANFD 0 "ESS_NM_RSStoRMS_PTCANFD_0_False" 1 "ESS_NM_RSStoRMS_PTCANFD_1_True";
VAL_ 1249 IESS_NM_NOStoRMS_PTCANFD 0 "ESS_NM_NOStoRMS_PTCANFD_0_False" 1 "ESS_NM_NOStoRMS_PTCANFD_1_True";
VAL_ 1249 IESS_NM_NOSSta_PTCANFD 0 "ESS_NM_NOSSta_PTCANFD_0_False" 1 "ESS_NM_NOSSta_PTCANFD_1_True";
VAL_ 1249 IESS_NM_RMSSta_PTCANFD 0 "ESS_NM_RMSSta_PTCANFD_0_False" 1 "ESS_NM_RMSSta_PTCANFD_1_True";
VAL_ 1249 IESS_NWI_PTCANFD 0 "ESS_NWI_PTCANFD_0_NoWakeNetworkSource" 1 "BMS_NWI_PTCANFD_1_KL15orOBCWk" 3 "BMS_NWI_PTCANFD_3_ReserveChargeTimerExpired" 4 "BMS_NWI_PTCANFD_4_ThermalFaultActive" 6 "ESS_NWI_PTCANFD_6_PoweroffMonitoringCountdownEnd" 7 "ESS_NWI_PTCANFD_7_Level3AlarmTriggeredDuringPoweroffMonitoring";
VAL_ 1249 IESS_NOI_PTCANFD 0 "ESS_NOI_PTCANFD_0_NoRequest" 65535 "ESS_NOI_PTCANFD_65535_AllNetworkOperationActive";
VAL_ 1249 IESS_NKI_PTCANFD 0 "ESS_NKI_PTCANFD_0_NoRequest" 1 "ESS_NKI_PTCANFD_1_PowerModeIsNonOFF" 2 "ESS_NKI_PTCANFD_2_OnboardChargingOrWilessCharging" 4 "ESS_NKI_PTCANFD_4_OffboardCharging" 8 "ESS_NKI_PTCANFD_8_ThermalFaultActive" 16 "ESS_NKI_PTCANFD_16_ReservedCharging" 32 "ESS_NKI_PTCANFD_32_V2L" 64 "ESS_NKI_PTCANFD_64_Charging_Cooling" 256 "ESS_NKI_PTCANFD_256_PreCharging" 512 "ESS_NKI_PTCANFD_512_PoweroffMonitoringCountdownEnd" 1024 "ESS_NKI_PTCANFD_1024_Level3AlarmTriggeredDuringPoweroffMonitoring";
VAL_ 895 INarwSpcAstSwSts 0 "NarwSpcAstSwSts_0_Narwspcastswsts_0_Unavailable" 1 "NarwSpcAstSwSts_1_ON" 2 "NarwSpcAstSwSts_2_OFF";
VAL_ 895 INarwSpcAstBtnSts 0 "NarwSpcAstBtnSts_0_Off" 1 "NarwSpcAstBtnSts_1_OnlyForwardAvailable" 2 "NarwSpcAstBtnSts_2_OnlyBackwardAvailable" 3 "NarwSpcAstBtnSts_3_ForwardAndBackwardAvailable" 4 "NarwSpcAstBtnSts_4_Unavailable";
VAL_ 895 IIPD_VehLckCtrlReq 0 "VehLckCtrlReq_0_No_Request" 1 "VehLckCtrlReq_1_Interior_Unlock_Request" 2 "VehLckCtrlReq_2_Exterior_Unlock_Request" 3 "VehLckCtrlReq_3_Interior_Lock_Request" 4 "VehLckCtrlReq_4_Exterior_Lock_Request";
VAL_ 895 IRembParkngInPrmt 0 "RembParkngInPrmt_0_False" 1 "RembParkngInPrmt_1_True";
VAL_ 895 IRembParkngInMapngResp 0 "RembParkngInMapngResp_0_False" 1 "RembParkngInMapngResp_1_True";
VAL_ 895 IRembParkngInPrmtSwSts 0 "RembParkngInPrmtSwSts_0_Rembparknginprmtswsts_0_Unavailable" 1 "RembParkngInPrmtSwSts_1_ON" 2 "RembParkngInPrmtSwSts_2_OFF";
VAL_ 895 IRembParkngInMapngIndcr 0 "RembParkngInMapngIndcr_0_NoRequest" 1 "RembParkngInMapngIndcr_1_ParkingInMappingFailed" 2 "RembParkngInMapngIndcr_2_ParkingInManualRequest" 3 "RembParkngInMapngIndcr_3_ParkingOutRequest" 4 "RembParkngInMapngIndcr_4_ParkingOutMappingSucceed" 5 "RembParkngInMapngIndcr_5_RememberParkingFinished" 6 "RembParkngInMapngIndcr_6_MapIsBeingGenerated" 7 "RembParkngInMapngIndcr_7_ContinueScanningRequest";
VAL_ 895 IRembParkngInMapRutSeln 0 "RembParkngInMapRutSeln_0_NoRequest" 1 "RembParkngInMapRutSeln_1_Remember_Park_In" 2 "RembParkngInMapRutSeln_2_Remember_Park_Out" 3 "RembParkngInMapRutSeln_3_Reseverd" 4 "RembParkngInMapRutSeln_4_Reseverd" 5 "RembParkngInMapRutSeln_5_Reseverd" 6 "RembParkngInMapRutSeln_6_Reseverd" 7 "RembParkngInMapRutSeln_7_Reseverd";
VAL_ 895 IIPDMCUTemp 255 "IPDAurixTemp_255_Invalid_Value";
VAL_ 895 IIPDWtrClntInltReqFlg 0 "IPDWtrClntInltReqFlg_0_Request" 1 "IPDWtrClntInltReqFlg_1_No_Request";
VAL_ 895 ITrfGreenLghtActn 0 "TrfGreenLghtActn_0_NoDisplay" 1 "TrfGreenLghtActn_1_GreenLight_warning";
VAL_ 895 IRembParkngInMapngRutID 0 "RembParkngInMapngRutID_0_No_request" 1 "RembParkngInMapngRutID_1_First_map_for_Parking_In" 2 "RembParkngInMapngRutID_2_Second_map_for_Parking_In" 3 "RembParkngInMapngRutID_3_Third_map_for_Parking_In" 4 "RembParkngInMapngRutID_4_4th_map_for_Parking_In" 5 "RembParkngInMapngRutID_5_5th_map_for_Parking_In" 6 "RembParkngInMapngRutID_6_6th_map_for_Parking_In" 7 "RembParkngInMapngRutID_7_7th_map_for_Parking_In" 8 "RembParkngInMapngRutID_8_8th_map_for_Parking_In" 9 "RembParkngInMapngRutID_9_9th_map_for_Parking_In" 10 "RembParkngInMapngRutID_10_10th_map_for_Parking_In" 11 "RembParkngInMapngRutID_11_First_map_for_Parking_Out" 12 "RembParkngInMapngRutID_12_Second_map_for_Parking_Out" 13 "RembParkngInMapngRutID_13_Third_map_for_Parking_Out" 14 "RembParkngInMapngRutID_14_4th_map_for_Parking_Out" 15 "RembParkngInMapngRutID_15_5th_map_for_Parking_Out" 16 "RembParkngInMapngRutID_16_6th_map_for_Parking_Out" 17 "RembParkngInMapngRutID_17_7th_map_for_Parking_Out" 18 "RembParkngInMapngRutID_18_8th_map_for_Parking_Out" 19 "RembParkngInMapngRutID_19_9th_map_for_Parking_Out" 20 "RembParkngInMapngRutID_20_10th_map_for_Parking_Out";
VAL_ 895 IRembParkngInMapRutDltSeln 0 "RembParkngInMapRutDltSeln_0_NoRequest" 1 "RembParkngInMapRutDltSeln_1_MapRouteOne" 2 "RembParkngInMapRutDltSeln_2_MapRouteTwo" 3 "RembParkngInMapRutDltSeln_3_MapRouteThree" 4 "RembParkngInMapRutDltSeln_4_MapRouteFour" 5 "RembParkngInMapRutDltSeln_5_MapRouteFive" 6 "RembParkngInMapRutDltSeln_6_MapRouteSix" 7 "RembParkngInMapRutDltSeln_7_MapRouteSeven" 8 "RembParkngInMapRutDltSeln_8_MapRouteEight" 9 "RembParkngInMapRutDltSeln_9_MapRouteNine" 10 "RembParkngInMapRutDltSeln_10_MapRouteTen" 11 "RembParkngInMapRutDltSeln_11_MapRouteEleven" 12 "RembParkngInMapRutDltSeln_12_MapRouteTwelve" 13 "RembParkngInMapRutDltSeln_13_MapRouteThirteen" 14 "RembParkngInMapRutDltSeln_14_MapRouteFourteen" 15 "RembParkngInMapRutDltSeln_15_MapRouteFifteen";
VAL_ 382 IACCSdslReq 0 "ACCSdslReq_0_No_Request" 1 "ACCSdslReq_1_Request";
VAL_ 382 IACCGoReq 0 "ACCGoReq_0_NoRequest" 1 "ACCGoReq_1_Request";
VAL_ 382 IACCAccReqSts_CH 0 "ACCAccReqSts_CH_0_No_Request" 1 "ACCAccReqSts_CH_1_ACC_Acceleration_Request";
VAL_ 382 IACCSysFltSts 0 "ACCSysFltSts_0_NoError" 1 "ACCSysFltSts_1_PerformanceDegradation" 2 "ACCSysFltSts_2_SystemTemporaryUnvailable" 3 "ACCSysFltSts_3_ServiceRequired" 4 "ACCSysFltSts_4_Reserved" 5 "ACCSysFltSts_5_Reserved" 6 "ACCSysFltSts_6_Reserved" 7 "ACCSysFltSts_7_Reserved";
VAL_ 382 IACCSysSts 0 "ACCSysSts_0_Off" 1 "ACCSysSts_1_StandBy" 2 "ACCSysSts_2_Active" 3 "ACCSysSts_3_Override" 4 "ACCSysSts_4_BrakeOnly" 5 "ACCSysSts_5_StandstillActive" 6 "ACCSysSts_6_StandstillWait" 7 "ACCSysSts_7_Reserved";
VAL_ 736 IFrtMidRObsRng 0 "FrtMidRObsRng_0_NoObstacle" 1 "FrtMidRObsRng_1_Range1" 2 "FrtMidRObsRng_2_Range2" 3 "FrtMidRObsRng_3_Range3" 4 "FrtMidRObsRng_4_Range4" 5 "FrtMidRObsRng_5_Range5" 6 "FrtMidRObsRng_6_Range6" 7 "FrtMidRObsRng_7_Range7" 8 "FrtMidRObsRng_8_Range8" 9 "FrtMidRObsRng_9_Range9" 10 "FrtMidRObsRng_10_Range10" 11 "FrtMidRObsRng_11_Range11" 12 "FrtMidRObsRng_12_Range12" 13 "FrtMidRObsRng_13_Range13" 14 "FrtMidRObsRng_14_Range14" 15 "FrtMidRObsRng_15_Range15";
VAL_ 736 IFrtPDCAudWrnng 0 "FrtPDCAudWrnng_0_No_Obstacle" 1 "FrtPDCAudWrnng_1_Range_1" 2 "FrtPDCAudWrnng_2_Range_2" 3 "FrtPDCAudWrnng_3_Range_3" 4 "FrtPDCAudWrnng_4_Range_4" 5 "FrtPDCAudWrnng_5_Range_5" 6 "FrtPDCAudWrnng_6_Range_6" 7 "FrtPDCAudWrnng_7_Range_7" 8 "FrtPDCAudWrnng_8_Range_8" 9 "FrtPDCAudWrnng_9_Range_9" 10 "FrtPDCAudWrnng_10_Range_10" 11 "FrtPDCAudWrnng_11_Range_11" 12 "FrtPDCAudWrnng_12_Range_12" 13 "FrtPDCAudWrnng_13_Range_13" 14 "FrtPDCAudWrnng_14_Range_14" 15 "FrtPDCAudWrnng_15_Range_15";
VAL_ 736 IRrMidLObsRng 0 "RrMidLObsRng_0_NoObstacle" 1 "RrMidLObsRng_1_Range1" 2 "RrMidLObsRng_2_Range2" 3 "RrMidLObsRng_3_Range3" 4 "RrMidLObsRng_4_Range4" 5 "RrMidLObsRng_5_Range5" 6 "RrMidLObsRng_6_Range6" 7 "RrMidLObsRng_7_Range7" 8 "RrMidLObsRng_8_Range8" 9 "RrMidLObsRng_9_Range9" 10 "RrMidLObsRng_10_Range10" 11 "RrMidLObsRng_11_Range11" 12 "RrMidLObsRng_12_Range12" 13 "RrMidLObsRng_13_Range13" 14 "RrMidLObsRng_14_Range14" 15 "RrMidLObsRng_15_Range15";
VAL_ 736 IRLObsRng 0 "RLObsRng_0_NoObstacle" 1 "RLObsRng_1_Range1" 2 "RLObsRng_2_Range2" 3 "RLObsRng_3_Range3" 4 "RLObsRng_4_Range4" 5 "RLObsRng_5_Range5" 6 "RLObsRng_6_Range6" 7 "RLObsRng_7_Range7" 8 "RLObsRng_8_Range8" 9 "RLObsRng_9_Range9" 10 "RLObsRng_10_Range10" 11 "RLObsRng_11_Range11" 12 "RLObsRng_12_Range12" 13 "RLObsRng_13_Range13" 14 "RLObsRng_14_Range14" 15 "RLObsRng_15_Range15";
VAL_ 736 IRrMidRObsRng 0 "RrMidRObsRng_0_NoObstacle" 1 "RrMidRObsRng_1_Range1" 2 "RrMidRObsRng_2_Range2" 3 "RrMidRObsRng_3_Range3" 4 "RrMidRObsRng_4_Range4" 5 "RrMidRObsRng_5_Range5" 6 "RrMidRObsRng_6_Range6" 7 "RrMidRObsRng_7_Range7" 8 "RrMidRObsRng_8_Range8" 9 "RrMidRObsRng_9_Range9" 10 "RrMidRObsRng_10_Range10" 11 "RrMidRObsRng_11_Range11" 12 "RrMidRObsRng_12_Range12" 13 "RrMidRObsRng_13_Range13" 14 "RrMidRObsRng_14_Range14" 15 "RrMidRObsRng_15_Range15";
VAL_ 736 IPDCSysSts 0 "PDCSysSts_0_System_OK" 1 "PDCSysSts_1_System_initialization_sucessful" 2 "PDCSysSts_2_System_Failed" 3 "PDCSysSts_3_System_Disabled" 4 "PDCSysSts_4_Front_PDC_Disabled" 5 "PDCSysSts_5_Front_PDC_Failed" 6 "PDCSysSts_6_Rear_PDC_Failed" 7 "PDCSysSts_7_Rear_PDC_Disabled";
VAL_ 736 IFLSideObsRng 0 "FLSideObsRng_0_NoObstacle" 1 "FLSideObsRng_1_Range1" 2 "FLSideObsRng_2_Range2" 3 "FLSideObsRng_3_Range3" 4 "FLSideObsRng_4_Range4" 5 "FLSideObsRng_5_Range5" 6 "FLSideObsRng_6_Range6" 7 "FLSideObsRng_7_Range7" 8 "FLSideObsRng_8_Range8" 9 "FLSideObsRng_9_Range9" 10 "FLSideObsRng_10_Range10" 11 "FLSideObsRng_11_Range11" 12 "FLSideObsRng_12_Range12" 13 "FLSideObsRng_13_Range13" 14 "FLSideObsRng_14_Range14" 15 "FLSideObsRng_15_Range15";
VAL_ 736 IRrPDCAudWrnng 0 "RrPDCAudWrnng_0_No_Obstacle" 1 "RrPDCAudWrnng_1_Range_1" 2 "RrPDCAudWrnng_2_Range_2" 3 "RrPDCAudWrnng_3_Range_3" 4 "RrPDCAudWrnng_4_Range_4" 5 "RrPDCAudWrnng_5_Range_5" 6 "RrPDCAudWrnng_6_Range_6" 7 "RrPDCAudWrnng_7_Range_7" 8 "RrPDCAudWrnng_8_Range_8" 9 "RrPDCAudWrnng_9_Range_9" 10 "RrPDCAudWrnng_10_Range_10" 11 "RrPDCAudWrnng_11_Range_11" 12 "RrPDCAudWrnng_12_Range_12" 13 "RrPDCAudWrnng_13_Range_13" 14 "RrPDCAudWrnng_14_Range_14" 15 "RrPDCAudWrnng_15_Range_15";
VAL_ 736 IRLSideObsRng 0 "RLSideObsRng_0_NoObstacle" 1 "RLSideObsRng_1_Range1" 2 "RLSideObsRng_2_Range2" 3 "RLSideObsRng_3_Range3" 4 "RLSideObsRng_4_Range4" 5 "RLSideObsRng_5_Range5" 6 "RLSideObsRng_6_Range6" 7 "RLSideObsRng_7_Range7" 8 "RLSideObsRng_8_Range8" 9 "RLSideObsRng_9_Range9" 10 "RLSideObsRng_10_Range10" 11 "RLSideObsRng_11_Range11" 12 "RLSideObsRng_12_Range12" 13 "RLSideObsRng_13_Range13" 14 "RLSideObsRng_14_Range14" 15 "RLSideObsRng_15_Range15";
VAL_ 736 IFRSideObsRng 0 "FRSideObsRng_0_NoObstacle" 1 "FRSideObsRng_1_Range1" 2 "FRSideObsRng_2_Range2" 3 "FRSideObsRng_3_Range3" 4 "FRSideObsRng_4_Range4" 5 "FRSideObsRng_5_Range5" 6 "FRSideObsRng_6_Range6" 7 "FRSideObsRng_7_Range7" 8 "FRSideObsRng_8_Range8" 9 "FRSideObsRng_9_Range9" 10 "FRSideObsRng_10_Range10" 11 "FRSideObsRng_11_Range11" 12 "FRSideObsRng_12_Range12" 13 "FRSideObsRng_13_Range13" 14 "FRSideObsRng_14_Range14" 15 "FRSideObsRng_15_Range15";
VAL_ 736 IUndergndParkngGrgSts 0 "UndergndParkngGrgSts_0_Default" 1 "UndergndParkngGrgSts_1_In" 2 "UndergndParkngGrgSts_2_Reserved" 3 "UndergndParkngGrgSts_3_Reserved";
VAL_ 736 IRRSideObsRng 0 "RRSideObsRng_0_NoObstacle" 1 "RRSideObsRng_1_Range1" 2 "RRSideObsRng_2_Range2" 3 "RRSideObsRng_3_Range3" 4 "RRSideObsRng_4_Range4" 5 "RRSideObsRng_5_Range5" 6 "RRSideObsRng_6_Range6" 7 "RRSideObsRng_7_Range7" 8 "RRSideObsRng_8_Range8" 9 "RRSideObsRng_9_Range9" 10 "RRSideObsRng_10_Range10" 11 "RRSideObsRng_11_Range11" 12 "RRSideObsRng_12_Range12" 13 "RRSideObsRng_13_Range13" 14 "RRSideObsRng_14_Range14" 15 "RRSideObsRng_15_Range15";
VAL_ 736 IFLObsRng 0 "FLObsRng_0_NoObstacle" 1 "FLObsRng_1_Range1" 2 "FLObsRng_2_Range2" 3 "FLObsRng_3_Range3" 4 "FLObsRng_4_Range4" 5 "FLObsRng_5_Range5" 6 "FLObsRng_6_Range6" 7 "FLObsRng_7_Range7" 8 "FLObsRng_8_Range8" 9 "FLObsRng_9_Range9" 10 "FLObsRng_10_Range10" 11 "FLObsRng_11_Range11" 12 "FLObsRng_12_Range12" 13 "FLObsRng_13_Range13" 14 "FLObsRng_14_Range14" 15 "FLObsRng_15_Range15";
VAL_ 736 IRRObsRng 0 "RRObsRng_0_NoObstacle" 1 "RRObsRng_1_Range1" 2 "RRObsRng_2_Range2" 3 "RRObsRng_3_Range3" 4 "RRObsRng_4_Range4" 5 "RRObsRng_5_Range5" 6 "RRObsRng_6_Range6" 7 "RRObsRng_7_Range7" 8 "RRObsRng_8_Range8" 9 "RRObsRng_9_Range9" 10 "RRObsRng_10_Range10" 11 "RRObsRng_11_Range11" 12 "RRObsRng_12_Range12" 13 "RRObsRng_13_Range13" 14 "RRObsRng_14_Range14" 15 "RRObsRng_15_Range15";
VAL_ 736 IFRObsRng 0 "FRObsRng_0_NoObstacle" 1 "FRObsRng_1_Range1" 2 "FRObsRng_2_Range2" 3 "FRObsRng_3_Range3" 4 "FRObsRng_4_Range4" 5 "FRObsRng_5_Range5" 6 "FRObsRng_6_Range6" 7 "FRObsRng_7_Range7" 8 "FRObsRng_8_Range8" 9 "FRObsRng_9_Range9" 10 "FRObsRng_10_Range10" 11 "FRObsRng_11_Range11" 12 "FRObsRng_12_Range12" 13 "FRObsRng_13_Range13" 14 "FRObsRng_14_Range14" 15 "FRObsRng_15_Range15";
VAL_ 736 ILADSAFnInd 0 "LADSAFnInd_0_IDLE" 1 "LADSAFnInd_1_RADS" 2 "LADSAFnInd_2_ESSSwap_Park" 3 "LADSAFnInd_3_NPA" 4 "LADSAFnInd_4_AVP" 5 "LADSAFnInd_5_Remember_Build_Map" 6 "LADSAFnInd_6_Remember_Summon" 7 "LADSAFnInd_7_Remember_ParkIn" 8 "LADSAFnInd_8_RemoteOnekeyParkIn_Super" 9 "LADSAFnInd_9_ParkIn_super" 10 "LADSAFnInd_10_ParkIn" 11 "LADSAFnInd_11_ParkOut" 12 "LADSAFnInd_12_NRCD" 13 "LADSAFnInd_13_RemoteOnekeyParkIn" 14 "LADSAFnInd_14_RemoteOnekeyParkOut" 15 "LADSAFnInd_15_NCP";
VAL_ 736 IFrtMidLObsRng 0 "FrtMidLObsRng_0_NoObstacle" 1 "FrtMidLObsRng_1_Range1" 2 "FrtMidLObsRng_2_Range2" 3 "FrtMidLObsRng_3_Range3" 4 "FrtMidLObsRng_4_Range4" 5 "FrtMidLObsRng_5_Range5" 6 "FrtMidLObsRng_6_Range6" 7 "FrtMidLObsRng_7_Range7" 8 "FrtMidLObsRng_8_Range8" 9 "FrtMidLObsRng_9_Range9" 10 "FrtMidLObsRng_10_Range10" 11 "FrtMidLObsRng_11_Range11" 12 "FrtMidLObsRng_12_Range12" 13 "FrtMidLObsRng_13_Range13" 14 "FrtMidLObsRng_14_Range14" 15 "FrtMidLObsRng_15_Range15";
VAL_ 736 IFRSObsRng 0 "FRSObsRng1_0_NoObstacle" 1 "FRSObsRng1_1_Range1" 2 "FRSObsRng1_2_Range2" 3 "FRSObsRng1_3_Range3" 4 "FRSObsRng1_4_Range4" 5 "FRSObsRng1_5_Range5" 6 "FRSObsRng1_6_Range6" 7 "FRSObsRng1_7_Range7" 8 "FRSObsRng1_8_Range8" 9 "FRSObsRng1_9_Range9" 10 "FRSObsRng1_10_Range10" 11 "FRSObsRng1_11_Range11" 12 "FRSObsRng1_12_Range12" 13 "FRSObsRng1_13_Range13" 14 "FRSObsRng1_14_Range14" 15 "FRSObsRng1_15_Range15";
VAL_ 736 IFLSObsRng 0 "FLSObsRng1_0_NoObstacle" 1 "FLSObsRng1_1_Range1" 2 "FLSObsRng1_2_Range2" 3 "FLSObsRng1_3_Range3" 4 "FLSObsRng1_4_Range4" 5 "FLSObsRng1_5_Range5" 6 "FLSObsRng1_6_Range6" 7 "FLSObsRng1_7_Range7" 8 "FLSObsRng1_8_Range8" 9 "FLSObsRng1_9_Range9" 10 "FLSObsRng1_10_Range10" 11 "FLSObsRng1_11_Range11" 12 "FLSObsRng1_12_Range12" 13 "FLSObsRng1_13_Range13" 14 "FLSObsRng1_14_Range14" 15 "FLSObsRng1_15_Range15";
VAL_ 736 IRRSObsRng 0 "RRSObsRng1_0_NoObstacle" 1 "RRSObsRng1_1_Range1" 2 "RRSObsRng1_2_Range2" 3 "RRSObsRng1_3_Range3" 4 "RRSObsRng1_4_Range4" 5 "RRSObsRng1_5_Range5" 6 "RRSObsRng1_6_Range6" 7 "RRSObsRng1_7_Range7" 8 "RRSObsRng1_8_Range8" 9 "RRSObsRng1_9_Range9" 10 "RRSObsRng1_10_Range10" 11 "RRSObsRng1_11_Range11" 12 "RRSObsRng1_12_Range12" 13 "RRSObsRng1_13_Range13" 14 "RRSObsRng1_14_Range14" 15 "RRSObsRng1_15_Range15";
VAL_ 736 IRLSObsRng 0 "RLSObsRng1_0_NoObstacle" 1 "RLSObsRng1_1_Range1" 2 "RLSObsRng1_2_Range2" 3 "RLSObsRng1_3_Range3" 4 "RLSObsRng1_4_Range4" 5 "RLSObsRng1_5_Range5" 6 "RLSObsRng1_6_Range6" 7 "RLSObsRng1_7_Range7" 8 "RLSObsRng1_8_Range8" 9 "RLSObsRng1_9_Range9" 10 "RLSObsRng1_10_Range10" 11 "RLSObsRng1_11_Range11" 12 "RLSObsRng1_12_Range12" 13 "RLSObsRng1_13_Range13" 14 "RLSObsRng1_14_Range14" 15 "RLSObsRng1_15_Range15";
VAL_ 351 IAPAVCUReqSts 0 "APAVCUReqSts_0_NoRequest" 1 "APAVCUReqSts_1_RequestSpeedControl" 2 "APAVCUReqSts_2_RequestTorqueControl" 3 "APAVCUReqSts_3_Active" 4 "APAVCUReqSts_4_Reserved" 5 "APAVCUReqSts_5_Reserved" 6 "APAVCUReqSts_6_Reserved" 7 "APAVCUReqSts_7_Reserved";
VAL_ 351 IAPARevrDrgReq 0 "APARevrDrgReq_0_NoRequest" 1 "APARevrDrgReq_1_Request";
VAL_ 424 IAPASts 0 "APASts_0_Disable" 1 "APASts_1_Standby" 2 "APASts_2_SemiApaActive" 3 "APASts_3_FullyApaActive" 4 "APASts_4_Failed" 5 "APASts_5_Reserved" 6 "APASts_6_Reserved" 7 "APASts_7_Reserved";
VAL_ 424 IAutodDrvngSysSts 0 "AutodDrvngSysSts_0_Off" 1 "AutodDrvngSysSts_1_APA_Disable" 2 "AutodDrvngSysSts_2_APA_Standby" 3 "AutodDrvngSysSts_3_Semi_APA_Active" 4 "AutodDrvngSysSts_4_Fully_APA_Active" 5 "AutodDrvngSysSts_5_APA_Failed" 6 "AutodDrvngSysSts_6_Automated_driving_system_Disable" 7 "AutodDrvngSysSts_7_Automated_driving_system_Standby" 8 "AutodDrvngSysSts_8_Automated_driving_system_Failed" 9 "AutodDrvngSysSts_9_Automated_driving_system_active";
VAL_ 431 IACCDclReqSts 0 "ACCDclReqSts_0_No_Request" 1 "ACCDclReqSts_1_ACC_Deceleration_Request";
VAL_ 431 IACCOtptShaftTotToqReqSts 0 "ACCOtptShaftTotToqReqSts_0_NoRequest" 1 "ACCOtptShaftTotToqReqSts_1_TorqueRequest";
VAL_ 291 ISysPwrMdBkupV 0 "SysPwrMdBkupV_0_Valid" 1 "SysPwrMdBkupV_1_Invalid";
VAL_ 291 ISysPwrMdBkup 0 "SysPwrMdBkup_0_Off" 1 "SysPwrMdBkup_1_Accessory" 2 "SysPwrMdBkup_2_Run" 3 "SysPwrMdBkup_3_Crank_Request";
VAL_ 291 IUsgMdBkupV 0 "UsgMdBkupV_0_Invalid" 1 "UsgMdBkupV_1_Valid";
VAL_ 291 IUsgMdBkup 0 "UsgMdBkup_0_Sleep" 1 "UsgMdBkup_1_Standby" 2 "UsgMdBkup_2_Comfortable" 3 "UsgMdBkup_3_Driving" 4 "UsgMdBkup_4_AIParking" 5 "UsgMdBkup_5_AIPilot" 6 "UsgMdBkup_6_XOTA";
VAL_ 291 IVehMdBkupV 0 "VehMdBkupV_0_Invalid" 1 "VehMdBkupV_1_Valid";
VAL_ 291 IVehMdBkup 0 "VehMdBkup_0_NORMAL" 1 "VehMdBkup_1_CRASH" 2 "VehMdBkup_2_FACTORY" 3 "VehMdBkup_3_TRANSPORT" 4 "VehMdBkup_4_DYNO" 5 "VehMdBkup_5_EXHIBITION" 6 "VehMdBkup_6_Reserved" 7 "VehMdBkup_7_Reserved" 8 "VehMdBkup_8_Engineering" 9 "VehMdBkup_9_Service";
VAL_ 982 IACCDetObjTyp 0 "ACCDetObjTyp_0_Unknown" 1 "ACCDetObjTyp_1_Car" 2 "ACCDetObjTyp_2_Truck" 3 "ACCDetObjTyp_3_Motorbike" 4 "ACCDetObjTyp_4_Bicycle" 5 "ACCDetObjTyp_5_Reserved" 6 "ACCDetObjTyp_6_Reserved" 7 "ACCDetObjTyp_7_Reserved";
VAL_ 1202 IIPD_NM_BSMtoRMS_PTCANFD 0 "IPD_NM_BSMtoRMS_PTCANFD_0_IPD_NM_BSMtoRMS_0_False" 1 "IPD_NM_BSMtoRMS_PTCANFD_1_IPD_NM_BSMtoRMS_1_True";
VAL_ 1202 IIPD_NM_PBSMtoRMS_PTCANFD 0 "IPD_NM_PBSMtoRMS_PTCANFD_0_IPD_NM_PBSMtoRMS_0_False" 1 "IPD_NM_PBSMtoRMS_PTCANFD_1_IPD_NM_PBSMtoRMS_1_True";
VAL_ 1202 IIPD_NM_RMStoNOS_PTCANFD 0 "IPD_NM_RMStoNOS_PTCANFD_0_IPD_NM_RMStoNOS_0_False" 1 "IPD_NM_RMStoNOS_PTCANFD_1_IPD_NM_RMStoNOS_1_True";
VAL_ 1202 IIPD_NM_RSStoNOS_PTCANFD 0 "IPD_NM_RSStoNOS_PTCANFD_0_IPD_NM_RSStoNOS_0_False" 1 "IPD_NM_RSStoNOS_PTCANFD_1_IPD_NM_RSStoNOS_1_True";
VAL_ 1202 IIPD_NM_RSStoRMS_PTCANFD 0 "IPD_NM_RSStoRMS_PTCANFD_0_IPD_NM_RSStoRMS_0_False" 1 "IPD_NM_RSStoRMS_PTCANFD_1_IPD_NM_RSStoRMS_1_True";
VAL_ 1202 IIPD_NM_NOStoRMS_PTCANFD 0 "IPD_NM_NOStoRMS_PTCANFD_0_IPD_NM_NOStoRMS_0_False" 1 "IPD_NM_NOStoRMS_PTCANFD_1_IPD_NM_NOStoRMS_1_True";
VAL_ 1202 IIPD_NM_NOSSta_PTCANFD 0 "IPD_NM_NOSSta_PTCANFD_0_IPD_NM_NOSSta_0_False" 1 "IPD_NM_NOSSta_PTCANFD_1_IPD_NM_NOSSta_1_True";
VAL_ 1202 IIPD_NM_RMSSta_PTCANFD 0 "IPD_NM_RMSSta_PTCANFD_0_IPD_NM_RMSSta_0_False" 1 "IPD_NM_RMSSta_PTCANFD_1_IPD_NM_RMSSta_1_True";
VAL_ 1202 IIPD_NWI_PTCANFD 0 "IPD_NWI_PTCANFD_0_NoWakeNetworkSource" 1 "IPD_NWI_PTCANFD_1_PowerModeIsNonOFF" 2 "IPD_NWI_PTCANFD_2_OnboardChargerConnected";
VAL_ 1202 IIPD_NOI_PTCANFD 0 "IPD_NOI_PTCANFD_0_NoRequest" 65535 "IPD_NOI_PTCANFD_65535_AllNetworkOperationActive";
VAL_ 1202 IIPD_NKI_PTCANFD 0 "IPD_NKI_PTCANFD_0_NoRequest" 1 "IPD_NKI_PTCANFD_1_PowerModeIsNonOFF";
VAL_ 1170 IPEU_NM_BSMtoRMS_PTCANFD 0 "PEU_NM_BSMtoRMS_PTCANFD_0_False" 1 "PEU_NM_BSMtoRMS_PTCANFD_1_True";
VAL_ 1170 IPEU_NM_PBSMtoRMS_PTCANFD 0 "PEU_NM_PBSMtoRMS_PTCANFD_0_False" 1 "PEU_NM_PBSMtoRMS_PTCANFD_1_True";
VAL_ 1170 IPEU_NM_RMStoNOS_PTCANFD 0 "PEU_NM_RMStoNOS_PTCANFD_0_False" 1 "PEU_NM_RMStoNOS_PTCANFD_1_True";
VAL_ 1170 IPEU_NM_RSStoNOS_PTCANFD 0 "PEU_NM_RSStoNOS_PTCANFD_0_False" 1 "PEU_NM_RSStoNOS_PTCANFD_1_True";
VAL_ 1170 IPEU_NM_RSStoRMS_PTCANFD 0 "PEU_NM_RSStoRMS_PTCANFD_0_False" 1 "PEU_NM_RSStoRMS_PTCANFD_1_True";
VAL_ 1170 IPEU_NM_NOStoRMS_PTCANFD 0 "PEU_NM_NOStoRMS_PTCANFD_0_False" 1 "PEU_NM_NOStoRMS_PTCANFD_1_True";
VAL_ 1170 IPEU_NM_NOSSta_PTCANFD 0 "PEU_NM_NOSSta_PTCANFD_0_False" 1 "PEU_NM_NOSSta_PTCANFD_1_True";
VAL_ 1170 IPEU_NM_RMSSta_PTCANFD 0 "PEU_NM_RMSSta_PTCANFD_0_False" 1 "PEU_NM_RMSSta_PTCANFD_1_True";
VAL_ 1170 IPEU_NWI_PTCANFD 0 "PEU_NWI_PTCANFD_0_NoWakeNetworkSource";
VAL_ 1170 IPEU_NOI_PTCANFD 0 "PEU_NOI_PTCANFD_0_NoRequest" 65535 "PEU_NOI_PTCANFD_65535_AllNetworkOperationActive";
VAL_ 1170 IPEU_NKI_PTCANFD 0 "PEU_NKI_PTCANFD_0_NoRequest";
VAL_ 983 ITCSOpngMdVMC 0 "TCSOpngMdVMC_0_Off" 1 "TCSOpngMdVMC_1_Normal" 2 "TCSOpngMdVMC_2_OffRoad" 3 "TCSOpngMdVMC_3_TraceMd";
VAL_ 983 IPwrLftgtCtrlSrc 0 "PwrLftgtCtrlSrc_0_NoSource" 1 "PwrLftgtCtrlSrc_1_ExtrSwt" 2 "PwrLftgtCtrlSrc_2_KickSnsr" 3 "PwrLftgtCtrlSrc_3_ClsSwt" 4 "PwrLftgtCtrlSrc_4_HMI" 5 "PwrLftgtCtrlSrc_5_Invoice" 6 "PwrLftgtCtrlSrc_6_DKMM" 7 "PwrLftgtCtrlSrc_7_RmtCtrl" 8 "PwrLftgtCtrlSrc_8_WashMd" 9 "PwrLftgtCtrlSrc_9_UDS" 10 "PwrLftgtCtrlSrc_10_Onehit" 11 "PwrLftgtCtrlSrc_11_Reserved" 12 "PwrLftgtCtrlSrc_12_Reserved" 13 "PwrLftgtCtrlSrc_13_Reserved" 14 "PwrLftgtCtrlSrc_14_Reserved" 15 "PwrLftgtCtrlSrc_15_Reserved";
VAL_ 983 IACMdMotFaltSts_Rr 0 "ACMdMotFaltSts_Rr_0_Normal_or_SelfLearn_successful" 1 "ACMdMotFaltSts_Rr_1_Open" 2 "ACMdMotFaltSts_Rr_2_Short" 3 "ACMdMotFaltSts_Rr_3_Stall" 4 "ACMdMotFaltSts_Rr_4_No_SelfLearn" 5 "ACMdMotFaltSts_Rr_5_SelfLearning" 6 "ACMdMotFaltSts_Rr_6_SelfLearn_Failed" 7 "ACMdMotFaltSts_Rr_7_DigControl" 8 "ACMdMotFaltSts_Rr_8_Over_Temp" 9 "ACMdMotFaltSts_Rr_9_MotSensOpen" 10 "ACMdMotFaltSts_Rr_10_MotSensShort" 11 "ACMdMotFaltSts_Rr_11_LineRvs";
VAL_ 983 IVSEMdVMC 0 "VSEMdVMC_0_Off" 1 "VSEMdVMC_1_Normal" 2 "VSEMdVMC_2_Competitive" 3 "VSEMdVMC_3_TraceMd";
VAL_ 983 IOnBdChrgrSktNgtvSnsrTemV 0 "OnbdChrgrSktNgtvSnsrTemV_0_Valid" 1 "OnbdChrgrSktNgtvSnsrTemV_1_Invalid";
VAL_ 983 IOfbdChrgrPstvSktTemV 0 "OfbdChrgrPstvSktTemV_0_Valid" 1 "OfbdChrgrPstvSktTemV_1_Invalid";
VAL_ 983 IPwrLftgtCtrl 0 "PwrLftgtCtrl_0_NoRequest" 1 "PwrLftgtCtrl_1_PowerLiftGateUpperHalfOpenControl" 2 "PwrLftgtCtrl_2_PowerLiftGateUpperHalfCloseControl" 3 "PwrLftgtCtrl_3_PowerLiftGateUpperHalfStopControl" 4 "PwrLftgtCtrl_4_PowerLiftGateUpperHalfAutoDirectionControl_Reserved" 5 "PwrLftgtCtrl_5_PowerLiftGateLowerHalfOpenControl_Reserved" 6 "PwrLftgtCtrl_6_PowerLiftGateLowerHalfCloseControl_Reserved" 7 "PwrLftgtCtrl_7_PowerLiftGateLowerHalfStopControl_Reserved" 8 "PwrLftgtCtrl_8_PowerLiftGateLowerHalfAutoDirectionControl_Reserved" 9 "PwrLftgtCtrl_9_PowerLiftGateAllOpenControl_Reserved" 10 "PwrLftgtCtrl_10_PowerLiftGateAllCloseControl_Reserved" 11 "PwrLftgtCtrl_11_PowerLiftGateAllStopControl_Reserved" 12 "PwrLftgtCtrl_12_PowerLiftGateAllAuoDirectionControl_Reserved" 13 "PwrLftgtCtrl_13_Reserved" 14 "PwrLftgtCtrl_14_Reserved" 15 "PwrLftgtCtrl_15_Reserved";
VAL_ 983 IPwrLftgtThrmlSts 0 "PwrLftgtThrmlSts_0_Inactive" 1 "PwrLftgtThrmlSts_1_Active";
VAL_ 983 IPwrLftgtCinchLtchCtrl 0 "PwrLftgtCinchLtchCtrl_0_NoRequest" 1 "PwrLftgtCinchLtchCtrl_1_ReleaseRequest";
VAL_ 983 IPwrLftgtCinchLtchSts 0 "PwrLftgtCinchLtchSts_0_Locked" 1 "PwrLftgtCinchLtchSts_1_Standby" 2 "PwrLftgtCinchLtchSts_2_CinchStatus" 3 "PwrLftgtCinchLtchSts_3_ResetStatus";
VAL_ 983 IPwrLftgtCinchLtchThrmlSts 0 "PwrLftgtCinchLtchThrmlSts_0_Inactive" 1 "PwrLftgtCinchLtchThrmlSts_1_Active";
VAL_ 983 IPwrLftgtPnchSts 0 "PwrLftgtPnchSts_0_Inactive" 1 "PwrLftgtPnchSts_1_Active";
VAL_ 983 IPLGStpReason 0 "PLGStpReason_0_NoReason" 1 "PLGStpReason_1_StopByControl" 2 "PLGStpReason_2_StopByVehicleCondition" 3 "PLGStpReason_3_StopByObstacle" 4 "PLGStpReason_4_StopbyReachTargetPosition" 5 "PLGStpReason_5_StopByOverCurrent" 6 "PLGStpReason_6_Reserved" 7 "PLGStpReason_7_Reserved";
VAL_ 983 IPwrLftgtFailRmndr 0 "PwrLftgtFailRmndr_0_NoRmnd" 1 "PwrLftgtFailRmndr_1_OverSpeed" 2 "PwrLftgtFailRmndr_2_NotInPGear" 3 "PwrLftgtFailRmndr_3_SystemFault" 4 "PwrLftgtFailRmndr_4_SystemLimit" 5 "PwrLftgtFailRmndr_5_MaxPinchTimes" 6 "PwrLftgtFailRmndr_6_Reserved" 7 "PwrLftgtFailRmndr_7_Reserved";
SIG_GROUP_ 992 ICCU_100ms_Group07 1 : ICCUActiveWkup ICCUOnbdChrgrPlugOn ICCUOnbdChrgrPlugOnV ICCUOnbdChrgrSpRsn ICCU_100ms_Group07_CRC ICCU_100ms_Group07_RC ICCU_100ms_Group07_Reserved1 ICCU_100ms_Group07_Reserved10 ICCU_100ms_Group07_Reserved11 ICCU_100ms_Group07_Reserved2 ICCU_100ms_Group07_Reserved3 ICCU_100ms_Group07_Reserved4 ICCU_100ms_Group07_Reserved5 ICCU_100ms_Group07_Reserved6 ICCU_100ms_Group07_Reserved7 ICCU_100ms_Group07_Reserved8 ICCU_100ms_Group07_Reserved9 ICCUonbdChrgrMaxChrgPwr IOnBdChrgrAltrCrntInptCrnt IOnBdChrgrAltrCrntInptVol IOnBdChrgrCtrlPilotPWMDuty IOnBdChrgrCtrlPilotPWMSts IOnBdChrgrL1AltrCrntInptCrnt IOnBdChrgrL1AltrCrntInptVol IOnBdChrgrL2AltrCrntInptCrnt IOnBdChrgrL2AltrCrntInptVol IOnBdChrgrL3AltrCrntInptCrnt IOnBdChrgrL3AltrCrntInptVol IOnBdChrgrLastWkup IOnBdChrgrOtptVolV IOnBdChrgrSts IOnBdChrgrWkup IOnbdChrgrAltrCrntInptHVCrntLmt IOnbdChrgrOpngMd IOnbdChrgrOtptCrntV IOnbdChrgrOtptCrntVal IOnbdChrgrOtptVolVal;
SIG_GROUP_ 382 IICBAD_20ms_Group07 1 : IACCAccReqSts_CH IACCAccReqVal IACCGoReq IACCSdslReq IACCSysFltSts IACCSysSts IICBAD_20ms_Group07_CRC IICBAD_20ms_Group07_RC IICBAD_20ms_Group07_Reserved1 IICBAD_20ms_Group07_Reserved2 IICBAD_20ms_Group07_Reserved3 IICBAD_20ms_Group07_Reserved4 IICBAD_20ms_Group07_Reserved5 IICBAD_20ms_Group07_Reserved6;
SIG_GROUP_ 351 IICBAD_20ms_Group05 1 : IAPACrpSpdReqVal_IPD IAPARevrDrgReq IAPAToqReqVal IAPAVCUReqSts IICBAD_20ms_Group05_CRC IICBAD_20ms_Group05_RC IICBAD_20ms_Group05_Reserved1 IICBAD_20ms_Group05_Reserved2 IICBAD_20ms_Group05_Reserved3 IICBAD_20ms_Group05_Reserved4 IICBAD_20ms_Group05_Reserved5;
SIG_GROUP_ 424 IICBAD_20ms_Group12 1 : IAPASts IAutodDrvngSysSts IICBAD_20ms_Group12_CRC IICBAD_20ms_Group12_RC IICBAD_20ms_Group12_Reserved1 IICBAD_20ms_Group12_Reserved2 IICBAD_20ms_Group12_Reserved3 IICBAD_20ms_Group12_Reserved4 IICBAD_20ms_Group12_Reserved5 IICBAD_20ms_Group12_Reserved6;
SIG_GROUP_ 431 IICBAD_20ms_Group15 1 : IACCDclReqSts IACCOtptShaftTotToqReqSts IACCOtptShaftTotToqReqVal IICBAD_20ms_Group15_CRC IICBAD_20ms_Group15_RC IICBAD_20ms_Group15_Reserved1 IICBAD_20ms_Group15_Reserved10 IICBAD_20ms_Group15_Reserved2 IICBAD_20ms_Group15_Reserved3 IICBAD_20ms_Group15_Reserved4 IICBAD_20ms_Group15_Reserved5 IICBAD_20ms_Group15_Reserved6 IICBAD_20ms_Group15_Reserved7 IICBAD_20ms_Group15_Reserved8 IICBAD_20ms_Group15_Reserved9;
SIG_GROUP_ 291 IICBVC_20ms_Group05 1 : IICBVC_20ms_Group05_CRC IICBVC_20ms_Group05_RC IICBVC_20ms_Group05_Reserved1 IICBVC_20ms_Group05_Reserved2 IICBVC_20ms_Group05_Reserved3 IICBVC_20ms_Group05_Reserved4 IICBVC_20ms_Group05_Reserved5 IICBVC_20ms_Group05_Reserved6 IICBVC_20ms_Group05_Reserved7 ISysPwrMdBkup ISysPwrMdBkupV IUsgMdBkup IUsgMdBkupV IVehMdBkup IVehMdBkupV;
